VERSION ""

NS_ :

BS_:

BU_: GFM2_BCCMB ACCMB GFM3_DCACB FHCM SOBDMB_AWDC DCACA_GAS DCACA_HEV DCDC_LISB BCMC_CPDB DCMR_EAWD DCMR_ELSD BECMB_EPM PACM GFM_CPLR OBCC AFCM SOBDM_BCCM GWM _delete BCM ACCM GFM2_UIM ICM DCDC_HEV BECM SOBDMD_AHCM_PTC GENERIC TSTR

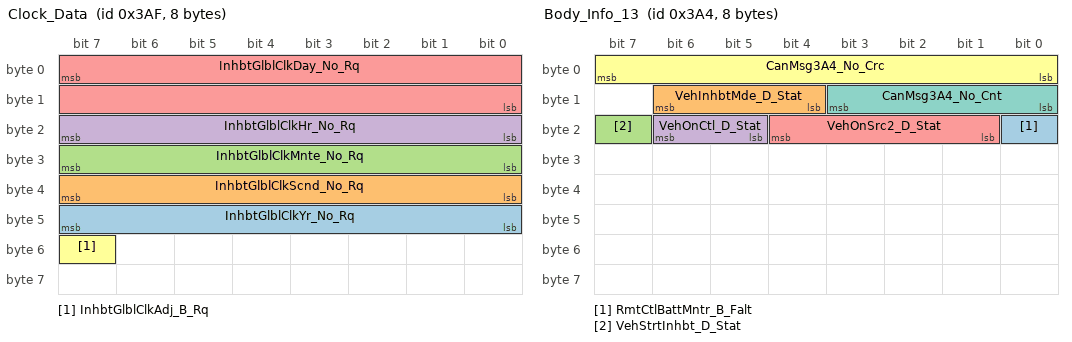
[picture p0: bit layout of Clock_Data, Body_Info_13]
BO_ 943 Clock_Data: 8 GWM
 SG_ InhbtGlblClkYr_No_Rq : 47|8@0+ (1,2000) [2000|2255] "year"  BCM
 SG_ InhbtGlblClkScnd_No_Rq : 39|8@0+ (1,0) [0|255] "second"  BCM
 SG_ InhbtGlblClkMnte_No_Rq : 31|8@0+ (1,0) [0|255] "minute"  BCM
 SG_ InhbtGlblClkHr_No_Rq : 23|8@0+ (1,0) [0|255] "hour"  BCM
 SG_ InhbtGlblClkDay_No_Rq : 7|16@0+ (1,0) [0|65535] "julian day"  BCM
 SG_ InhbtGlblClkAdj_B_Rq : 55|1@0+ (1,0) [0|1] "SED"  BCM

BO_ 932 Body_Info_13: 8 BCM
 SG_ RmtCtlBattMntr_B_Falt : 16|1@0+ (1,0) [0|1] "SED"  GWM
 SG_ VehInhbtMde_D_Stat : 14|3@0+ (1,0) [0|7] "SED"  GWM
 SG_ VehStrtInhbt_D_Stat : 23|1@0+ (1,0) [0|1] "SED"  BCMC_CPDB,GWM,PACM
 SG_ VehOnCtl_D_Stat : 22|2@0+ (1,0) [0|3] "SED"  BCMC_CPDB,GWM,PACM
 SG_ VehOnSrc2_D_Stat : 20|4@0+ (1,0) [0|15] "SED"  BCMC_CPDB,GWM
 SG_ CanMsg3A4_No_Crc : 7|8@0+ (1,0) [0|255] "Unitless"  GWM
 SG_ CanMsg3A4_No_Cnt : 11|4@0+ (1,0) [0|15] "Unitless"  GWM

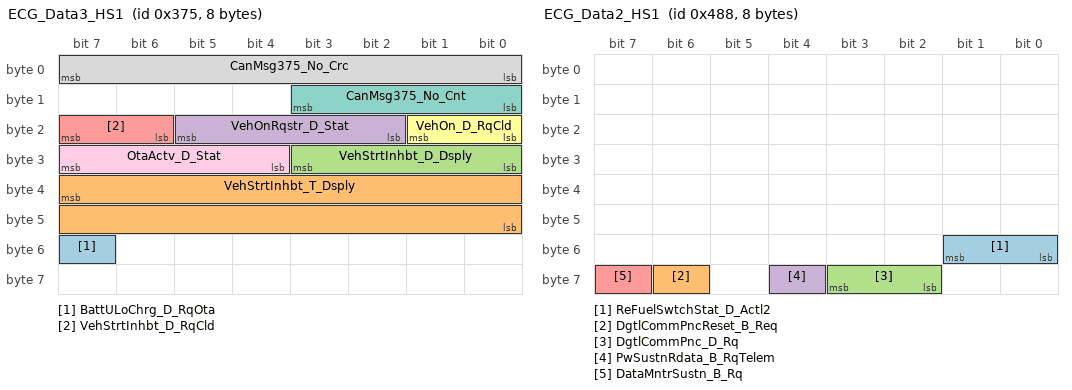
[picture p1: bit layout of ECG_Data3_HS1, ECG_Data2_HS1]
BO_ 885 ECG_Data3_HS1: 8 GWM
 SG_ BattULoChrg_D_RqOta : 55|1@0+ (1,0) [0|1] "SED"  BCM
 SG_ VehStrtInhbt_T_Dsply : 39|16@0+ (1,0) [0|65535] "second"  GENERIC
 SG_ VehStrtInhbt_D_Dsply : 27|4@0+ (1,0) [0|15] "SED"  GENERIC
 SG_ VehOnRqstr_D_Stat : 21|4@0+ (1,0) [0|15] "SED"  BCM
 SG_ VehStrtInhbt_D_RqCld : 23|2@0+ (1,0) [0|3] "SED"  BCM
 SG_ VehOn_D_RqCld : 17|2@0+ (1,0) [0|3] "SED"  BCM
 SG_ CanMsg375_No_Cnt : 11|4@0+ (1,0) [0|15] "unitless"  BCM
 SG_ CanMsg375_No_Crc : 7|8@0+ (1,0) [0|255] "unitless"  BCM
 SG_ OtaActv_D_Stat : 31|4@0+ (1,0) [0|15] "SED"  BCM

BO_ 159 OBCC_ECG_Word_Tx: 8 OBCC
 SG_ OBCC_ECG_Word_Tx : 7|64@0+ (1,0) [0|1.84467440737096E+019] "unitless"  GWM

BO_ 151 ECG_OBCC_Word_Tx: 8 GWM
 SG_ ECG_OBCC_Word_Tx : 7|64@0+ (1,0) [0|1.84467440737096E+019] "unitless"  OBCC

BO_ 1160 ECG_Data2_HS1: 8 GWM
 SG_ ReFuelSwtchStat_D_Actl2 : 49|2@0+ (1,0) [0|3] "SED"  GENERIC
 SG_ DgtlCommPncReset_B_Req : 62|1@0+ (1,0) [0|1] "SED"  OBCC
 SG_ DgtlCommPnc_D_Rq : 59|2@0+ (1,0) [0|3] "SED"  OBCC
 SG_ PwSustnRdata_B_RqTelem : 60|1@0+ (1,0) [0|1] "SED"  BECM,DCDC_HEV,SOBDM_BCCM
 SG_ DataMntrSustn_B_Rq : 63|1@0+ (1,0) [0|1] "SED"  BECM,DCDC_HEV,SOBDM_BCCM

BO_ 2612087000 PARSEDPushFcGWMtoBCM: 8 GWM
 SG_ PARSEDPushFcGWM_ECGtoBCM : 7|29@0+ (1,0) [0|536870911] "unitless"  BCM

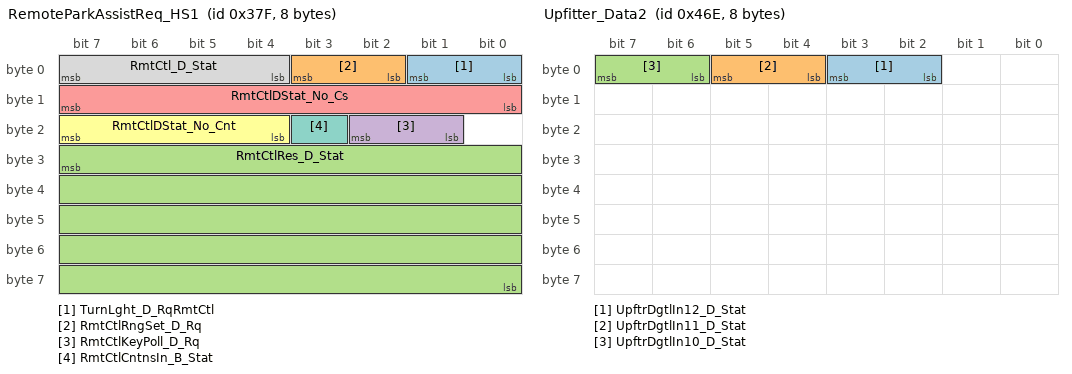
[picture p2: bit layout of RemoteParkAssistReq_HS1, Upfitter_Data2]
BO_ 895 RemoteParkAssistReq_HS1: 8 GWM
 SG_ TurnLght_D_RqRmtCtl : 1|2@0+ (1,0) [0|3] "SED"  BCM
 SG_ RmtCtlRngSet_D_Rq : 3|2@0+ (1,0) [0|3] "SED"  BCM
 SG_ RmtCtlRes_D_Stat : 31|40@0+ (1,0) [0|1099511627775] "unitless"  BCM
 SG_ RmtCtlKeyPoll_D_Rq : 18|2@0+ (1,0) [0|3] "SED"  BCM
 SG_ RmtCtlDStat_No_Cs : 15|8@0+ (1,0) [0|255] "Unitless"  BCM
 SG_ RmtCtlDStat_No_Cnt : 23|4@0+ (1,0) [0|15] "Unitless"  BCM
 SG_ RmtCtlCntnsIn_B_Stat : 19|1@0+ (1,0) [0|1] "SED"  BCM
 SG_ RmtCtl_D_Stat : 7|4@0+ (1,0) [0|15] "SED"  BCM

BO_ 542 LocationServices_3_HS1: 8 GWM
 SG_ LocationServices_3 : 7|64@0+ (1,0) [0|1.84467440737096E+019] "unitless" Vector__XXX

BO_ 1134 Upfitter_Data2: 8 GFM2_UIM
 SG_ UpftrDgtlIn12_D_Stat : 3|2@0+ (1,0) [0|3] "SED"  GWM
 SG_ UpftrDgtlIn11_D_Stat : 5|2@0+ (1,0) [0|3] "SED"  GWM
 SG_ UpftrDgtlIn10_D_Stat : 7|2@0+ (1,0) [0|3] "SED"  GWM

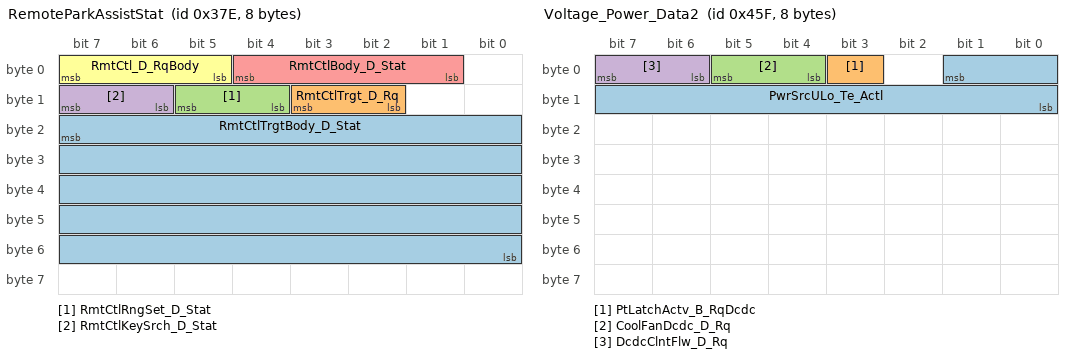
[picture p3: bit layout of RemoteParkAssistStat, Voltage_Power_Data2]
BO_ 894 RemoteParkAssistStat: 8 BCM
 SG_ RmtCtlTrgtBody_D_Stat : 23|40@0+ (1,0) [0|1099511627775] "unitless"  GWM
 SG_ RmtCtlTrgt_D_Rq : 11|2@0+ (1,0) [0|3] "SED"  GWM
 SG_ RmtCtlRngSet_D_Stat : 13|2@0+ (1,0) [0|3] "SED"  GWM
 SG_ RmtCtlKeySrch_D_Stat : 15|2@0+ (1,0) [0|3] "SED"  GWM
 SG_ RmtCtlBody_D_Stat : 4|4@0+ (1,0) [0|15] "SED"  GWM
 SG_ RmtCtl_D_RqBody : 7|3@0+ (1,0) [0|7] "SED"  GWM

BO_ 515 PowertrainData_12_HS1: 8 GWM
 SG_ PtIgnSwtch_D_Stat : 7|2@0+ (1,0) [0|3] "SED"  BCM

BO_ 1119 Voltage_Power_Data2: 8 DCDC_HEV
 SG_ PwrSrcULo_Te_Actl : 1|10@0+ (0.5,-50) [-50|460.5] "degC"  GWM
 SG_ PtLatchActv_B_RqDcdc : 3|1@0+ (1,0) [0|1] "SED"  GWM
 SG_ CoolFanDcdc_D_Rq : 5|2@0+ (1,0) [0|3] "SED"  GWM,BECM
 SG_ DcdcClntFlw_D_Rq : 7|2@0+ (1,0) [0|3] "SED"  SOBDMB_AWDC,GWM,BECM

BO_ 1827 TesterPhysicalReqBECMB_EPM: 8 TSTR
 SG_ TesterPhysicalReqBECMB_EPM : 7|64@0+ (1,0) [0|1.84467E+019] "unitless"  BECMB_EPM

BO_ 1835 TesterPhysicalResBECMB_EPM: 8 BECMB_EPM
 SG_ TesterPhysicalResBECMB_EPM : 7|64@0+ (1,0) [0|1.84467E+019] "unitless"  TSTR

BO_ 1110 Power_Stat: 8 BECMB_EPM
 SG_ RstrnMdulePw_D_Falt : 7|2@0+ (1,0) [0|3] "SED"  GWM

BO_ 1036 PedestrianAlert_Data: 8 PACM
 SG_ PdstrnAlrt_B_Falt : 7|1@0+ (1,0) [0|1] "SED"  GWM

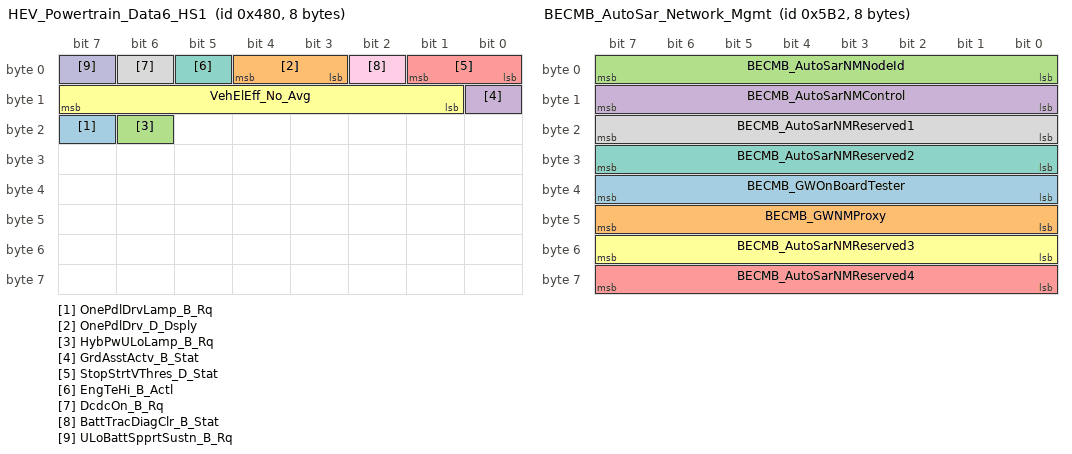
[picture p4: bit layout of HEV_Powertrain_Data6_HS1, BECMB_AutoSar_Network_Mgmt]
BO_ 1152 HEV_Powertrain_Data6_HS1: 8 GWM
 SG_ OnePdlDrvLamp_B_Rq : 23|1@0+ (1,0) [0|1] "SED"  GENERIC
 SG_ OnePdlDrv_D_Dsply : 4|2@0+ (1,0) [0|3] "SED"  GENERIC
 SG_ HybPwULoLamp_B_Rq : 22|1@0+ (1,0) [0|1] "SED"  DCDC_HEV
 SG_ GrdAsstActv_B_Stat : 8|1@0+ (1,0) [0|1] "SED" Vector__XXX
 SG_ StopStrtVThres_D_Stat : 1|2@0+ (1,0) [0|3] "SED"  GENERIC
 SG_ VehElEff_No_Avg : 15|7@0+ (10,-100) [-100|1150] "watt*hr/km" Vector__XXX
 SG_ EngTeHi_B_Actl : 5|1@0+ (1,0) [0|1] "SED" Vector__XXX
 SG_ DcdcOn_B_Rq : 6|1@0+ (1,0) [0|1] "SED"  DCDC_LISB,DCDC_HEV
 SG_ BattTracDiagClr_B_Stat : 2|1@0+ (1,0) [0|1] "SED"  BECM
 SG_ ULoBattSpprtSustn_B_Rq : 7|1@0+ (1,0) [0|1] "SED"  DCDC_LISB,BCMC_CPDB,BCM,BECM,DCDC_HEV,SOBDM_BCCM

BO_ 518 DifferentialCtrlData_1: 8 DCMR_ELSD
 SG_ LsdCluPlate_Te_Est : 23|9@0+ (1,-40) [-40|470] "degC"  GWM
 SG_ RearDiffLck_Tq_Actl2 : 7|14@0+ (1,0) [0|16381] "Nm"  GWM

BO_ 1458 BECMB_AutoSar_Network_Mgmt: 8 BECMB_EPM
 SG_ BECMB_GWOnBoardTester : 39|8@0+ (1,0) [0|255] "unitless"  BCM,GWM
 SG_ BECMB_GWNMProxy : 47|8@0+ (1,0) [0|255] "unitless"  BCM,GWM
 SG_ BECMB_AutoSarNMNodeId : 7|8@0+ (1,0) [0|255] "unitless"  GWM,BCM
 SG_ BECMB_AutoSarNMControl : 15|8@0+ (1,0) [0|255] "unitless"  BCM,GWM
 SG_ BECMB_AutoSarNMReserved4 : 63|8@0+ (1,0) [0|255] "unitless"  BCM,GWM
 SG_ BECMB_AutoSarNMReserved3 : 55|8@0+ (1,0) [0|255] "unitless"  BCM,GWM
 SG_ BECMB_AutoSarNMReserved2 : 31|8@0+ (1,0) [0|255] "unitless"  GWM,BCM
 SG_ BECMB_AutoSarNMReserved1 : 23|8@0+ (1,0) [0|255] "unitless"  GWM,BCM

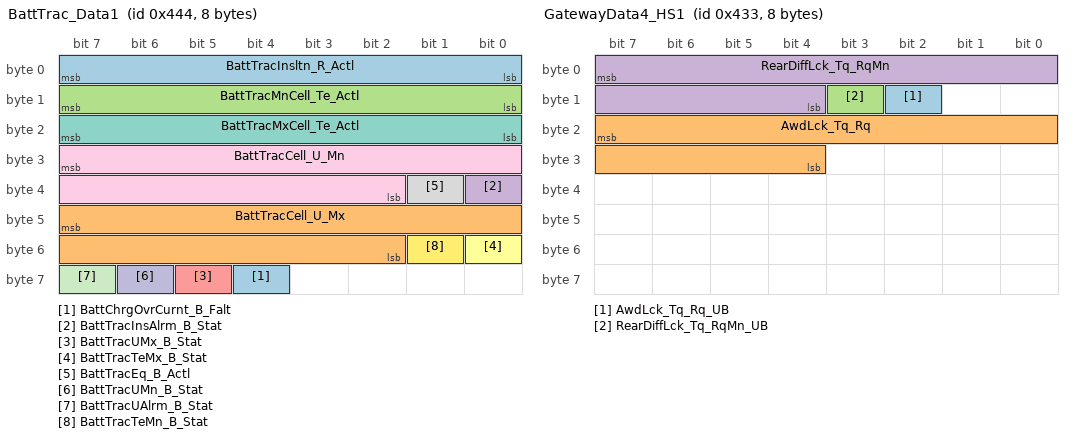
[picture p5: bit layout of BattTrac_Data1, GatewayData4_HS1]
BO_ 1092 BattTrac_Data1: 8 BECM
 SG_ BattChrgOvrCurnt_B_Falt : 60|1@0+ (1,0) [0|1] "SED"  OBCC
 SG_ BattTracCell_U_Mx : 47|14@0+ (0.001,0) [0|16.382] "volt"  GWM,OBCC
 SG_ BattTracMnCell_Te_Actl : 15|8@0+ (1,-40) [-40|213] "degC"  GWM,OBCC
 SG_ BattTracInsAlrm_B_Stat : 32|1@0+ (1,0) [0|1] "SED"  GWM
 SG_ BattTracUMx_B_Stat : 61|1@0+ (1,0) [0|1] "SED"  GWM,OBCC
 SG_ BattTracTeMx_B_Stat : 48|1@0+ (1,0) [0|1] "SED"  GWM
 SG_ BattTracMxCell_Te_Actl : 23|8@0+ (1,-40) [-40|213] "degC"  GWM,OBCC
 SG_ BattTracEq_B_Actl : 33|1@0+ (1,0) [0|1] "SED"  GWM
 SG_ BattTracCell_U_Mn : 31|14@0+ (0.001,0) [0|16.382] "volt"  GWM,OBCC
 SG_ BattTracUMn_B_Stat : 62|1@0+ (1,0) [0|1] "SED"  GWM,OBCC
 SG_ BattTracUAlrm_B_Stat : 63|1@0+ (1,0) [0|1] "SED"  GWM
 SG_ BattTracTeMn_B_Stat : 49|1@0+ (1,0) [0|1] "SED"  GWM
 SG_ BattTracInsltn_R_Actl : 7|8@0+ (6000,0) [0|1524000] "ohm"  GWM

BO_ 1075 GatewayData4_HS1: 8 GWM
 SG_ AwdLck_Tq_Rq_UB : 10|1@0+ (1,0) [0|1] "SED"  DCMR_ELSD
 SG_ AwdLck_Tq_Rq : 23|12@0+ (1,0) [0|4093] "Nm"  DCMR_ELSD
 SG_ RearDiffLck_Tq_RqMn_UB : 11|1@0+ (1,0) [0|1] "SED"  DCMR_ELSD
 SG_ RearDiffLck_Tq_RqMn : 7|12@0+ (4,0) [0|16376] "Nm"  DCMR_ELSD

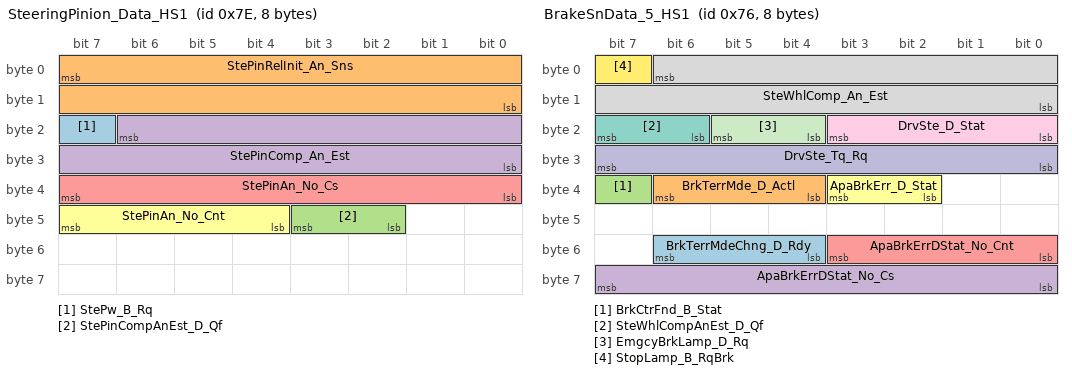
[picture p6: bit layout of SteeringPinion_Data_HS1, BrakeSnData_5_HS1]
BO_ 126 SteeringPinion_Data_HS1: 8 GWM
 SG_ StePw_B_Rq : 23|1@0+ (1,0) [0|1] "SED"  GENERIC
 SG_ StePinRelInit_An_Sns : 7|16@0+ (0.1,-3200) [-3200|3353.3] "degrees"  GENERIC
 SG_ StePinCompAnEst_D_Qf : 43|2@0+ (1,0) [0|3] "SED"  BCM,DCMR_ELSD
 SG_ StePinComp_An_Est : 22|15@0+ (0.1,-1600) [-1600|1676.7] "degrees"  BCM,DCMR_ELSD
 SG_ StePinAn_No_Cs : 39|8@0+ (1,0) [0|255] "Unitless"  GENERIC
 SG_ StePinAn_No_Cnt : 47|4@0+ (1,0) [0|15] "unitless"  GENERIC

BO_ 1872 TesterPhysicalReqPACM: 8 TSTR
 SG_ TesterPhysicalReqPACM : 7|64@0+ (1,0) [0|1.84467E+019] "unitless"  PACM

BO_ 1880 TesterPhysicalResPACM: 8 PACM
 SG_ TesterPhysicalResPACM : 7|64@0+ (1,0) [0|1.84467E+019] "unitless"  TSTR

BO_ 118 BrakeSnData_5_HS1: 8 GWM
 SG_ BrkTerrMdeChng_D_Rdy : 54|3@0+ (1,0) [0|7] "SED"  GENERIC
 SG_ BrkTerrMde_D_Actl : 38|3@0+ (1,0) [0|7] "SED"  GENERIC
 SG_ BrkCtrFnd_B_Stat : 39|1@0+ (1,0) [0|1] "SED"  GENERIC
 SG_ ApaBrkErrDStat_No_Cs : 63|8@0+ (1,0) [0|255] "Unitless"  GENERIC
 SG_ ApaBrkErrDStat_No_Cnt : 51|4@0+ (1,0) [0|15] "Unitless"  GENERIC
 SG_ ApaBrkErr_D_Stat : 35|2@0+ (1,0) [0|3] "SED"  GENERIC
 SG_ SteWhlCompAnEst_D_Qf : 23|2@0+ (1,0) [0|3] "SED"  BCM
 SG_ SteWhlComp_An_Est : 6|15@0+ (0.1,-1600) [-1600|1676.7] "deg"  BCM
 SG_ DrvSte_D_Stat : 19|4@0+ (1,0) [0|15] "SED"  GENERIC
 SG_ DrvSte_Tq_Rq : 31|8@0+ (0.0625,-8) [-8|7.8125] "Nm"  GENERIC
 SG_ EmgcyBrkLamp_D_Rq : 21|2@0+ (1,0) [0|3] "SED"  BCM
 SG_ StopLamp_B_RqBrk : 7|1@0+ (1,0) [0|1] "SED"  BCMC_CPDB,GFM2_UIM,BCM

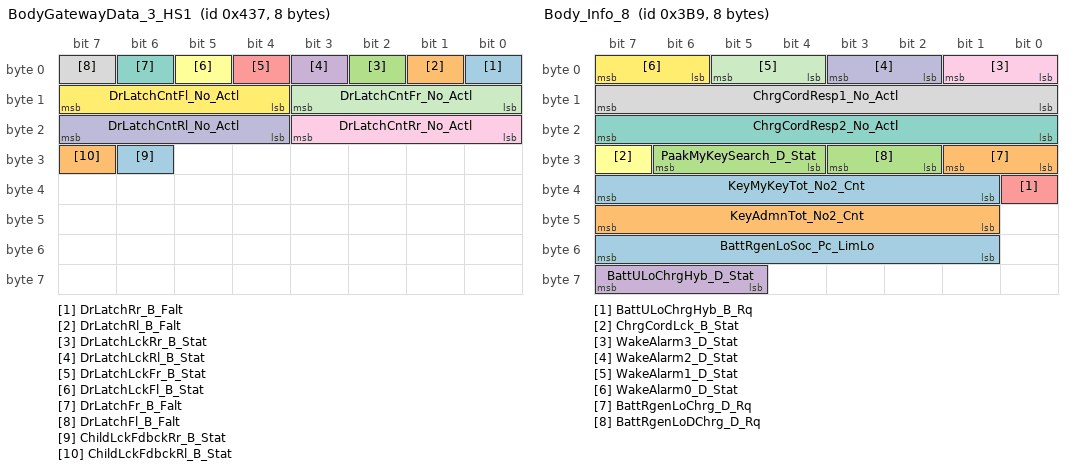
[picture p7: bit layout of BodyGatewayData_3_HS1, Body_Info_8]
BO_ 1079 BodyGatewayData_3_HS1: 8 GWM
 SG_ DrLatchRr_B_Falt : 0|1@0+ (1,0) [0|1] "SED"  BCM
 SG_ DrLatchRl_B_Falt : 1|1@0+ (1,0) [0|1] "SED"  BCM
 SG_ DrLatchLckRr_B_Stat : 2|1@0+ (1,0) [0|1] "SED"  BCM
 SG_ DrLatchLckRl_B_Stat : 3|1@0+ (1,0) [0|1] "SED"  BCM
 SG_ DrLatchLckFr_B_Stat : 4|1@0+ (1,0) [0|1] "SED"  BCM
 SG_ DrLatchLckFl_B_Stat : 5|1@0+ (1,0) [0|1] "SED"  BCM
 SG_ DrLatchFr_B_Falt : 6|1@0+ (1,0) [0|1] "SED"  BCM
 SG_ DrLatchFl_B_Falt : 7|1@0+ (1,0) [0|1] "SED"  BCM
 SG_ DrLatchCntRr_No_Actl : 19|4@0+ (1,0) [0|15] "unitless"  BCM
 SG_ DrLatchCntRl_No_Actl : 23|4@0+ (1,0) [0|15] "unitless"  BCM
 SG_ DrLatchCntFr_No_Actl : 11|4@0+ (1,0) [0|15] "unitless"  BCM
 SG_ DrLatchCntFl_No_Actl : 15|4@0+ (1,0) [0|15] "unitless"  BCM
 SG_ ChildLckFdbckRr_B_Stat : 30|1@0+ (1,0) [0|1] "SED"  BCM
 SG_ ChildLckFdbckRl_B_Stat : 31|1@0+ (1,0) [0|1] "SED"  BCM

BO_ 954 Body_Info_10: 8 BCM
 SG_ ExtLghtFront_D_RqBody : 61|2@0+ (1,0) [0|3] "SED"  GWM
 SG_ VehWlcmFrwlMde_D_Stat : 29|3@0+ (1,0) [0|7] "SED"  GWM
 SG_ CrtsyLghtRear_D_Stat : 63|2@0+ (1,0) [0|3] "SED"  GWM
 SG_ PosLghtFl_D_Stat : 51|2@0+ (1,0) [0|3] "SED"  GWM
 SG_ PosLghtFr_D_Stat : 49|2@0+ (1,0) [0|3] "SED"  GWM
 SG_ CargoLght_D_Stat : 55|2@0+ (1,0) [0|3] "SED"  GWM
 SG_ TlghtTestLght_D_Stat : 44|3@0+ (1,0) [0|7] "SED"  GWM
 SG_ LghtAmbDrvMde_B_Stat : 34|1@0+ (1,0) [0|1] "SED"  GWM
 SG_ KeylessIdl_B_Stat : 41|1@0+ (1,0) [0|1] "SED"  GWM
 SG_ PwRnngBoardPoll_D_Stat : 36|2@0+ (1,0) [0|3] "SED"  GWM
 SG_ GenericSwtch3_No_Actl : 15|3@0+ (1,0) [0|7] "unitless"  GWM
 SG_ GenericSwtch2_No_Actl : 4|3@0+ (1,0) [0|7] "unitless"  GWM
 SG_ GenericSwtch1_No_Actl : 7|3@0+ (1,0) [0|7] "unitless"  GWM
 SG_ PudSptLghtRight_D_Rq : 17|2@0+ (1,0) [0|3] "SED"  GWM
 SG_ PudSptLghtLeft_D_Rq : 19|2@0+ (1,0) [0|3] "SED"  GWM
 SG_ ExtLghtRight_D_Stat : 21|2@0+ (1,0) [0|3] "SED"  GWM
 SG_ PoliceDmngLvl_D_Stat : 39|3@0+ (1,0) [0|7] "SED"  GWM
 SG_ TrlrHitchLamp_D_Stat : 25|1@0+ (1,0) [0|1] "SED"  GWM
 SG_ LicPlateLght_B_Stat : 26|1@0+ (1,0) [0|1] "SED"  GWM
 SG_ TrukBedLght_B_Stat : 24|1@0+ (1,0) [0|1] "SED"  GWM
 SG_ VehWlcmFrwl_D_Stat : 31|2@0+ (1,0) [0|3] "SED"  GWM
 SG_ TlghtTestPrecnd_D_Stat : 47|3@0+ (1,0) [0|7] "SED"  GWM
 SG_ TlghtTest_D_Stat : 33|2@0+ (1,0) [0|3] "SED"  GWM
 SG_ ExtLghtRear_D_Stat : 23|2@0+ (1,0) [0|3] "SED"  GWM
 SG_ ExtLghtLeft_D_Stat : 9|2@0+ (1,0) [0|3] "SED"  GWM
 SG_ ExtLghtAlrt_B_Rq : 12|1@0+ (1,0) [0|1] "SED"  GWM
 SG_ ExtLght_D_Falt : 1|2@0+ (1,0) [0|3] "SED"  GWM
 SG_ ExtLghtFront_D_Stat : 11|2@0+ (1,0) [0|3] "SED"  GWM

BO_ 1118 BatteryCharge_Data2: 8 SOBDM_BCCM
 SG_ AcChrgRdy_B_Stat : 51|1@0+ (1,0) [0|1] "SED"  GWM,BECM
 SG_ DgtlCommGtwyMde_D_Rq : 48|4@0+ (1,0) [0|15] "SED"  GWM,OBCC
 SG_ ExtChrgNowButtn_B_Rq : 49|1@0+ (1,0) [0|1] "SED"  GWM
 SG_ CoolFanChrgr_D_Rq : 45|2@0+ (1,0) [0|3] "SED"  GWM,BECM
 SG_ ChrgrDcOvrVolt_B_Falt : 50|1@0+ (1,0) [0|1] "SED"  OBCC,GWM
 SG_ ChrgrDcOvrCurnt_B_Falt : 56|1@0+ (1,0) [0|1] "SED"  OBCC
 SG_ ChrgrPncEnbl_D_Stat : 58|2@0+ (1,0) [0|3] "SED"  GWM
 SG_ ChrgrClntFlw_D_Rq : 31|2@0+ (1,0) [0|3] "SED"  SOBDMB_AWDC,GWM,BECM
 SG_ PlgStatEvnt_B_Stat : 46|1@0+ (1,0) [0|1] "SED"  GWM,DCDC_LISB,DCDC_HEV,BECM
 SG_ ChrgrCnnctPwr_B_Stat : 47|1@0+ (1,0) [0|1] "SED"  GWM,BECM
 SG_ ChrgrAvailEvnt_B_Stat : 32|1@0+ (1,0) [0|1] "SED"  GWM,DCDC_LISB,DCDC_HEV,BECM
 SG_ ChrgrSrvcRqd_B_Rq : 0|1@0+ (1,0) [0|1] "SED"  GWM
 SG_ ChrgrS2Swtch_B_Stat : 42|1@0+ (1,0) [0|1] "SED"  GWM,OBCC
 SG_ ChrgChngEvnt_B_Stat : 33|1@0+ (1,0) [0|1] "SED"  GWM,DCDC_LISB,DCDC_HEV,BECM
 SG_ ChrgrCc2Cnnct_B_Falt : 59|1@0+ (1,0) [0|1] "SED"  GWM,OBCC
 SG_ ChrgPortDcTeMx_B_Falt : 60|1@0+ (1,0) [0|1] "SED"  GWM,OBCC
 SG_ ChrgCordLck_D_Stat : 7|3@0+ (1,0) [0|7] "SED"  GWM
 SG_ ChrgrInPwMde_D_Actl : 4|4@0+ (1,0) [0|15] "SED"  GWM,BECM,OBCC
 SG_ ChrgPortDrOpen_B_Stat : 43|1@0+ (1,0) [0|1] "SED"  GWM
 SG_ ChrgCordChlng2_No_Actl : 23|8@0+ (1,0) [0|255] "unitless"  GWM,BCM
 SG_ ChrgCordChlng1_No_Actl : 15|8@0+ (1,0) [0|255] "unitless"  GWM,BCM
 SG_ ChrgCrdLck_D_Falt : 41|2@0+ (1,0) [0|3] "SED"  GWM

BO_ 953 Body_Info_8: 8 BCM
 SG_ KeyMyKeyTot_No2_Cnt : 39|7@0+ (1,0) [0|127] "unitless"  GWM
 SG_ KeyAdmnTot_No2_Cnt : 47|7@0+ (1,0) [0|127] "unitless"  GWM
 SG_ PaakMyKeySearch_D_Stat : 30|3@0+ (1,0) [0|7] "SED"  GWM
 SG_ BattULoChrgHyb_D_Stat : 63|3@0+ (1,0) [0|7] "SED"  GWM
 SG_ BattULoChrgHyb_B_Rq : 32|1@0+ (1,0) [0|1] "SED"  GWM
 SG_ ChrgCordLck_B_Stat : 31|1@0+ (1,0) [0|1] "SED"  SOBDM_BCCM,GWM
 SG_ ChrgCordResp2_No_Actl : 23|8@0+ (1,0) [0|255] "unitless"  GWM,SOBDM_BCCM
 SG_ ChrgCordResp1_No_Actl : 15|8@0+ (1,0) [0|255] "unitless"  GWM,SOBDM_BCCM
 SG_ WakeAlarm3_D_Stat : 1|2@0+ (1,0) [0|3] "SED"  GWM,GENERIC
 SG_ WakeAlarm2_D_Stat : 3|2@0+ (1,0) [0|3] "SED"  GWM,GENERIC
 SG_ WakeAlarm1_D_Stat : 5|2@0+ (1,0) [0|3] "SED"  GWM,GENERIC
 SG_ WakeAlarm0_D_Stat : 7|2@0+ (1,0) [0|3] "SED"  GWM
 SG_ BattRgenLoSoc_Pc_LimLo : 55|7@0+ (1,0) [0|100] "percent"  DCDC_LISB
 SG_ BattRgenLoChrg_D_Rq : 25|2@0+ (1,0) [0|3] "SED"  DCDC_LISB,GWM
 SG_ BattRgenLoDChrg_D_Rq : 27|2@0+ (1,0) [0|3] "SED"  DCDC_LISB,GWM

BO_ 1112 Battery_Traction_6: 8 BECM
 SG_ BattTracIsoDis_B_Stat : 0|1@0+ (1,0) [0|1] "SED"  SOBDM_BCCM,GWM,OBCC
 SG_ BattTrac2_E_Max : 47|12@0+ (50,0) [0|204650] "watt*hour"  GWM
 SG_ BattTracHeat_D_Rq : 35|2@0+ (1,0) [0|3] "SED"  GWM
 SG_ BattTracDcFstSustn_B_Rq : 51|1@0+ (1,0) [0|1] "SED"  GWM
 SG_ BattDcCnnct_D_Cmd : 14|3@0+ (1,0) [0|7] "SED"  SOBDM_BCCM,GWM,OBCC
 SG_ BattTrac2_E_Avail : 31|12@0+ (50,0) [0|204650] "watt*hour"  GWM
 SG_ BattTracCnnct_D_Cmd : 18|3@0+ (1,0) [0|7] "SED"  SOBDMB_AWDC,SOBDM_BCCM,DCMR_EAWD,GWM
 SG_ BattTracHvilOpen_B_Stat : 8|1@0+ (1,0) [0|1] "SED"  GWM
 SG_ BattTracCoolLvl_D_Rq : 11|3@0+ (1,0) [0|7] "SED"  GWM
 SG_ CoolFanBatt_D_Rq : 23|5@0+ (1,0) [0|31] "unitless"  GWM
 SG_ BattTracTeSustn_B_Rq : 1|1@0+ (1,0) [0|1] "SED"  DCDC_LISB,GWM,BCMC_CPDB,BCM,DCDC_HEV,SOBDM_BCCM
 SG_ BattTracTeEvnt_B_Stat : 2|1@0+ (1,0) [0|1] "SED"  DCDC_LISB,GWM,DCDC_HEV,SOBDM_BCCM
 SG_ BattTracDcdcDis_B_Rq : 7|1@0+ (1,0) [0|1] "SED"  GWM
 SG_ BattChrgTrgtEvnt_B_Stat : 3|1@0+ (1,0) [0|1] "SED"  DCDC_LISB,GWM,DCDC_HEV,SOBDM_BCCM
 SG_ BattTracDiagClr_B_Rq : 15|1@0+ (1,0) [0|1] "SED"  GWM
 SG_ BattTracHazrd_D_Stat : 50|3@0+ (1,0) [0|7] "SED"  GWM
 SG_ BattTracChrgSustn_B_Rq : 4|1@0+ (1,0) [0|1] "SED"  DCDC_LISB,GWM,BCMC_CPDB,BCM,DCDC_HEV,SOBDM_BCCM
 SG_ HtrnClntPump_D_Stat : 6|2@0+ (1,0) [0|3] "SED"  DCDC_LISB,GWM,DCDC_HEV,SOBDM_BCCM
 SG_ BattTracDelta_Te_Actl : 63|8@0+ (0.5,-60) [-60|66.5] "degC" Vector__XXX
 SG_ BattTracClntPmp_D_Stat : 33|2@0+ (1,0) [0|3] "SED" Vector__XXX

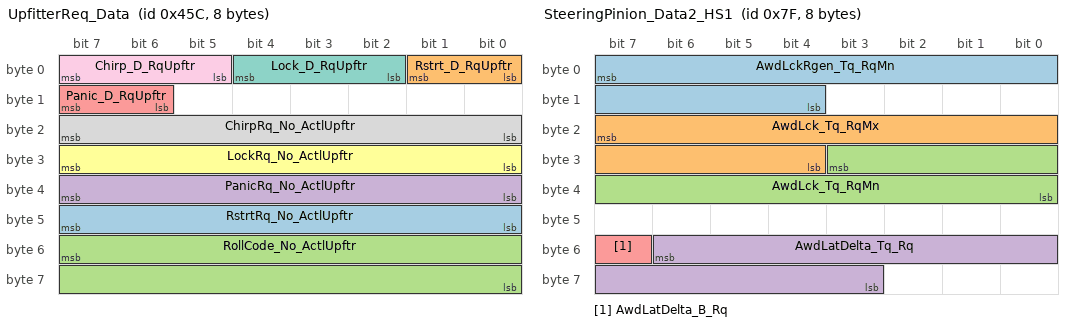
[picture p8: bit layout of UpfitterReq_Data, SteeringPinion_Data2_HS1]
BO_ 1116 UpfitterReq_Data: 8 GFM2_UIM
 SG_ RstrtRq_No_ActlUpftr : 47|8@0+ (1,0) [0|255] "unitless"  BCM
 SG_ Rstrt_D_RqUpftr : 1|2@0+ (1,0) [0|3] "SED"  BCM
 SG_ RollCode_No_ActlUpftr : 55|16@0+ (1,0) [0|65535] "unitless"  BCM
 SG_ PanicRq_No_ActlUpftr : 39|8@0+ (1,0) [0|255] "unitless"  BCM
 SG_ Panic_D_RqUpftr : 15|2@0+ (1,0) [0|3] "SED"  BCM
 SG_ LockRq_No_ActlUpftr : 31|8@0+ (1,0) [0|255] "unitless"  BCM
 SG_ Lock_D_RqUpftr : 4|3@0+ (1,0) [0|7] "SED"  BCM
 SG_ ChirpRq_No_ActlUpftr : 23|8@0+ (1,0) [0|255] "unitless"  BCM
 SG_ Chirp_D_RqUpftr : 7|3@0+ (1,0) [0|7] "SED"  BCM

BO_ 1144 MHT_EV_Wakeup: 8 GWM
 SG_ BattChrgTrgtSoC_D_Rq : 35|3@0+ (1,0) [0|7] "Percent"  GWM,BECM
 SG_ PreCondBatt_B_Actl : 32|1@0+ (1,0) [0|1] "SED"  GWM
 SG_ CabnEvapSovFront_B_Rq : 38|1@0+ (1,0) [0|1] "SED"  GWM,BCMC_CPDB
 SG_ HeatCoreSovRear_B_Rq : 36|1@0+ (1,0) [0|1] "SED"  GWM,BCMC_CPDB
 SG_ BattChlrSov_B_Rq : 39|1@0+ (1,0) [0|1] "SED"  GWM,BCMC_CPDB
 SG_ CabnEvapSovRear_B_Rq : 37|1@0+ (1,0) [0|1] "SED"  GWM,BCMC_CPDB
 SG_ BrkAppl_D_RqPt : 25|2@0+ (1,0) [0|3] "SED"  GWM
 SG_ BattClntVlvOvrrd_D_Rq : 31|2@0+ (1,0) [0|3] "SED"  GWM,BECM
 SG_ BattTracChillerOn_B_Rq : 27|1@0+ (1,0) [0|1] "SED"  GWM,BECM
 SG_ BattTracChiller_D_Stat : 29|2@0+ (1,0) [0|3] "SED"  GWM,BECM
 SG_ FstChrgCmplt_T_Est : 41|10@0+ (1,0) [0|1023] "minute"  OBCC
 SG_ ULoBattTrnsfrSustn_B_Rq : 43|1@0+ (1,0) [0|1] "SED"  SOBDM_BCCM,BCM,BECM,DCDC_HEV,GWM
 SG_ ULoBattTransfer_D_Stat : 46|3@0+ (1,0) [0|7] "SED"  BCM,GWM
 SG_ HtrnDcdcDis_B_Rq : 26|1@0+ (1,0) [0|1] "SED"  GWM
 SG_ HtrnCnnctPwr_B_Stat : 16|1@0+ (1,0) [0|1] "SED"  GWM,BECM,SOBDM_BCCM
 SG_ PtcHtr_D_Stat : 18|2@0+ (1,0) [0|3] "SED"  GWM
 SG_ BattChrgInhbt_D2_Rq : 63|3@0+ (1,0) [0|7] "SED"  BECM,SOBDM_BCCM
 SG_ WakeAlarm0_B_Typ : 21|1@0+ (1,0) [0|1] "SED"  GWM,BCM
 SG_ WakeAlarm0_T_Rq : 7|15@0+ (1,0) [0|32767] "minute"  GWM,BCM
 SG_ BattTracClimtDis_B_Stat : 42|1@0+ (1,0) [0|1] "SED"  GENERIC,GWM
 SG_ HtrnClntFlw_D_Rq : 20|2@0+ (1,0) [0|3] "SED"  SOBDMB_AWDC,GWM,DCMR_EAWD,BECM
 SG_ BattTracDrvSustn_B_Rq : 8|1@0+ (1,0) [0|1] "SED"  DCDC_LISB,GWM,BCMC_CPDB,BCM,BECM,DCDC_HEV,SOBDM_BCCM
 SG_ CabinDrvSustn_B_Rq : 23|1@0+ (1,0) [0|1] "SED"  DCDC_LISB,GWM,BCMC_CPDB,BCM,BECM,DCDC_HEV,SOBDM_BCCM
 SG_ BattTracClntVlv_B_Rq : 47|1@0+ (1,0) [0|1] "SED"  GWM,BCMC_CPDB
 SG_ ChrgNowEvnt_B_Stat : 22|1@0+ (1,0) [0|1] "SED"  DCDC_LISB,GWM,BECM,DCDC_HEV,SOBDM_BCCM

BO_ 127 SteeringPinion_Data2_HS1: 8 GWM
 SG_ AwdLckRgen_Tq_RqMn : 7|12@0+ (1,-4095) [-4095|0] "Nm"  GENERIC,SOBDMB_AWDC
 SG_ AwdLck_Tq_RqMx : 23|12@0+ (1,0) [0|4095] "Nm"  SOBDMB_AWDC,DCMR_EAWD
 SG_ AwdLck_Tq_RqMn : 27|12@0+ (1,0) [0|4095] "Nm"  SOBDMB_AWDC,DCMR_EAWD
 SG_ AwdLatDelta_Tq_Rq : 54|12@0+ (2,-4095) [-4095|4095] "Nm"  GENERIC
 SG_ AwdLatDelta_B_Rq : 55|1@0+ (1,0) [0|1] "SED"  GENERIC

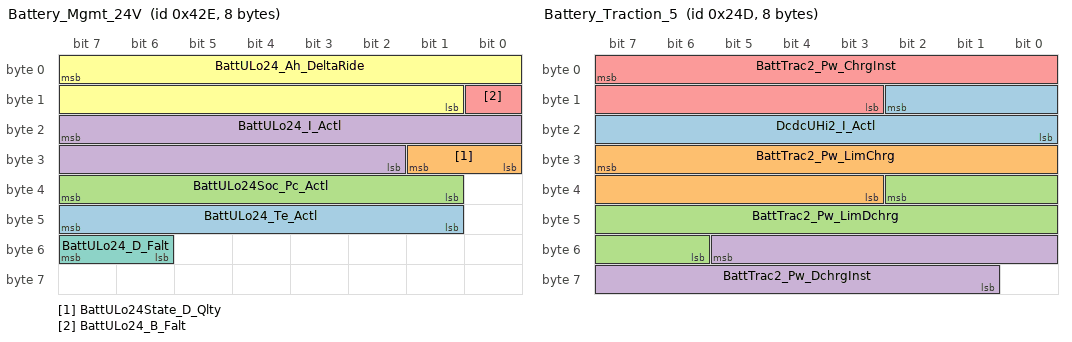
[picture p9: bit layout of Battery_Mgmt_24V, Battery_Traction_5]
BO_ 1070 Battery_Mgmt_24V: 8 BCM
 SG_ BattULo24_Te_Actl : 47|7@0+ (1,-40) [-40|86] "degC"  GWM
 SG_ BattULo24State_D_Qlty : 25|2@0+ (1,0) [0|3] "SED"  GWM
 SG_ BattULo24Soc_Pc_Actl : 39|7@0+ (1,0) [0|127] "percent"  GWM
 SG_ BattULo24_I_Actl : 23|14@0+ (0.0625,-512) [-512|511.875] "ampere"  GWM
 SG_ BattULo24_B_Falt : 8|1@0+ (1,0) [0|1] "SED"  GWM
 SG_ BattULo24_Ah_DeltaRide : 7|15@0+ (0.0078125,-100) [-100|155.9921875] "amperehour"  GWM
 SG_ BattULo24_D_Falt : 55|2@0+ (1,0) [0|3] "SED"  GWM

BO_ 589 Battery_Traction_5: 8 BECM
 SG_ DcdcUHi2_I_Actl : 10|11@0+ (0.1,0) [0|204.6] "ampere"  GWM
 SG_ BattTrac2_Pw_LimChrg : 31|13@0+ (50,0) [0|409550] "watts"  GWM
 SG_ BattTrac2_Pw_LimDchrg : 34|13@0+ (50,0) [0|409550] "watts"  GWM
 SG_ BattTrac2_Pw_DchrgInst : 53|13@0+ (50,0) [0|409550] "watts"  GWM
 SG_ BattTrac2_Pw_ChrgInst : 7|13@0+ (50,0) [0|409550] "watts"  GWM

BO_ 968 Cluster_Lighting_Rq_HS1: 8 GWM
 SG_ LnchCtl_N_Rq : 55|8@0+ (50,0) [0|12750] "rpm" Vector__XXX
 SG_ LnchCtl_D_Rq : 63|2@0+ (1,0) [0|3] "SED" Vector__XXX
 SG_ CurrentColor_CmdGage : 43|4@0+ (1,0) [0|15] "SED"  ICM
 SG_ BlendedColor_CmdGage : 25|2@0+ (1,0) [0|3] "SED"  ICM
 SG_ BlendColorRed_CmdGage : 47|4@0+ (1,0) [0|15] "SED"  ICM
 SG_ BlendColorGrn_CmdGage : 35|4@0+ (1,0) [0|15] "SED"  ICM
 SG_ BlendColorBlue_CmdGage : 39|4@0+ (1,0) [0|15] "SED"  ICM
 SG_ BrkDrvMde_D_Rq : 18|3@0+ (1,0) [0|7] "SED"  GENERIC
 SG_ Dimming_Level_Cmd : 1|2@0+ (1,0) [0|3] "SED"  GENERIC
 SG_ Current_Color_Cmd : 23|4@0+ (1,0) [0|15] "SED"  GENERIC
 SG_ BlendedColorRed_Cmd : 11|4@0+ (1,0) [0|15] "SED"  GENERIC
 SG_ BlendedColorGreen_Cmd : 15|4@0+ (1,0) [0|15] "SED"  GENERIC
 SG_ BlendedColorBlue_Cmd : 5|4@0+ (1,0) [0|15] "SED"  GENERIC
 SG_ BlendedColor_Cmd : 7|2@0+ (1,0) [0|3] "SED"  GENERIC
 SG_ SlMde_D_Rq : 27|2@0+ (1,0) [0|3] "SED" Vector__XXX
 SG_ IsaOffst_D_Rq : 31|4@0+ (1,0) [0|15] "SED" Vector__XXX
 SG_ SuspDrvMde_D_Rq : 61|3@0+ (1,0) [0|7] "SED"  GENERIC

BO_ 1081 GatewayData7_HS1: 8 GWM
 SG_ ChirpRq_No_ActlTrlr_UB : 35|1@0+ (1,0) [0|1] "SED"  BCM
 SG_ ChirpRq_No_ActlTrlr : 39|4@0+ (1,0) [0|15] "unitless"  BCM
 SG_ Chirp_D_RqTrlr_UB : 24|1@0+ (1,0) [0|1] "SED"  BCM
 SG_ Chirp_D_RqTrlr : 26|2@0+ (1,0) [0|3] "SED"  BCM
 SG_ RearPassWindowPos_UB : 8|1@0+ (1,0) [0|1] "SED"  BCM
 SG_ RearPassWindowPos : 11|3@0+ (1,0) [0|7] "SED"  BCM
 SG_ RearDriverWindowPos_UB : 12|1@0+ (1,0) [0|1] "SED"  BCM
 SG_ RearDriverWindowPos : 15|3@0+ (1,0) [0|7] "SED"  BCM
 SG_ PassWindowPosition_UB : 0|1@0+ (1,0) [0|1] "SED"  BCM
 SG_ PassWindowPosition : 3|3@0+ (1,0) [0|7] "SED"  BCM
 SG_ DriverWindowPosition_UB : 4|1@0+ (1,0) [0|1] "SED"  BCM
 SG_ DriverWindowPosition : 7|3@0+ (1,0) [0|7] "SED"  BCM
 SG_ ChrgCrdLckEnbl_B_Stat : 21|1@0+ (1,0) [0|1] "SED"  SOBDM_BCCM
 SG_ ChrgCrdLckEnbl_B_Stat_UB : 23|1@0+ (1,0) [0|1] "SED"  SOBDM_BCCM
 SG_ EcoInhbt_B_RqHvac_UB : 30|1@0+ (1,0) [0|1] "SED"  BCM
 SG_ EmgcyAsstActv_D_Stat_UB : 61|1@0+ (1,0) [0|1] "SED"  BCM
 SG_ EmgcyAsstActv_D_Stat : 63|2@0+ (1,0) [0|3] "SED"  BCM
 SG_ TrlrHitchLamp_D_Rq2_UB : 46|1@0+ (1,0) [0|1] "SED"  BCM
 SG_ TrlrHitchLamp_D_Rq2 : 47|1@0+ (1,0) [0|1] "SED"  BCM
 SG_ EcoInhbt_B_RqHvac : 31|1@0+ (1,0) [0|1] "SED"  BCM

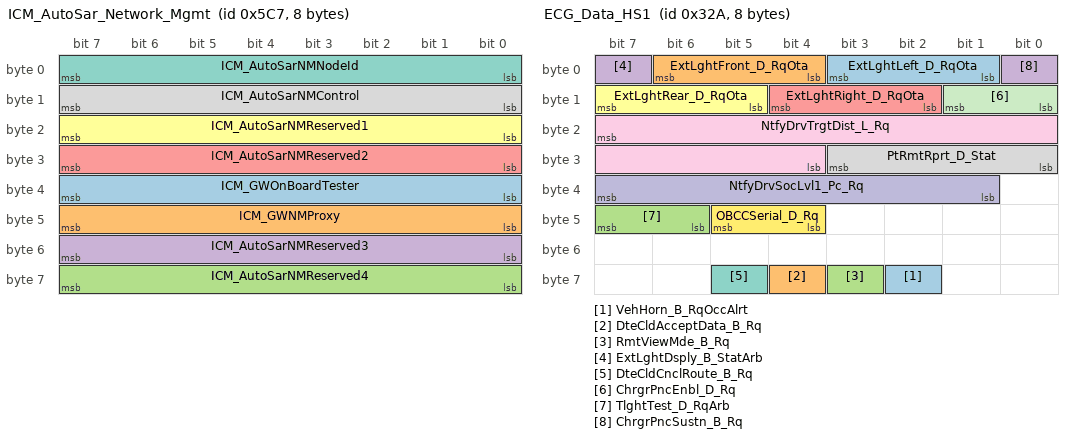
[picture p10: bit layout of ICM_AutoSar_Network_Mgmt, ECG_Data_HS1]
BO_ 1479 ICM_AutoSar_Network_Mgmt: 8 ICM
 SG_ ICM_GWOnBoardTester : 39|8@0+ (1,0) [0|255] "unitless"  GWM
 SG_ ICM_GWNMProxy : 47|8@0+ (1,0) [0|255] "unitless"  GWM
 SG_ ICM_AutoSarNMReserved4 : 63|8@0+ (1,0) [0|255] "unitless"  GWM
 SG_ ICM_AutoSarNMReserved3 : 55|8@0+ (1,0) [0|255] "unitless"  GWM
 SG_ ICM_AutoSarNMReserved2 : 31|8@0+ (1,0) [0|255] "unitless"  GWM
 SG_ ICM_AutoSarNMReserved1 : 23|8@0+ (1,0) [0|255] "unitless"  GWM
 SG_ ICM_AutoSarNMNodeId : 7|8@0+ (1,0) [0|255] "unitless"  GWM
 SG_ ICM_AutoSarNMControl : 15|8@0+ (1,0) [0|255] "unitless"  GWM

BO_ 1932 TesterPhysicalResICM: 8 ICM
 SG_ TesterPhysicalResICM : 7|64@0+ (1,0) [0|1.84467E+019] "unitless"  TSTR

BO_ 1924 TesterPhysicalReqICM: 8 TSTR
 SG_ TesterPhysicalReqICM : 7|64@0+ (1,0) [0|1.84467E+019] "unitless"  ICM

BO_ 829 Low_Voltage_Power_Dat2: 8 DCDC_HEV
 SG_ PwSrcULoMde2_D_Actl : 12|2@0+ (1,0) [0|3] "SED"  GWM,BECM
 SG_ DcdcUHi3_I_Actl : 7|11@0+ (0.1,0) [0|204.5] "ampere"  BECM,GWM

BO_ 910 CloudVehCtlData_Tp_Rq: 8 GWM
 SG_ CloudVehCtlData_Tp_Rq : 7|64@0+ (1,0) [0|1.84467440737096E+019] "unitless"  BCM

BO_ 911 CloudVehCtlData_Tp_Res: 8 BCM
 SG_ CloudVehCtlData_Tp_Res : 7|64@0+ (1,0) [0|1.84467440737096E+019] "unitless"  GWM

BO_ 2609984728 OTAPhysGWM_ECGtoOBCC: 8 GWM
 SG_ OTAPhysGWM_ECGtoOBCC : 7|29@0+ (1,0) [0|536870911] "unitless"  OBCC

BO_ 2610126925 OTAPhysOBCCtoGWM_ECG: 8 OBCC
 SG_ OTAPhysOBCCtoGWM_ECG : 7|29@0+ (1,0) [0|536870911] "unitless"  GWM

BO_ 1789 TesterPhysicalResOBCC: 8 OBCC
 SG_ TesterPhysicalResOBCC : 7|64@0+ (1,0) [0|1.84467E+019] "unitless"  TSTR

BO_ 1781 TesterPhysicalReqOBCC: 8 TSTR
 SG_ TesterPhysicalReqOBCC : 7|64@0+ (1,0) [0|1.84467E+019] "unitless"  OBCC

BO_ 2612224082 PARSEDPushBCMtoGWM_ECG: 8 BCM
 SG_ PARSEDPushBCMtoGWM_ECG : 7|29@0+ (1,0) [0|536870911] "unitless"  GWM

BO_ 2611175506 PARSEDPhysBCMtoGWM_ECG: 8 BCM
 SG_ PARSEDPhysBCMtoGWM_ECG : 7|29@0+ (1,0) [0|536870911] "unitless"  GWM

BO_ 2611038424 PARSEDPhysGWM_ECGtoBCM: 8 GWM
 SG_ PARSEDPhysGWM_ECGtoBCM : 7|29@0+ (1,0) [0|536870911] "unitless"  BCM

BO_ 2609989848 OTAPhysGWM_ECGtoBCM: 8 GWM
 SG_ OTAPhysGWM_ECGtoBCM : 7|29@0+ (1,0) [0|536870911] "unitless"  BCM

BO_ 2610126930 OTAPhysBCMtoGWM_ECG: 8 BCM
 SG_ OTAPhysBCMtoGWM_ECG : 7|29@0+ (1,0) [0|536870911] "unitless"  GWM

BO_ 1150 LocationServices_Data1_HS1: 8 GWM
 SG_ LocationServices_1 : 7|64@0+ (1,0) [0|1.84467440737096E+019] "unitless" Vector__XXX

BO_ 2610126914 OTAPhysBCMCtoGWM_ECG: 8 BCMC_CPDB
 SG_ OTAPhysBCMCtoGWM_ECG : 7|29@0+ (1,0) [0|536870911] "unitless"  GWM

BO_ 2609973464 OTAPhysGWM_ECGtoBCMC: 8 GWM
 SG_ OTAPhysGWM_ECGtoBCMC : 7|29@0+ (1,0) [0|536870911] "unitless"  BCMC_CPDB

BO_ 2612224062 PARSEDPushPACMtoGWM_ECG: 8 PACM
 SG_ PARSEDPushPACMtoGWM_ECG : 7|29@0+ (1,0) [0|536870911] "unitless"  GWM

BO_ 2611175486 PARSEDPhysPACMtoGWM_ECG: 8 PACM
 SG_ PARSEDPhysPACMtoGWM_ECG : 7|29@0+ (1,0) [0|536870911] "unitless"  GWM

BO_ 2611017944 PARSEDPhysGWM_ECGtoPACM: 8 GWM
 SG_ PARSEDPhysGWM_ECGtoPACM : 7|29@0+ (1,0) [0|536870911] "unitless"  PACM

BO_ 2612002008 PARSEDFuncGWM_ECG_HS1: 8 GWM
 SG_ PARSEDFuncGWM_ECG : 7|29@0+ (1,0) [0|536870911] "unitless"  SOBDMB_AWDC,ACCM,DCDC_LISB,BCM,BCMC_CPDB,PACM,OBCC,DCACA_GAS,DCACA_HEV

BO_ 2610953432 OTAFuncGWM_ECG_HS1: 8 GWM
 SG_ OTAFuncGWM_ECG : 7|29@0+ (1,0) [0|536870911] "unitless"  SOBDMB_AWDC,DCDC_LISB,BCM,BCMC_CPDB,PACM,OBCC,ACCM,DCACA_GAS,DCACA_HEV

BO_ 2611022040 PARSEDPhysGWM_ECGtoBCMC: 8 GWM
 SG_ PARSEDPhysGWM_ECGtoBCMC : 7|29@0+ (1,0) [0|536870911] "unitless"  BCMC_CPDB

BO_ 2612224066 PARSEDPushBCMCtoGWM_ECG: 8 BCMC_CPDB
 SG_ PARSEDPushBCMCtoGWM_ECG : 7|29@0+ (1,0) [0|536870911] "unitless"  GWM

BO_ 2609969368 OTAPhysGWM_ECGtoPACM: 8 GWM
 SG_ OTAPhysGWM_ECGtoPACM : 7|29@0+ (1,0) [0|536870911] "unitless"  PACM

BO_ 2610126910 OTAPhysPACMtoGWM_ECG: 8 PACM
 SG_ OTAPhysPACMtoGWM_ECG : 7|29@0+ (1,0) [0|536870911] "unitless"  GWM

BO_ 2611175490 PARSEDPhysBCMCtoGWM_ECG: 8 BCMC_CPDB
 SG_ PARSEDPhysBCMCtoGWM_ECG : 7|29@0+ (1,0) [0|536870911] "Unitless"  GWM

BO_ 811 APIM_Data_HS1: 8 GWM
 SG_ ExtLghtRight_D_RqMnu : 11|3@0+ (1,0) [0|7] "SED"  BCM
 SG_ ExtLghtRear_D_RqMnu : 14|3@0+ (1,0) [0|7] "SED"  BCM
 SG_ ExtLghtLeft_D_RqMnu : 1|3@0+ (1,0) [0|7] "SED"  BCM
 SG_ ExtLghtFront_D_RqMnu : 4|3@0+ (1,0) [0|7] "SED"  BCM
 SG_ SpeedoMajorUnit_D_Confg : 59|2@0+ (1,0) [0|3] "SED"  GENERIC
 SG_ ScMnSoc_Pc_RqMnu : 55|7@0+ (1,0) [0|125] "percent"  GENERIC
 SG_ ScEnbl_D_RqMnu : 57|2@0+ (1,0) [0|3] "SED"  GENERIC
 SG_ OnePdlDrvButtn_B_Falt : 16|1@0+ (1,0) [0|1] "SED"  GENERIC
 SG_ ExtLghtDsply_D_Stat : 7|3@0+ (1,0) [0|7] "SED"  GENERIC
 SG_ OnePdlDrvButtn_B_Stat : 48|1@0+ (1,0) [0|1] "SED"  GENERIC
 SG_ LongTermReset_B_RqMnu : 17|1@0+ (1,0) [0|1] "SED"  GENERIC
 SG_ GoTEditMnte_T_RqMnu : 63|4@0+ (1,0) [0|15] "SED"  GENERIC
 SG_ GoTEditHr_T_RqMnu : 44|5@0+ (1,0) [0|29] "SED"  GENERIC
 SG_ DistToStopover_L_Actl : 31|16@0+ (0.1,0) [0|6553.4] "kilometer"  GENERIC
 SG_ StopoverType_D_Stat : 47|3@0+ (1,0) [0|0] "SED"  GENERIC
 SG_ AutoLghtOvrrd_B_RqDrv : 8|1@0+ (1,0) [0|1] "SED"  BCM
 SG_ BecRleas_No_RqMnu : 23|3@0+ (1,0) [0|7] "unitless"  BCM
 SG_ TrnkFrontRleas_No_RqMnu : 20|3@0+ (1,0) [0|7] "unitless"  BCM

BO_ 810 ECG_Data_HS1: 8 GWM
 SG_ VehHorn_B_RqOccAlrt : 58|1@0+ (1,0) [0|1] "SED"  BCM
 SG_ DteCldAcceptData_B_Rq : 60|1@0+ (1,0) [0|1] "SED"  GENERIC
 SG_ RmtViewMde_B_Rq : 59|1@0+ (1,0) [0|1] "SED"  BCMC_CPDB
 SG_ ExtLghtDsply_B_StatArb : 7|1@0+ (1,0) [0|1] "SED"  BCM
 SG_ ExtLghtRight_D_RqOta : 12|3@0+ (1,0) [0|7] "SED"  BCM
 SG_ ExtLghtRear_D_RqOta : 15|3@0+ (1,0) [0|7] "SED"  BCM
 SG_ DteCldCnclRoute_B_Rq : 61|1@0+ (1,0) [0|1] "SED"  GENERIC
 SG_ PtRmtRprt_D_Stat : 27|4@0+ (1,0) [0|15] "SED"  GENERIC
 SG_ NtfyDrvTrgtDist_L_Rq : 23|12@0+ (0.1,0) [0|409.5] "Km"  GENERIC
 SG_ NtfyDrvSocLvl1_Pc_Rq : 39|7@0+ (1,0) [0|127] "%"  GENERIC
 SG_ ChrgrPncEnbl_D_Rq : 9|2@0+ (1,0) [0|3] "SED"  SOBDM_BCCM
 SG_ OBCCSerial_D_Rq : 45|2@0+ (1,0) [0|3] "SED"  OBCC
 SG_ ExtLghtLeft_D_RqOta : 3|3@0+ (1,0) [0|7] "SED"  BCM
 SG_ ExtLghtFront_D_RqOta : 6|3@0+ (1,0) [0|7] "SED"  BCM
 SG_ TlghtTest_D_RqArb : 47|2@0+ (1,0) [0|3] "SED"  BCM
 SG_ ChrgrPncSustn_B_Rq : 0|1@0+ (1,0) [0|1] "SED"  SOBDM_BCCM

BO_ 519 PowertrainData_8_HS1: 8 GWM
 SG_ RearDiffLck_Tq_Rq : 7|14@0+ (1,0) [0|16381] "Nm"  DCMR_ELSD

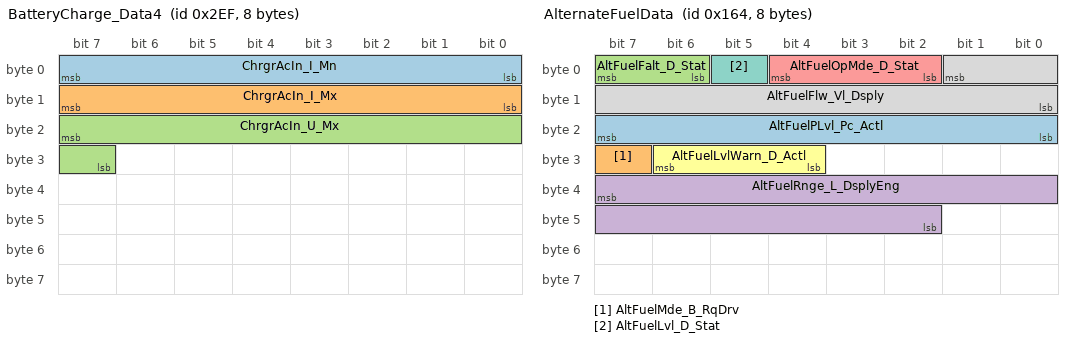
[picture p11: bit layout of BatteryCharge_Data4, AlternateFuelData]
BO_ 751 BatteryCharge_Data4: 8 SOBDM_BCCM
 SG_ ChrgrAcIn_I_Mn : 7|8@0+ (1,0) [0|255] "ampere"  OBCC
 SG_ ChrgrAcIn_I_Mx : 15|8@0+ (1,0) [0|255] "ampere"  OBCC
 SG_ ChrgrAcIn_U_Mx : 23|9@0+ (1,0) [0|511] "volt"  OBCC

BO_ 356 AlternateFuelData: 8 AFCM
 SG_ AltFuelPLvl_Pc_Actl : 23|8@0+ (0.471,0) [0|120.105] "percent"  GWM
 SG_ AltFuelMde_B_RqDrv : 31|1@0+ (1,0) [0|1] "SED"  GWM
 SG_ AltFuelFalt_D_Stat : 7|2@0+ (1,0) [0|3] "SED"  GWM
 SG_ AltFuelRnge_L_DsplyEng : 39|14@0+ (0.1,0) [0|1638.3] "kilometer"  GWM
 SG_ AltFuelOpMde_D_Stat : 4|3@0+ (1,0) [0|7] "SED"  GWM
 SG_ AltFuelLvlWarn_D_Actl : 30|3@0+ (1,0) [0|7] "SED"  GWM
 SG_ AltFuelLvl_D_Stat : 5|1@0+ (1,0) [0|1] "SED"  GWM
 SG_ AltFuelFlw_Vl_Dsply : 1|10@0+ (25,0) [0|25575] "micro_litre"  GWM

BO_ 2029 TesterPhysicalResAFCM: 8 AFCM
 SG_ TesterPhysicalResAFCM : 7|64@0+ (1,0) [0|1.84467E+019] "unitless"  TSTR

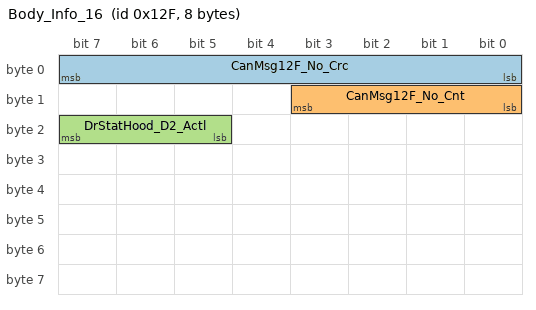
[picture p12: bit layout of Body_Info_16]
BO_ 303 Body_Info_16: 8 BCM
 SG_ CanMsg12F_No_Crc : 7|8@0+ (1,0) [0|255] "Unitless"  GWM,FHCM
 SG_ CanMsg12F_No_Cnt : 11|4@0+ (1,0) [0|15] "Unitless"  GWM,FHCM
 SG_ DrStatHood_D2_Actl : 23|3@0+ (1,0) [0|7] "SED"  GWM

BO_ 2612224034 PARSEDPushSOBDMBtoGWM_ECG: 8 SOBDMB_AWDC
 SG_ PARSEDPushSOBDMBtoGWM_ECG : 7|29@0+ (1,0) [0|536870911] "unitless"  GWM

BO_ 2612037848 PARSEDPushFcGWMECGtoSOBDMB: 8 GWM
 SG_ PARSEDPushFcGWMECGtoSOBDMB : 7|29@0+ (1,0) [0|536870911] "unitless"  SOBDMB_AWDC

BO_ 2611175458 PARSEDPhysSOBDMBtoGWM_ECG: 8 SOBDMB_AWDC
 SG_ PARSEDPhysSOBDMBtoGWM_ECG : 7|29@0+ (1,0) [0|536870911] "unitless"  GWM

BO_ 2610989272 PARSEDPhysGWM_ECGtoSOBDMB: 8 GWM
 SG_ PARSEDPhysGWM_ECGtoSOBDMB : 7|29@0+ (1,0) [0|536870911] "Unitless"  SOBDMB_AWDC

BO_ 2610126882 OTAPhysSOBDMBtoGWM_ECG: 8 SOBDMB_AWDC
 SG_ OTAPhysSOBDMBtoGWM_ECG : 7|29@0+ (1,0) [0|536870911] "unitless"  GWM

BO_ 2609940696 OTAPhysGWM_ECGtoSOBDMB: 8 GWM
 SG_ OTAPhysGWM_ECGtoSOBDMB : 7|29@0+ (1,0) [0|536870911] "unitless"  SOBDMB_AWDC

BO_TX_BU_ 1119 : DCDC_LISB,DCDC_HEV;
BO_TX_BU_ 1110 : BCM,BECMB_EPM;
CM_ BO_ 932 "NOTE: START BITS 8-11 MUST BE OPEN SPEC REQUIREMENT";
CM_ SG_ 932 CanMsg3A4_No_Crc "Signal not transmitted on gas and HEV variants.";
CM_ SG_ 932 CanMsg3A4_No_Cnt "Signal not transmitted on gas and HEV variants.";
CM_ BO_ 885 "NOTE: START BITS 8-11 MUST BE OPEN SPEC REQUIREMENT";
CM_ SG_ 159 OBCC_ECG_Word_Tx "MM ISO 15765-2 Message Catalogue RSE - AUDIO";
CM_ SG_ 151 ECG_OBCC_Word_Tx "MM ISO 15765-2 Message Catalogue AUDIO - RSE";
CM_ BO_ 1160 "some signals from HS4 0x22A TCU_EM in CGEA1.3";
CM_ SG_ 542 LocationServices_3 "Tx by HS3 APIM";
CM_ SG_ 1075 AwdLck_Tq_Rq "Signal not transmitted on programs that do not have AWD.";
CM_ SG_ 126 StePinRelInit_An_Sns "SASM will transmit these signals on vehicles with SASM and without PSCM.  SCCM will not Tx this signal when SASM is present.";
CM_ SG_ 126 StePinAn_No_Cs "Signal not transmitted on gas variants.";
CM_ SG_ 118 SteWhlCompAnEst_D_Qf "Legacy signal not supported, reserving bit locations for commodity BCM, PAM, RCM, APIM dbc files.  GWM to Tx Init value, no valid data. ";
CM_ SG_ 118 SteWhlComp_An_Est "Legacy signal not supported, reserving bit locations for commodity BCM, PAM, RCM, APIM dbc files.  GWM to Tx Init value, no valid data. ";
CM_ BO_ 1079 "Rolling counts indicate fresh data (DrLatchCntFl, Fr, Rl, Rr_No_Actl) and are updated each time new data is sent from a latch to BCM thru the GW. UBs not required.";
CM_ SG_ 1079 DrLatchCntRr_No_Actl "Rolling counts indicate fresh data (DrLatchCntxx) are updated each time new data is sent from a latch to BCM thru the GW. UBs not required.";
CM_ SG_ 1079 DrLatchCntRl_No_Actl "Rolling counts indicate fresh data (DrLatchCntxx) are updated each time new data is sent from a latch to BCM thru the GW. UBs not required.";
CM_ SG_ 1079 DrLatchCntFr_No_Actl "Rolling counts indicate fresh data (DrLatchCntxx) are updated each time new data is sent from a latch to BCM thru the GW. UBs not required.";
CM_ SG_ 1079 DrLatchCntFl_No_Actl "Rolling counts indicate fresh data (DrLatchCntxx) are updated each time new data is sent from a latch to BCM thru the GW. UBs not required.";
CM_ SG_ 954 GenericSwtch2_No_Actl "U625 Police Wig Wag feature";
CM_ SG_ 1112 BattTracClntPmp_D_Stat "48V mHEV: ECM_HEVDSL is Tx,  MHT HEV: PCM_HEV is Tx,  Powersplit HEV: SOBDMC_HPCM is Tx";
CM_ SG_ 910 CloudVehCtlData_Tp_Rq "MM ISO 15765-2 Message Catalogue RDISP2 - AUDIO";
CM_ SG_ 1150 LocationServices_1 "Tx by HS3 APIM";
CM_ SG_ 810 PtRmtRprt_D_Stat "Object.RemoteDataReport_St
";
CM_ SG_ 810 NtfyDrvTrgtDist_L_Rq "Object.SetTripRangeAlert_Rq
This signal is meant to provide the customer settings for the target distance remote notification";
CM_ SG_ 810 NtfyDrvSocLvl1_Pc_Rq "Object.SetCustomerLevelAlert_Rq
This signal is meant to provide the customer settings for the SOC remote notification.";
BA_DEF_ BO_  "FrameRouting" STRING ;
BA_DEF_ BO_  "FrameGatewayNetwork" STRING ;
BA_DEF_ BO_  "NetworkInitialization" ENUM  "No","Yes";
BA_DEF_ BO_  "FrameGatewayId" HEX 0 1407;
BA_DEF_ BO_  "EventRateOfChange" INT 10 10000;
BA_DEF_ BO_  "GenMsgStartDelayTime" INT 0 10000;
BA_DEF_ BO_  "GenMsgNrOfRepetition" INT 0 100;
BA_DEF_ BO_  "GenMsgDelayTime" INT 0 1000;
BA_DEF_ BO_  "GenMsgCycleTime" INT 0 100000;
BA_DEF_ BO_  "GenMsgSendType" ENUM  "FixedPeriodic","Event","EnabledPeriodic","NotUsed","NotUsed","EventPeriodic","NotUsed","NotUsed","NoMsgSendType";
BA_DEF_ SG_  "U_CD764_MY2022_Tx" ENUM  "No","Yes";
BA_DEF_ SG_  "U_U55X_MY2022_Tx" ENUM  "No","Yes";
BA_DEF_ SG_  "U_CD542_MY2021_Tx" ENUM  "No","Yes";
BA_DEF_ SG_  "ECGUsedTxSignal" ENUM  "No","Yes";
BA_DEF_ SG_  "U_T6_MCA_MY2020_Tx" ENUM  "No","Yes";
BA_DEF_ SG_  "U_P702_MY2021_Tx" ENUM  "No","Yes";
BA_DEF_ SG_  "U_CX727_MY2021_Tx" ENUM  "No","Yes";
BA_DEF_ SG_  "U_CD764_MY2022_Rx" ENUM  "No","Yes";
BA_DEF_ SG_  "U_U55X_MY2022_Rx" ENUM  "No","Yes";
BA_DEF_ SG_  "U_CD542_MY2021_Rx" ENUM  "No","Yes";
BA_DEF_ SG_  "ECGUsedRxSignal" ENUM  "No","Yes";
BA_DEF_ SG_  "U_T6_MCA_MY2020_Rx" ENUM  "No","Yes";
BA_DEF_ SG_  "U_P702_MY2021_Rx" ENUM  "No","Yes";
BA_DEF_ SG_  "U_CX727_MY2021_Rx" ENUM  "No","Yes";
BA_DEF_ SG_  "GenSigStartValue" HEX 0 268435455;
BA_DEF_ SG_  "MetaData" ENUM  "No","Yes";
BA_DEF_ SG_  "ContentDependant" ENUM  "No","Yes";
BA_DEF_ SG_  "GenSigStartValueInteger" INT 0 1000000000;
BA_DEF_ SG_  "UsedOnPgmDBC" ENUM  "No","Yes";
BA_DEF_ SG_  "WakeupSignal" ENUM  "No","Yes";
BA_DEF_ SG_  "GenSigInactiveValue" INT 0 100000;
BA_DEF_ SG_  "GenSigSendType" ENUM  "Cyclic","OnWrite","vector_leerstring","OnChange","vector_leerstring","IfActive","vector_leerstring","NoSigSendType";
BA_DEF_ BO_  "OvtpPushApplication" ENUM  "FALSE","TRUE";
BA_DEF_ BO_  "SCP_FreshnessValueLength" INT 0 512;
BA_DEF_ BO_  "SCP_FreshnessValueTxLength" INT 0 512;
BA_DEF_ BO_  "SCP_AuthInfoTxLength" INT 0 512;
BA_DEF_ BO_  "GenMsgRoutingTimeoutTime" INT 0 5000;
BA_DEF_ BO_  "MessageGateway" ENUM  "No","Yes";
BA_DEF_ BO_  "NmAsrMessage" ENUM  "No","Yes";
BA_DEF_ BO_  "TpApplType" STRING ;
BA_DEF_ BO_  "DiagState" ENUM  "No","Yes";
BA_DEF_ BO_  "TpTxIndex" INT 0 536870911;
BA_DEF_ BO_  "DiagRequest" ENUM  "No","Yes";
BA_DEF_ BO_  "DiagResponse" ENUM  "No","Yes";
BA_DEF_ BO_  "GenMsgILSupport" ENUM  "No","Yes";
BA_DEF_DEF_  "FrameRouting" "";
BA_DEF_DEF_  "FrameGatewayNetwork" "NONE";
BA_DEF_DEF_  "NetworkInitialization" "Yes";
BA_DEF_DEF_  "FrameGatewayId" 0;
BA_DEF_DEF_  "EventRateOfChange" 10000;
BA_DEF_DEF_  "GenMsgStartDelayTime" 0;
BA_DEF_DEF_  "GenMsgNrOfRepetition" 1;
BA_DEF_DEF_  "GenMsgDelayTime" 20;
BA_DEF_DEF_  "GenMsgCycleTime" 0;
BA_DEF_DEF_  "GenMsgSendType" "NoMsgSendType";
BA_DEF_DEF_  "U_CD764_MY2022_Tx" "No";
BA_DEF_DEF_  "U_U55X_MY2022_Tx" "No";
BA_DEF_DEF_  "U_CD542_MY2021_Tx" "No";
BA_DEF_DEF_  "ECGUsedTxSignal" "No";
BA_DEF_DEF_  "U_T6_MCA_MY2020_Tx" "No";
BA_DEF_DEF_  "U_P702_MY2021_Tx" "No";
BA_DEF_DEF_  "U_CX727_MY2021_Tx" "No";
BA_DEF_DEF_  "U_CD764_MY2022_Rx" "No";
BA_DEF_DEF_  "U_U55X_MY2022_Rx" "No";
BA_DEF_DEF_  "U_CD542_MY2021_Rx" "No";
BA_DEF_DEF_  "ECGUsedRxSignal" "No";
BA_DEF_DEF_  "U_T6_MCA_MY2020_Rx" "No";
BA_DEF_DEF_  "U_P702_MY2021_Rx" "No";
BA_DEF_DEF_  "U_CX727_MY2021_Rx" "No";
BA_DEF_DEF_  "GenSigStartValue" 0;
BA_DEF_DEF_  "MetaData" "No";
BA_DEF_DEF_  "ContentDependant" "No";
BA_DEF_DEF_  "GenSigStartValueInteger" 0;
BA_DEF_DEF_  "UsedOnPgmDBC" "Yes";
BA_DEF_DEF_  "WakeupSignal" "No";
BA_DEF_DEF_  "GenSigInactiveValue" 0;
BA_DEF_DEF_  "GenSigSendType" "NoSigSendType";
BA_DEF_DEF_  "OvtpPushApplication" "FALSE";
BA_DEF_DEF_  "SCP_FreshnessValueLength" 64;
BA_DEF_DEF_  "SCP_FreshnessValueTxLength" 11;
BA_DEF_DEF_  "SCP_AuthInfoTxLength" 53;
BA_DEF_DEF_  "GenMsgRoutingTimeoutTime" 0;
BA_DEF_DEF_  "MessageGateway" "No";
BA_DEF_DEF_  "NmAsrMessage" "No";
BA_DEF_DEF_  "TpApplType" "";
BA_DEF_DEF_  "DiagState" "No";
BA_DEF_DEF_  "TpTxIndex" 0;
BA_DEF_DEF_  "DiagRequest" "No";
BA_DEF_DEF_  "DiagResponse" "No";
BA_DEF_DEF_  "GenMsgILSupport" "Yes";
BA_ "GenMsgSendType" BO_ 943 1;
BA_ "GenMsgCycleTime" BO_ 932 200;
BA_ "GenMsgSendType" BO_ 932 0;
BA_ "GenMsgCycleTime" BO_ 885 200;
BA_ "GenMsgSendType" BO_ 885 0;
BA_ "TpTxIndex" BO_ 159 160;
BA_ "TpTxIndex" BO_ 151 160;
BA_ "GenMsgCycleTime" BO_ 1160 1000;
BA_ "GenMsgSendType" BO_ 1160 5;
BA_ "NetworkInitialization" BO_ 2612087000 0;
BA_ "GenMsgDelayTime" BO_ 2612087000 0;
BA_ "GenMsgSendType" BO_ 2612087000 1;
BA_ "OvtpPushApplication" BO_ 2612087000 1;
BA_ "TpTxIndex" BO_ 2612087000 463569112;
BA_ "FrameRouting" BO_ 895 "HS4_CAN,0x37F;";
BA_ "FrameGatewayNetwork" BO_ 895 "HS4_CAN";
BA_ "FrameGatewayId" BO_ 895 895;
BA_ "FrameRouting" BO_ 542 "HS4_CAN,0x21E;";
BA_ "FrameGatewayNetwork" BO_ 542 "HS4_CAN";
BA_ "FrameGatewayId" BO_ 542 542;
BA_ "GenMsgCycleTime" BO_ 1134 1000;
BA_ "GenMsgSendType" BO_ 1134 5;
BA_ "GenMsgCycleTime" BO_ 894 200;
BA_ "GenMsgSendType" BO_ 894 5;
BA_ "FrameRouting" BO_ 515 "FD1_CAN,0x203;";
BA_ "FrameGatewayNetwork" BO_ 515 "FD1_CAN";
BA_ "FrameGatewayId" BO_ 515 515;
BA_ "GenMsgCycleTime" BO_ 1119 1000;
BA_ "GenMsgSendType" BO_ 1119 5;
BA_ "NetworkInitialization" BO_ 1827 0;
BA_ "GenMsgDelayTime" BO_ 1827 0;
BA_ "GenMsgSendType" BO_ 1827 1;
BA_ "DiagRequest" BO_ 1827 1;
BA_ "GenMsgILSupport" BO_ 1827 0;
BA_ "NetworkInitialization" BO_ 1835 0;
BA_ "GenMsgDelayTime" BO_ 1835 0;
BA_ "GenMsgSendType" BO_ 1835 1;
BA_ "DiagResponse" BO_ 1835 1;
BA_ "GenMsgILSupport" BO_ 1835 0;
BA_ "GenMsgCycleTime" BO_ 1110 1000;
BA_ "GenMsgSendType" BO_ 1110 0;
BA_ "GenMsgCycleTime" BO_ 1036 1000;
BA_ "GenMsgSendType" BO_ 1036 5;
BA_ "FrameRouting" BO_ 1152 "FD1_CAN,0x480;";
BA_ "FrameGatewayNetwork" BO_ 1152 "FD1_CAN";
BA_ "FrameGatewayId" BO_ 1152 1152;
BA_ "GenMsgCycleTime" BO_ 518 50;
BA_ "GenMsgSendType" BO_ 518 0;
BA_ "NetworkInitialization" BO_ 1458 0;
BA_ "GenMsgCycleTime" BO_ 1458 1000;
BA_ "GenMsgSendType" BO_ 1458 0;
BA_ "NmAsrMessage" BO_ 1458 1;
BA_ "GenMsgILSupport" BO_ 1458 0;
BA_ "GenMsgCycleTime" BO_ 1092 1000;
BA_ "GenMsgSendType" BO_ 1092 0;
BA_ "GenMsgCycleTime" BO_ 1075 100;
BA_ "GenMsgSendType" BO_ 1075 0;
BA_ "GenMsgDelayTime" BO_ 126 10;
BA_ "GenMsgCycleTime" BO_ 126 20;
BA_ "GenMsgSendType" BO_ 126 0;
BA_ "GenMsgRoutingTimeoutTime" BO_ 126 30;
BA_ "MessageGateway" BO_ 126 1;
BA_ "NetworkInitialization" BO_ 1872 0;
BA_ "GenMsgDelayTime" BO_ 1872 0;
BA_ "GenMsgSendType" BO_ 1872 1;
BA_ "DiagRequest" BO_ 1872 1;
BA_ "GenMsgILSupport" BO_ 1872 0;
BA_ "NetworkInitialization" BO_ 1880 0;
BA_ "GenMsgDelayTime" BO_ 1880 0;
BA_ "GenMsgSendType" BO_ 1880 1;
BA_ "DiagResponse" BO_ 1880 1;
BA_ "GenMsgILSupport" BO_ 1880 0;
BA_ "FrameRouting" BO_ 118 "FD1_CAN,0x76;";
BA_ "FrameGatewayNetwork" BO_ 118 "FD1_CAN";
BA_ "FrameGatewayId" BO_ 118 118;
BA_ "GenMsgCycleTime" BO_ 1079 1000;
BA_ "GenMsgSendType" BO_ 1079 0;
BA_ "GenMsgCycleTime" BO_ 954 1000;
BA_ "GenMsgSendType" BO_ 954 5;
BA_ "GenMsgCycleTime" BO_ 1118 1000;
BA_ "GenMsgSendType" BO_ 1118 5;
BA_ "GenMsgCycleTime" BO_ 953 1000;
BA_ "GenMsgSendType" BO_ 953 5;
BA_ "GenMsgCycleTime" BO_ 1112 1000;
BA_ "GenMsgSendType" BO_ 1112 5;
BA_ "GenMsgCycleTime" BO_ 1116 1000;
BA_ "GenMsgSendType" BO_ 1116 5;
BA_ "FrameRouting" BO_ 1144 "FD1_CAN,0x478;";
BA_ "FrameGatewayNetwork" BO_ 1144 "FD1_CAN";
BA_ "FrameGatewayId" BO_ 1144 1144;
BA_ "FrameRouting" BO_ 127 "FD1_CAN,0x7F;";
BA_ "FrameGatewayNetwork" BO_ 127 "FD1_CAN";
BA_ "FrameGatewayId" BO_ 127 127;
BA_ "GenMsgDelayTime" BO_ 127 10;
BA_ "GenMsgCycleTime" BO_ 1070 40;
BA_ "GenMsgSendType" BO_ 1070 0;
BA_ "GenMsgCycleTime" BO_ 589 100;
BA_ "GenMsgSendType" BO_ 589 0;
BA_ "FrameRouting" BO_ 968 "HS3_CAN,0x3C8;";
BA_ "FrameGatewayNetwork" BO_ 968 "HS3_CAN";
BA_ "FrameGatewayId" BO_ 968 968;
BA_ "GenMsgCycleTime" BO_ 1081 1000;
BA_ "GenMsgSendType" BO_ 1081 5;
BA_ "NetworkInitialization" BO_ 1479 0;
BA_ "GenMsgCycleTime" BO_ 1479 1000;
BA_ "GenMsgSendType" BO_ 1479 0;
BA_ "NmAsrMessage" BO_ 1479 1;
BA_ "GenMsgILSupport" BO_ 1479 0;
BA_ "NetworkInitialization" BO_ 1932 0;
BA_ "GenMsgDelayTime" BO_ 1932 0;
BA_ "GenMsgSendType" BO_ 1932 1;
BA_ "DiagResponse" BO_ 1932 1;
BA_ "GenMsgILSupport" BO_ 1932 0;
BA_ "NetworkInitialization" BO_ 1924 0;
BA_ "GenMsgDelayTime" BO_ 1924 0;
BA_ "GenMsgSendType" BO_ 1924 1;
BA_ "DiagRequest" BO_ 1924 1;
BA_ "GenMsgILSupport" BO_ 1924 0;
BA_ "GenMsgCycleTime" BO_ 829 100;
BA_ "GenMsgSendType" BO_ 829 0;
BA_ "GenMsgSendType" BO_ 910 1;
BA_ "TpTxIndex" BO_ 910 161;
BA_ "GenMsgSendType" BO_ 911 1;
BA_ "TpTxIndex" BO_ 911 161;
BA_ "NetworkInitialization" BO_ 2609984728 0;
BA_ "GenMsgDelayTime" BO_ 2609984728 0;
BA_ "GenMsgSendType" BO_ 2609984728 1;
BA_ "TpTxIndex" BO_ 2609984728 462501080;
BA_ "NetworkInitialization" BO_ 2610126925 0;
BA_ "GenMsgDelayTime" BO_ 2610126925 0;
BA_ "GenMsgSendType" BO_ 2610126925 1;
BA_ "TpTxIndex" BO_ 2610126925 462501080;
BA_ "NetworkInitialization" BO_ 1789 0;
BA_ "GenMsgDelayTime" BO_ 1789 0;
BA_ "GenMsgSendType" BO_ 1789 1;
BA_ "DiagResponse" BO_ 1789 1;
BA_ "GenMsgILSupport" BO_ 1789 0;
BA_ "NetworkInitialization" BO_ 1781 0;
BA_ "GenMsgDelayTime" BO_ 1781 0;
BA_ "GenMsgSendType" BO_ 1781 1;
BA_ "DiagRequest" BO_ 1781 1;
BA_ "GenMsgILSupport" BO_ 1781 0;
BA_ "NetworkInitialization" BO_ 2612224082 0;
BA_ "GenMsgDelayTime" BO_ 2612224082 0;
BA_ "GenMsgSendType" BO_ 2612224082 1;
BA_ "OvtpPushApplication" BO_ 2612224082 1;
BA_ "TpTxIndex" BO_ 2612224082 463569112;
BA_ "NetworkInitialization" BO_ 2611175506 0;
BA_ "GenMsgDelayTime" BO_ 2611175506 0;
BA_ "GenMsgSendType" BO_ 2611175506 1;
BA_ "TpTxIndex" BO_ 2611175506 463554776;
BA_ "NetworkInitialization" BO_ 2611038424 0;
BA_ "GenMsgDelayTime" BO_ 2611038424 0;
BA_ "GenMsgSendType" BO_ 2611038424 1;
BA_ "TpTxIndex" BO_ 2611038424 463554776;
BA_ "NetworkInitialization" BO_ 2609989848 0;
BA_ "GenMsgDelayTime" BO_ 2609989848 0;
BA_ "GenMsgSendType" BO_ 2609989848 1;
BA_ "TpTxIndex" BO_ 2609989848 462506200;
BA_ "NetworkInitialization" BO_ 2610126930 0;
BA_ "GenMsgDelayTime" BO_ 2610126930 0;
BA_ "GenMsgSendType" BO_ 2610126930 1;
BA_ "TpTxIndex" BO_ 2610126930 462506200;
BA_ "FrameRouting" BO_ 1150 "HS3_CAN,0x45E;";
BA_ "FrameGatewayNetwork" BO_ 1150 "HS3_CAN";
BA_ "FrameGatewayId" BO_ 1150 1118;
BA_ "NetworkInitialization" BO_ 2610126914 0;
BA_ "GenMsgDelayTime" BO_ 2610126914 0;
BA_ "GenMsgSendType" BO_ 2610126914 1;
BA_ "TpTxIndex" BO_ 2610126914 462489816;
BA_ "NetworkInitialization" BO_ 2609973464 0;
BA_ "GenMsgDelayTime" BO_ 2609973464 0;
BA_ "GenMsgSendType" BO_ 2609973464 1;
BA_ "TpTxIndex" BO_ 2609973464 462489816;
BA_ "NetworkInitialization" BO_ 2612224062 0;
BA_ "GenMsgDelayTime" BO_ 2612224062 0;
BA_ "GenMsgSendType" BO_ 2612224062 1;
BA_ "OvtpPushApplication" BO_ 2612224062 1;
BA_ "TpTxIndex" BO_ 2612224062 463534296;
BA_ "NetworkInitialization" BO_ 2611175486 0;
BA_ "GenMsgDelayTime" BO_ 2611175486 0;
BA_ "GenMsgSendType" BO_ 2611175486 1;
BA_ "TpTxIndex" BO_ 2611175486 463534296;
BA_ "NetworkInitialization" BO_ 2611017944 0;
BA_ "GenMsgDelayTime" BO_ 2611017944 0;
BA_ "GenMsgSendType" BO_ 2611017944 1;
BA_ "TpTxIndex" BO_ 2611017944 463534296;
BA_ "NetworkInitialization" BO_ 2612002008 0;
BA_ "GenMsgDelayTime" BO_ 2612002008 0;
BA_ "GenMsgSendType" BO_ 2612002008 1;
BA_ "TpTxIndex" BO_ 2612002008 464518360;
BA_ "NetworkInitialization" BO_ 2610953432 0;
BA_ "GenMsgDelayTime" BO_ 2610953432 0;
BA_ "GenMsgSendType" BO_ 2610953432 1;
BA_ "TpTxIndex" BO_ 2610953432 463469784;
BA_ "NetworkInitialization" BO_ 2611022040 0;
BA_ "GenMsgDelayTime" BO_ 2611022040 0;
BA_ "GenMsgSendType" BO_ 2611022040 1;
BA_ "TpTxIndex" BO_ 2611022040 463538392;
BA_ "NetworkInitialization" BO_ 2612224066 0;
BA_ "GenMsgDelayTime" BO_ 2612224066 0;
BA_ "GenMsgSendType" BO_ 2612224066 1;
BA_ "OvtpPushApplication" BO_ 2612224066 1;
BA_ "TpTxIndex" BO_ 2612224066 464586968;
BA_ "NetworkInitialization" BO_ 2609969368 0;
BA_ "GenMsgDelayTime" BO_ 2609969368 0;
BA_ "GenMsgSendType" BO_ 2609969368 1;
BA_ "TpTxIndex" BO_ 2609969368 462485720;
BA_ "NetworkInitialization" BO_ 2610126910 0;
BA_ "GenMsgDelayTime" BO_ 2610126910 0;
BA_ "GenMsgSendType" BO_ 2610126910 1;
BA_ "TpTxIndex" BO_ 2610126910 462485720;
BA_ "NetworkInitialization" BO_ 2611175490 0;
BA_ "GenMsgDelayTime" BO_ 2611175490 0;
BA_ "GenMsgSendType" BO_ 2611175490 1;
BA_ "TpTxIndex" BO_ 2611175490 463538392;
BA_ "FrameRouting" BO_ 811 "HS3_CAN,0x32B;";
BA_ "FrameGatewayNetwork" BO_ 811 "HS3_CAN";
BA_ "FrameGatewayId" BO_ 811 811;
BA_ "GenMsgCycleTime" BO_ 810 1000;
BA_ "GenMsgSendType" BO_ 810 5;
BA_ "FrameRouting" BO_ 519 "FD1_CAN,0x207;";
BA_ "FrameGatewayNetwork" BO_ 519 "FD1_CAN";
BA_ "FrameGatewayId" BO_ 519 519;
BA_ "GenMsgCycleTime" BO_ 751 1000;
BA_ "GenMsgSendType" BO_ 751 0;
BA_ "GenMsgCycleTime" BO_ 356 100;
BA_ "GenMsgSendType" BO_ 356 0;
BA_ "NetworkInitialization" BO_ 2029 0;
BA_ "GenMsgDelayTime" BO_ 2029 0;
BA_ "GenMsgSendType" BO_ 2029 1;
BA_ "DiagResponse" BO_ 2029 1;
BA_ "GenMsgILSupport" BO_ 2029 0;
BA_ "GenMsgCycleTime" BO_ 303 100;
BA_ "GenMsgSendType" BO_ 303 0;
BA_ "GenMsgDelayTime" BO_ 2612224034 0;
BA_ "GenMsgSendType" BO_ 2612224034 1;
BA_ "OvtpPushApplication" BO_ 2612224034 1;
BA_ "TpTxIndex" BO_ 2612224034 464554200;
BA_ "GenMsgDelayTime" BO_ 2612037848 0;
BA_ "GenMsgSendType" BO_ 2612037848 1;
BA_ "OvtpPushApplication" BO_ 2612037848 1;
BA_ "TpTxIndex" BO_ 2612037848 464554200;
BA_ "GenMsgDelayTime" BO_ 2611175458 0;
BA_ "GenMsgSendType" BO_ 2611175458 1;
BA_ "TpTxIndex" BO_ 2611175458 463505624;
BA_ "GenMsgDelayTime" BO_ 2610989272 0;
BA_ "GenMsgSendType" BO_ 2610989272 1;
BA_ "TpTxIndex" BO_ 2610989272 463505624;
BA_ "GenMsgDelayTime" BO_ 2610126882 0;
BA_ "GenMsgSendType" BO_ 2610126882 1;
BA_ "TpTxIndex" BO_ 2610126882 462457048;
BA_ "GenMsgDelayTime" BO_ 2609940696 0;
BA_ "GenMsgSendType" BO_ 2609940696 1;
BA_ "TpTxIndex" BO_ 2609940696 462457048;
BA_ "U_CD764_MY2022_Tx" SG_ 943 InhbtGlblClkYr_No_Rq 1;
BA_ "U_U55X_MY2022_Tx" SG_ 943 InhbtGlblClkYr_No_Rq 1;
BA_ "U_CD542_MY2021_Tx" SG_ 943 InhbtGlblClkYr_No_Rq 1;
BA_ "ECGUsedTxSignal" SG_ 943 InhbtGlblClkYr_No_Rq 1;
BA_ "U_T6_MCA_MY2020_Tx" SG_ 943 InhbtGlblClkYr_No_Rq 1;
BA_ "U_CD764_MY2022_Rx" SG_ 943 InhbtGlblClkYr_No_Rq 1;
BA_ "U_U55X_MY2022_Rx" SG_ 943 InhbtGlblClkYr_No_Rq 1;
BA_ "U_CD542_MY2021_Rx" SG_ 943 InhbtGlblClkYr_No_Rq 1;
BA_ "U_T6_MCA_MY2020_Rx" SG_ 943 InhbtGlblClkYr_No_Rq 1;
BA_ "U_CD764_MY2022_Tx" SG_ 943 InhbtGlblClkScnd_No_Rq 1;
BA_ "U_U55X_MY2022_Tx" SG_ 943 InhbtGlblClkScnd_No_Rq 1;
BA_ "U_CD542_MY2021_Tx" SG_ 943 InhbtGlblClkScnd_No_Rq 1;
BA_ "ECGUsedTxSignal" SG_ 943 InhbtGlblClkScnd_No_Rq 1;
BA_ "U_T6_MCA_MY2020_Tx" SG_ 943 InhbtGlblClkScnd_No_Rq 1;
BA_ "U_CD764_MY2022_Rx" SG_ 943 InhbtGlblClkScnd_No_Rq 1;
BA_ "U_U55X_MY2022_Rx" SG_ 943 InhbtGlblClkScnd_No_Rq 1;
BA_ "U_CD542_MY2021_Rx" SG_ 943 InhbtGlblClkScnd_No_Rq 1;
BA_ "U_T6_MCA_MY2020_Rx" SG_ 943 InhbtGlblClkScnd_No_Rq 1;
BA_ "U_CD764_MY2022_Tx" SG_ 943 InhbtGlblClkMnte_No_Rq 1;
BA_ "U_U55X_MY2022_Tx" SG_ 943 InhbtGlblClkMnte_No_Rq 1;
BA_ "U_CD542_MY2021_Tx" SG_ 943 InhbtGlblClkMnte_No_Rq 1;
BA_ "ECGUsedTxSignal" SG_ 943 InhbtGlblClkMnte_No_Rq 1;
BA_ "U_T6_MCA_MY2020_Tx" SG_ 943 InhbtGlblClkMnte_No_Rq 1;
BA_ "U_CD764_MY2022_Rx" SG_ 943 InhbtGlblClkMnte_No_Rq 1;
BA_ "U_U55X_MY2022_Rx" SG_ 943 InhbtGlblClkMnte_No_Rq 1;
BA_ "U_CD542_MY2021_Rx" SG_ 943 InhbtGlblClkMnte_No_Rq 1;
BA_ "U_T6_MCA_MY2020_Rx" SG_ 943 InhbtGlblClkMnte_No_Rq 1;
BA_ "U_CD764_MY2022_Tx" SG_ 943 InhbtGlblClkHr_No_Rq 1;
BA_ "U_U55X_MY2022_Tx" SG_ 943 InhbtGlblClkHr_No_Rq 1;
BA_ "U_CD542_MY2021_Tx" SG_ 943 InhbtGlblClkHr_No_Rq 1;
BA_ "ECGUsedTxSignal" SG_ 943 InhbtGlblClkHr_No_Rq 1;
BA_ "U_T6_MCA_MY2020_Tx" SG_ 943 InhbtGlblClkHr_No_Rq 1;
BA_ "U_CD764_MY2022_Rx" SG_ 943 InhbtGlblClkHr_No_Rq 1;
BA_ "U_U55X_MY2022_Rx" SG_ 943 InhbtGlblClkHr_No_Rq 1;
BA_ "U_CD542_MY2021_Rx" SG_ 943 InhbtGlblClkHr_No_Rq 1;
BA_ "U_T6_MCA_MY2020_Rx" SG_ 943 InhbtGlblClkHr_No_Rq 1;
BA_ "U_CD764_MY2022_Tx" SG_ 943 InhbtGlblClkDay_No_Rq 1;
BA_ "U_U55X_MY2022_Tx" SG_ 943 InhbtGlblClkDay_No_Rq 1;
BA_ "U_CD542_MY2021_Tx" SG_ 943 InhbtGlblClkDay_No_Rq 1;
BA_ "ECGUsedTxSignal" SG_ 943 InhbtGlblClkDay_No_Rq 1;
BA_ "U_T6_MCA_MY2020_Tx" SG_ 943 InhbtGlblClkDay_No_Rq 1;
BA_ "U_CD764_MY2022_Rx" SG_ 943 InhbtGlblClkDay_No_Rq 1;
BA_ "U_U55X_MY2022_Rx" SG_ 943 InhbtGlblClkDay_No_Rq 1;
BA_ "U_CD542_MY2021_Rx" SG_ 943 InhbtGlblClkDay_No_Rq 1;
BA_ "U_T6_MCA_MY2020_Rx" SG_ 943 InhbtGlblClkDay_No_Rq 1;
BA_ "U_CD764_MY2022_Tx" SG_ 943 InhbtGlblClkAdj_B_Rq 1;
BA_ "U_U55X_MY2022_Tx" SG_ 943 InhbtGlblClkAdj_B_Rq 1;
BA_ "U_CD542_MY2021_Tx" SG_ 943 InhbtGlblClkAdj_B_Rq 1;
BA_ "ECGUsedTxSignal" SG_ 943 InhbtGlblClkAdj_B_Rq 1;
BA_ "U_T6_MCA_MY2020_Tx" SG_ 943 InhbtGlblClkAdj_B_Rq 1;
BA_ "U_CD764_MY2022_Rx" SG_ 943 InhbtGlblClkAdj_B_Rq 1;
BA_ "U_U55X_MY2022_Rx" SG_ 943 InhbtGlblClkAdj_B_Rq 1;
BA_ "U_CD542_MY2021_Rx" SG_ 943 InhbtGlblClkAdj_B_Rq 1;
BA_ "U_T6_MCA_MY2020_Rx" SG_ 943 InhbtGlblClkAdj_B_Rq 1;
BA_ "GenSigSendType" SG_ 943 InhbtGlblClkAdj_B_Rq 3;
BA_ "U_CD764_MY2022_Tx" SG_ 932 RmtCtlBattMntr_B_Falt 1;
BA_ "U_CD764_MY2022_Tx" SG_ 932 VehInhbtMde_D_Stat 1;
BA_ "U_U55X_MY2022_Tx" SG_ 932 VehInhbtMde_D_Stat 1;
BA_ "U_CD542_MY2021_Tx" SG_ 932 VehInhbtMde_D_Stat 1;
BA_ "U_T6_MCA_MY2020_Tx" SG_ 932 VehInhbtMde_D_Stat 1;
BA_ "U_CD764_MY2022_Rx" SG_ 932 VehInhbtMde_D_Stat 1;
BA_ "U_U55X_MY2022_Rx" SG_ 932 VehInhbtMde_D_Stat 1;
BA_ "U_CD542_MY2021_Rx" SG_ 932 VehInhbtMde_D_Stat 1;
BA_ "ECGUsedRxSignal" SG_ 932 VehInhbtMde_D_Stat 1;
BA_ "U_T6_MCA_MY2020_Rx" SG_ 932 VehInhbtMde_D_Stat 1;
BA_ "U_CD764_MY2022_Tx" SG_ 932 VehStrtInhbt_D_Stat 1;
BA_ "U_U55X_MY2022_Tx" SG_ 932 VehStrtInhbt_D_Stat 1;
BA_ "U_CD542_MY2021_Tx" SG_ 932 VehStrtInhbt_D_Stat 1;
BA_ "U_T6_MCA_MY2020_Tx" SG_ 932 VehStrtInhbt_D_Stat 1;
BA_ "U_CD542_MY2021_Rx" SG_ 932 VehStrtInhbt_D_Stat 1;
BA_ "ECGUsedRxSignal" SG_ 932 VehStrtInhbt_D_Stat 1;
BA_ "U_CD764_MY2022_Rx" SG_ 932 VehStrtInhbt_D_Stat 1;
BA_ "U_U55X_MY2022_Rx" SG_ 932 VehStrtInhbt_D_Stat 1;
BA_ "U_T6_MCA_MY2020_Rx" SG_ 932 VehStrtInhbt_D_Stat 1;
BA_ "U_CD764_MY2022_Tx" SG_ 932 VehOnCtl_D_Stat 1;
BA_ "U_U55X_MY2022_Tx" SG_ 932 VehOnCtl_D_Stat 1;
BA_ "U_CD542_MY2021_Tx" SG_ 932 VehOnCtl_D_Stat 1;
BA_ "U_T6_MCA_MY2020_Tx" SG_ 932 VehOnCtl_D_Stat 1;
BA_ "U_CD542_MY2021_Rx" SG_ 932 VehOnCtl_D_Stat 1;
BA_ "ECGUsedRxSignal" SG_ 932 VehOnCtl_D_Stat 1;
BA_ "U_CD764_MY2022_Rx" SG_ 932 VehOnCtl_D_Stat 1;
BA_ "U_U55X_MY2022_Rx" SG_ 932 VehOnCtl_D_Stat 1;
BA_ "U_T6_MCA_MY2020_Rx" SG_ 932 VehOnCtl_D_Stat 1;
BA_ "U_CD764_MY2022_Tx" SG_ 932 VehOnSrc2_D_Stat 1;
BA_ "U_U55X_MY2022_Tx" SG_ 932 VehOnSrc2_D_Stat 1;
BA_ "U_CD542_MY2021_Tx" SG_ 932 VehOnSrc2_D_Stat 1;
BA_ "U_T6_MCA_MY2020_Tx" SG_ 932 VehOnSrc2_D_Stat 1;
BA_ "U_CD542_MY2021_Rx" SG_ 932 VehOnSrc2_D_Stat 1;
BA_ "ECGUsedRxSignal" SG_ 932 VehOnSrc2_D_Stat 1;
BA_ "U_CD764_MY2022_Rx" SG_ 932 VehOnSrc2_D_Stat 1;
BA_ "U_U55X_MY2022_Rx" SG_ 932 VehOnSrc2_D_Stat 1;
BA_ "U_T6_MCA_MY2020_Rx" SG_ 932 VehOnSrc2_D_Stat 1;
BA_ "U_CD764_MY2022_Tx" SG_ 932 CanMsg3A4_No_Crc 1;
BA_ "U_U55X_MY2022_Tx" SG_ 932 CanMsg3A4_No_Crc 1;
BA_ "U_CD542_MY2021_Tx" SG_ 932 CanMsg3A4_No_Crc 1;
BA_ "U_T6_MCA_MY2020_Tx" SG_ 932 CanMsg3A4_No_Crc 1;
BA_ "U_CD764_MY2022_Rx" SG_ 932 CanMsg3A4_No_Crc 1;
BA_ "U_U55X_MY2022_Rx" SG_ 932 CanMsg3A4_No_Crc 1;
BA_ "U_CD542_MY2021_Rx" SG_ 932 CanMsg3A4_No_Crc 1;
BA_ "ECGUsedRxSignal" SG_ 932 CanMsg3A4_No_Crc 1;
BA_ "U_T6_MCA_MY2020_Rx" SG_ 932 CanMsg3A4_No_Crc 1;
BA_ "MetaData" SG_ 932 CanMsg3A4_No_Crc 1;
BA_ "ContentDependant" SG_ 932 CanMsg3A4_No_Crc 1;
BA_ "U_CD764_MY2022_Tx" SG_ 932 CanMsg3A4_No_Cnt 1;
BA_ "U_U55X_MY2022_Tx" SG_ 932 CanMsg3A4_No_Cnt 1;
BA_ "U_CD542_MY2021_Tx" SG_ 932 CanMsg3A4_No_Cnt 1;
BA_ "U_T6_MCA_MY2020_Tx" SG_ 932 CanMsg3A4_No_Cnt 1;
BA_ "U_CD764_MY2022_Rx" SG_ 932 CanMsg3A4_No_Cnt 1;
BA_ "U_U55X_MY2022_Rx" SG_ 932 CanMsg3A4_No_Cnt 1;
BA_ "U_CD542_MY2021_Rx" SG_ 932 CanMsg3A4_No_Cnt 1;
BA_ "ECGUsedRxSignal" SG_ 932 CanMsg3A4_No_Cnt 1;
BA_ "U_T6_MCA_MY2020_Rx" SG_ 932 CanMsg3A4_No_Cnt 1;
BA_ "MetaData" SG_ 932 CanMsg3A4_No_Cnt 1;
BA_ "ContentDependant" SG_ 932 CanMsg3A4_No_Cnt 1;
BA_ "U_CD764_MY2022_Tx" SG_ 885 BattULoChrg_D_RqOta 1;
BA_ "U_U55X_MY2022_Tx" SG_ 885 BattULoChrg_D_RqOta 1;
BA_ "U_CD542_MY2021_Tx" SG_ 885 BattULoChrg_D_RqOta 1;
BA_ "ECGUsedTxSignal" SG_ 885 BattULoChrg_D_RqOta 1;
BA_ "U_T6_MCA_MY2020_Tx" SG_ 885 BattULoChrg_D_RqOta 1;
BA_ "U_CD764_MY2022_Rx" SG_ 885 BattULoChrg_D_RqOta 1;
BA_ "U_CD542_MY2021_Rx" SG_ 885 BattULoChrg_D_RqOta 1;
BA_ "U_T6_MCA_MY2020_Rx" SG_ 885 BattULoChrg_D_RqOta 1;
BA_ "U_CD764_MY2022_Tx" SG_ 885 VehStrtInhbt_T_Dsply 1;
BA_ "U_U55X_MY2022_Tx" SG_ 885 VehStrtInhbt_T_Dsply 1;
BA_ "U_CD542_MY2021_Tx" SG_ 885 VehStrtInhbt_T_Dsply 1;
BA_ "ECGUsedTxSignal" SG_ 885 VehStrtInhbt_T_Dsply 1;
BA_ "U_T6_MCA_MY2020_Tx" SG_ 885 VehStrtInhbt_T_Dsply 1;
BA_ "U_CD764_MY2022_Tx" SG_ 885 VehStrtInhbt_D_Dsply 1;
BA_ "U_U55X_MY2022_Tx" SG_ 885 VehStrtInhbt_D_Dsply 1;
BA_ "U_CD542_MY2021_Tx" SG_ 885 VehStrtInhbt_D_Dsply 1;
BA_ "ECGUsedTxSignal" SG_ 885 VehStrtInhbt_D_Dsply 1;
BA_ "U_T6_MCA_MY2020_Tx" SG_ 885 VehStrtInhbt_D_Dsply 1;
BA_ "U_CD764_MY2022_Tx" SG_ 885 VehOnRqstr_D_Stat 1;
BA_ "U_U55X_MY2022_Tx" SG_ 885 VehOnRqstr_D_Stat 1;
BA_ "U_CD542_MY2021_Tx" SG_ 885 VehOnRqstr_D_Stat 1;
BA_ "ECGUsedTxSignal" SG_ 885 VehOnRqstr_D_Stat 1;
BA_ "U_T6_MCA_MY2020_Tx" SG_ 885 VehOnRqstr_D_Stat 1;
BA_ "U_CD764_MY2022_Rx" SG_ 885 VehOnRqstr_D_Stat 1;
BA_ "U_U55X_MY2022_Rx" SG_ 885 VehOnRqstr_D_Stat 1;
BA_ "U_CD542_MY2021_Rx" SG_ 885 VehOnRqstr_D_Stat 1;
BA_ "U_T6_MCA_MY2020_Rx" SG_ 885 VehOnRqstr_D_Stat 1;
BA_ "U_CD764_MY2022_Tx" SG_ 885 VehStrtInhbt_D_RqCld 1;
BA_ "U_U55X_MY2022_Tx" SG_ 885 VehStrtInhbt_D_RqCld 1;
BA_ "U_CD542_MY2021_Tx" SG_ 885 VehStrtInhbt_D_RqCld 1;
BA_ "ECGUsedTxSignal" SG_ 885 VehStrtInhbt_D_RqCld 1;
BA_ "U_T6_MCA_MY2020_Tx" SG_ 885 VehStrtInhbt_D_RqCld 1;
BA_ "U_CD764_MY2022_Rx" SG_ 885 VehStrtInhbt_D_RqCld 1;
BA_ "U_CD542_MY2021_Rx" SG_ 885 VehStrtInhbt_D_RqCld 1;
BA_ "U_T6_MCA_MY2020_Rx" SG_ 885 VehStrtInhbt_D_RqCld 1;
BA_ "U_CD764_MY2022_Tx" SG_ 885 VehOn_D_RqCld 1;
BA_ "U_U55X_MY2022_Tx" SG_ 885 VehOn_D_RqCld 1;
BA_ "U_CD542_MY2021_Tx" SG_ 885 VehOn_D_RqCld 1;
BA_ "ECGUsedTxSignal" SG_ 885 VehOn_D_RqCld 1;
BA_ "U_T6_MCA_MY2020_Tx" SG_ 885 VehOn_D_RqCld 1;
BA_ "U_CD764_MY2022_Rx" SG_ 885 VehOn_D_RqCld 1;
BA_ "U_U55X_MY2022_Rx" SG_ 885 VehOn_D_RqCld 1;
BA_ "U_CD542_MY2021_Rx" SG_ 885 VehOn_D_RqCld 1;
BA_ "U_T6_MCA_MY2020_Rx" SG_ 885 VehOn_D_RqCld 1;
BA_ "U_CD764_MY2022_Tx" SG_ 885 CanMsg375_No_Cnt 1;
BA_ "U_U55X_MY2022_Tx" SG_ 885 CanMsg375_No_Cnt 1;
BA_ "U_CD542_MY2021_Tx" SG_ 885 CanMsg375_No_Cnt 1;
BA_ "ECGUsedTxSignal" SG_ 885 CanMsg375_No_Cnt 1;
BA_ "U_T6_MCA_MY2020_Tx" SG_ 885 CanMsg375_No_Cnt 1;
BA_ "U_CD764_MY2022_Rx" SG_ 885 CanMsg375_No_Cnt 1;
BA_ "U_U55X_MY2022_Rx" SG_ 885 CanMsg375_No_Cnt 1;
BA_ "U_CD542_MY2021_Rx" SG_ 885 CanMsg375_No_Cnt 1;
BA_ "U_T6_MCA_MY2020_Rx" SG_ 885 CanMsg375_No_Cnt 1;
BA_ "MetaData" SG_ 885 CanMsg375_No_Cnt 1;
BA_ "U_CD764_MY2022_Tx" SG_ 885 CanMsg375_No_Crc 1;
BA_ "U_U55X_MY2022_Tx" SG_ 885 CanMsg375_No_Crc 1;
BA_ "U_CD542_MY2021_Tx" SG_ 885 CanMsg375_No_Crc 1;
BA_ "ECGUsedTxSignal" SG_ 885 CanMsg375_No_Crc 1;
BA_ "U_T6_MCA_MY2020_Tx" SG_ 885 CanMsg375_No_Crc 1;
BA_ "U_CD764_MY2022_Rx" SG_ 885 CanMsg375_No_Crc 1;
BA_ "U_U55X_MY2022_Rx" SG_ 885 CanMsg375_No_Crc 1;
BA_ "U_CD542_MY2021_Rx" SG_ 885 CanMsg375_No_Crc 1;
BA_ "U_T6_MCA_MY2020_Rx" SG_ 885 CanMsg375_No_Crc 1;
BA_ "MetaData" SG_ 885 CanMsg375_No_Crc 1;
BA_ "U_CD764_MY2022_Tx" SG_ 885 OtaActv_D_Stat 1;
BA_ "U_U55X_MY2022_Tx" SG_ 885 OtaActv_D_Stat 1;
BA_ "U_CD542_MY2021_Tx" SG_ 885 OtaActv_D_Stat 1;
BA_ "ECGUsedTxSignal" SG_ 885 OtaActv_D_Stat 1;
BA_ "U_T6_MCA_MY2020_Tx" SG_ 885 OtaActv_D_Stat 1;
BA_ "U_CD764_MY2022_Rx" SG_ 885 OtaActv_D_Stat 1;
BA_ "U_U55X_MY2022_Rx" SG_ 885 OtaActv_D_Stat 1;
BA_ "U_CD542_MY2021_Rx" SG_ 885 OtaActv_D_Stat 1;
BA_ "U_T6_MCA_MY2020_Rx" SG_ 885 OtaActv_D_Stat 1;
BA_ "ECGUsedRxSignal" SG_ 159 OBCC_ECG_Word_Tx 1;
BA_ "ECGUsedTxSignal" SG_ 151 ECG_OBCC_Word_Tx 1;
BA_ "U_CD764_MY2022_Tx" SG_ 1160 ReFuelSwtchStat_D_Actl2 1;
BA_ "ECGUsedTxSignal" SG_ 1160 ReFuelSwtchStat_D_Actl2 1;
BA_ "GenSigSendType" SG_ 1160 ReFuelSwtchStat_D_Actl2 3;
BA_ "WakeupSignal" SG_ 1160 ReFuelSwtchStat_D_Actl2 1;
BA_ "U_CD764_MY2022_Tx" SG_ 1160 DgtlCommPncReset_B_Req 1;
BA_ "U_U55X_MY2022_Tx" SG_ 1160 DgtlCommPncReset_B_Req 1;
BA_ "U_CD542_MY2021_Tx" SG_ 1160 DgtlCommPncReset_B_Req 1;
BA_ "ECGUsedTxSignal" SG_ 1160 DgtlCommPncReset_B_Req 1;
BA_ "GenSigSendType" SG_ 1160 DgtlCommPncReset_B_Req 3;
BA_ "U_CD764_MY2022_Tx" SG_ 1160 DgtlCommPnc_D_Rq 1;
BA_ "U_U55X_MY2022_Tx" SG_ 1160 DgtlCommPnc_D_Rq 1;
BA_ "U_CD542_MY2021_Tx" SG_ 1160 DgtlCommPnc_D_Rq 1;
BA_ "ECGUsedTxSignal" SG_ 1160 DgtlCommPnc_D_Rq 1;
BA_ "GenSigSendType" SG_ 1160 DgtlCommPnc_D_Rq 3;
BA_ "U_CD764_MY2022_Tx" SG_ 1160 PwSustnRdata_B_RqTelem 1;
BA_ "U_U55X_MY2022_Tx" SG_ 1160 PwSustnRdata_B_RqTelem 1;
BA_ "U_CD542_MY2021_Tx" SG_ 1160 PwSustnRdata_B_RqTelem 1;
BA_ "ECGUsedTxSignal" SG_ 1160 PwSustnRdata_B_RqTelem 1;
BA_ "U_CD542_MY2021_Rx" SG_ 1160 PwSustnRdata_B_RqTelem 1;
BA_ "GenSigSendType" SG_ 1160 PwSustnRdata_B_RqTelem 3;
BA_ "U_CD764_MY2022_Tx" SG_ 1160 DataMntrSustn_B_Rq 1;
BA_ "U_U55X_MY2022_Tx" SG_ 1160 DataMntrSustn_B_Rq 1;
BA_ "U_CD542_MY2021_Tx" SG_ 1160 DataMntrSustn_B_Rq 1;
BA_ "ECGUsedTxSignal" SG_ 1160 DataMntrSustn_B_Rq 1;
BA_ "U_CD542_MY2021_Rx" SG_ 1160 DataMntrSustn_B_Rq 1;
BA_ "GenSigSendType" SG_ 1160 DataMntrSustn_B_Rq 3;
BA_ "U_CD764_MY2022_Tx" SG_ 2612087000 PARSEDPushFcGWM_ECGtoBCM 1;
BA_ "U_CD542_MY2021_Tx" SG_ 2612087000 PARSEDPushFcGWM_ECGtoBCM 1;
BA_ "ECGUsedTxSignal" SG_ 2612087000 PARSEDPushFcGWM_ECGtoBCM 1;
BA_ "U_T6_MCA_MY2020_Tx" SG_ 2612087000 PARSEDPushFcGWM_ECGtoBCM 1;
BA_ "U_CD764_MY2022_Rx" SG_ 2612087000 PARSEDPushFcGWM_ECGtoBCM 1;
BA_ "U_CD542_MY2021_Rx" SG_ 2612087000 PARSEDPushFcGWM_ECGtoBCM 1;
BA_ "U_T6_MCA_MY2020_Rx" SG_ 2612087000 PARSEDPushFcGWM_ECGtoBCM 1;
BA_ "U_U55X_MY2022_Rx" SG_ 895 TurnLght_D_RqRmtCtl 1;
BA_ "U_U55X_MY2022_Rx" SG_ 895 RmtCtlRngSet_D_Rq 1;
BA_ "U_U55X_MY2022_Rx" SG_ 895 RmtCtlRes_D_Stat 1;
BA_ "U_U55X_MY2022_Rx" SG_ 895 RmtCtlKeyPoll_D_Rq 1;
BA_ "U_U55X_MY2022_Rx" SG_ 895 RmtCtlDStat_No_Cs 1;
BA_ "MetaData" SG_ 895 RmtCtlDStat_No_Cs 1;
BA_ "U_U55X_MY2022_Rx" SG_ 895 RmtCtlDStat_No_Cnt 1;
BA_ "MetaData" SG_ 895 RmtCtlDStat_No_Cnt 1;
BA_ "U_U55X_MY2022_Rx" SG_ 895 RmtCtlCntnsIn_B_Stat 1;
BA_ "U_U55X_MY2022_Rx" SG_ 895 RmtCtl_D_Stat 1;
BA_ "WakeupSignal" SG_ 895 RmtCtl_D_Stat 1;
BA_ "ECGUsedRxSignal" SG_ 1134 UpftrDgtlIn12_D_Stat 1;
BA_ "GenSigSendType" SG_ 1134 UpftrDgtlIn12_D_Stat 3;
BA_ "ECGUsedRxSignal" SG_ 1134 UpftrDgtlIn11_D_Stat 1;
BA_ "GenSigSendType" SG_ 1134 UpftrDgtlIn11_D_Stat 3;
BA_ "ECGUsedRxSignal" SG_ 1134 UpftrDgtlIn10_D_Stat 1;
BA_ "GenSigSendType" SG_ 1134 UpftrDgtlIn10_D_Stat 3;
BA_ "U_U55X_MY2022_Tx" SG_ 894 RmtCtlTrgtBody_D_Stat 1;
BA_ "U_U55X_MY2022_Tx" SG_ 894 RmtCtlTrgt_D_Rq 1;
BA_ "GenSigSendType" SG_ 894 RmtCtlTrgt_D_Rq 3;
BA_ "U_U55X_MY2022_Tx" SG_ 894 RmtCtlRngSet_D_Stat 1;
BA_ "GenSigSendType" SG_ 894 RmtCtlRngSet_D_Stat 3;
BA_ "U_U55X_MY2022_Tx" SG_ 894 RmtCtlKeySrch_D_Stat 1;
BA_ "GenSigSendType" SG_ 894 RmtCtlKeySrch_D_Stat 3;
BA_ "U_U55X_MY2022_Tx" SG_ 894 RmtCtlBody_D_Stat 1;
BA_ "GenSigSendType" SG_ 894 RmtCtlBody_D_Stat 3;
BA_ "U_U55X_MY2022_Tx" SG_ 894 RmtCtl_D_RqBody 1;
BA_ "GenSigSendType" SG_ 894 RmtCtl_D_RqBody 3;
BA_ "U_CD764_MY2022_Rx" SG_ 515 PtIgnSwtch_D_Stat 1;
BA_ "U_CD542_MY2021_Rx" SG_ 515 PtIgnSwtch_D_Stat 1;
BA_ "GenSigStartValue" SG_ 515 PtIgnSwtch_D_Stat 2;
BA_ "GenSigStartValueInteger" SG_ 515 PtIgnSwtch_D_Stat 2;
BA_ "GenSigStartValue" SG_ 1119 PwrSrcULo_Te_Actl 1022;
BA_ "GenSigSendType" SG_ 1119 PtLatchActv_B_RqDcdc 3;
BA_ "U_CD542_MY2021_Tx" SG_ 1119 CoolFanDcdc_D_Rq 1;
BA_ "U_P702_MY2021_Tx" SG_ 1119 CoolFanDcdc_D_Rq 1;
BA_ "U_CX727_MY2021_Tx" SG_ 1119 CoolFanDcdc_D_Rq 1;
BA_ "U_CD542_MY2021_Rx" SG_ 1119 CoolFanDcdc_D_Rq 1;
BA_ "U_P702_MY2021_Rx" SG_ 1119 CoolFanDcdc_D_Rq 1;
BA_ "U_CX727_MY2021_Rx" SG_ 1119 CoolFanDcdc_D_Rq 1;
BA_ "GenSigSendType" SG_ 1119 CoolFanDcdc_D_Rq 3;
BA_ "U_CD542_MY2021_Tx" SG_ 1119 DcdcClntFlw_D_Rq 1;
BA_ "U_P702_MY2021_Tx" SG_ 1119 DcdcClntFlw_D_Rq 1;
BA_ "U_CX727_MY2021_Tx" SG_ 1119 DcdcClntFlw_D_Rq 1;
BA_ "U_CD542_MY2021_Rx" SG_ 1119 DcdcClntFlw_D_Rq 1;
BA_ "U_P702_MY2021_Rx" SG_ 1119 DcdcClntFlw_D_Rq 1;
BA_ "U_CX727_MY2021_Rx" SG_ 1119 DcdcClntFlw_D_Rq 1;
BA_ "GenSigSendType" SG_ 1119 DcdcClntFlw_D_Rq 3;
BA_ "U_CX727_MY2021_Rx" SG_ 1827 TesterPhysicalReqBECMB_EPM 1;
BA_ "GenSigSendType" SG_ 1827 TesterPhysicalReqBECMB_EPM 3;
BA_ "U_CX727_MY2021_Tx" SG_ 1835 TesterPhysicalResBECMB_EPM 1;
BA_ "GenSigSendType" SG_ 1835 TesterPhysicalResBECMB_EPM 3;
BA_ "U_CD764_MY2022_Tx" SG_ 1110 RstrnMdulePw_D_Falt 1;
BA_ "U_U55X_MY2022_Tx" SG_ 1110 RstrnMdulePw_D_Falt 1;
BA_ "U_T6_MCA_MY2020_Tx" SG_ 1110 RstrnMdulePw_D_Falt 1;
BA_ "U_P702_MY2021_Tx" SG_ 1110 RstrnMdulePw_D_Falt 1;
BA_ "U_CX727_MY2021_Tx" SG_ 1110 RstrnMdulePw_D_Falt 1;
BA_ "GenSigStartValue" SG_ 1110 RstrnMdulePw_D_Falt 1;
BA_ "GenSigStartValueInteger" SG_ 1110 RstrnMdulePw_D_Falt 1;
BA_ "U_CD542_MY2021_Tx" SG_ 1036 PdstrnAlrt_B_Falt 1;
BA_ "U_P702_MY2021_Tx" SG_ 1036 PdstrnAlrt_B_Falt 1;
BA_ "U_CX727_MY2021_Tx" SG_ 1036 PdstrnAlrt_B_Falt 1;
BA_ "GenSigSendType" SG_ 1036 PdstrnAlrt_B_Falt 3;
BA_ "GenSigStartValue" SG_ 1152 StopStrtVThres_D_Stat 1;
BA_ "GenSigStartValueInteger" SG_ 1152 StopStrtVThres_D_Stat 1;
BA_ "GenSigStartValue" SG_ 1152 VehElEff_No_Avg 126;
BA_ "GenSigStartValueInteger" SG_ 1152 VehElEff_No_Avg 126;
BA_ "U_CD542_MY2021_Rx" SG_ 1152 DcdcOn_B_Rq 1;
BA_ "U_P702_MY2021_Rx" SG_ 1152 DcdcOn_B_Rq 1;
BA_ "U_CX727_MY2021_Rx" SG_ 1152 DcdcOn_B_Rq 1;
BA_ "U_CD542_MY2021_Rx" SG_ 1152 BattTracDiagClr_B_Stat 1;
BA_ "U_P702_MY2021_Rx" SG_ 1152 BattTracDiagClr_B_Stat 1;
BA_ "U_CD764_MY2022_Rx" SG_ 1152 ULoBattSpprtSustn_B_Rq 1;
BA_ "U_U55X_MY2022_Rx" SG_ 1152 ULoBattSpprtSustn_B_Rq 1;
BA_ "U_T6_MCA_MY2020_Rx" SG_ 1152 ULoBattSpprtSustn_B_Rq 1;
BA_ "U_P702_MY2021_Rx" SG_ 1152 ULoBattSpprtSustn_B_Rq 1;
BA_ "U_CD542_MY2021_Rx" SG_ 1152 ULoBattSpprtSustn_B_Rq 1;
BA_ "U_CX727_MY2021_Rx" SG_ 1152 ULoBattSpprtSustn_B_Rq 1;
BA_ "U_U55X_MY2022_Tx" SG_ 518 LsdCluPlate_Te_Est 1;
BA_ "GenSigStartValue" SG_ 518 LsdCluPlate_Te_Est 65;
BA_ "U_U55X_MY2022_Tx" SG_ 518 RearDiffLck_Tq_Actl2 1;
BA_ "GenSigStartValue" SG_ 518 RearDiffLck_Tq_Actl2 16382;
BA_ "GenSigStartValueInteger" SG_ 518 RearDiffLck_Tq_Actl2 16382;
BA_ "U_CX727_MY2021_Tx" SG_ 1458 BECMB_GWOnBoardTester 1;
BA_ "U_CD764_MY2022_Rx" SG_ 1458 BECMB_GWOnBoardTester 1;
BA_ "U_U55X_MY2022_Rx" SG_ 1458 BECMB_GWOnBoardTester 1;
BA_ "U_CD542_MY2021_Rx" SG_ 1458 BECMB_GWOnBoardTester 1;
BA_ "U_T6_MCA_MY2020_Rx" SG_ 1458 BECMB_GWOnBoardTester 1;
BA_ "U_P702_MY2021_Rx" SG_ 1458 BECMB_GWOnBoardTester 1;
BA_ "U_CX727_MY2021_Rx" SG_ 1458 BECMB_GWOnBoardTester 1;
BA_ "GenSigStartValue" SG_ 1458 BECMB_GWOnBoardTester 255;
BA_ "ContentDependant" SG_ 1458 BECMB_GWOnBoardTester 1;
BA_ "GenSigStartValueInteger" SG_ 1458 BECMB_GWOnBoardTester 255;
BA_ "U_CX727_MY2021_Tx" SG_ 1458 BECMB_GWNMProxy 1;
BA_ "U_CD764_MY2022_Rx" SG_ 1458 BECMB_GWNMProxy 1;
BA_ "U_U55X_MY2022_Rx" SG_ 1458 BECMB_GWNMProxy 1;
BA_ "U_CD542_MY2021_Rx" SG_ 1458 BECMB_GWNMProxy 1;
BA_ "U_T6_MCA_MY2020_Rx" SG_ 1458 BECMB_GWNMProxy 1;
BA_ "U_P702_MY2021_Rx" SG_ 1458 BECMB_GWNMProxy 1;
BA_ "U_CX727_MY2021_Rx" SG_ 1458 BECMB_GWNMProxy 1;
BA_ "GenSigStartValue" SG_ 1458 BECMB_GWNMProxy 255;
BA_ "ContentDependant" SG_ 1458 BECMB_GWNMProxy 1;
BA_ "GenSigStartValueInteger" SG_ 1458 BECMB_GWNMProxy 255;
BA_ "U_CX727_MY2021_Tx" SG_ 1458 BECMB_AutoSarNMNodeId 1;
BA_ "U_CD764_MY2022_Rx" SG_ 1458 BECMB_AutoSarNMNodeId 1;
BA_ "U_U55X_MY2022_Rx" SG_ 1458 BECMB_AutoSarNMNodeId 1;
BA_ "U_CD542_MY2021_Rx" SG_ 1458 BECMB_AutoSarNMNodeId 1;
BA_ "U_T6_MCA_MY2020_Rx" SG_ 1458 BECMB_AutoSarNMNodeId 1;
BA_ "U_P702_MY2021_Rx" SG_ 1458 BECMB_AutoSarNMNodeId 1;
BA_ "U_CX727_MY2021_Rx" SG_ 1458 BECMB_AutoSarNMNodeId 1;
BA_ "GenSigStartValue" SG_ 1458 BECMB_AutoSarNMNodeId 178;
BA_ "ContentDependant" SG_ 1458 BECMB_AutoSarNMNodeId 1;
BA_ "GenSigStartValueInteger" SG_ 1458 BECMB_AutoSarNMNodeId 178;
BA_ "U_CX727_MY2021_Tx" SG_ 1458 BECMB_AutoSarNMControl 1;
BA_ "U_CD764_MY2022_Rx" SG_ 1458 BECMB_AutoSarNMControl 1;
BA_ "U_U55X_MY2022_Rx" SG_ 1458 BECMB_AutoSarNMControl 1;
BA_ "U_CD542_MY2021_Rx" SG_ 1458 BECMB_AutoSarNMControl 1;
BA_ "U_T6_MCA_MY2020_Rx" SG_ 1458 BECMB_AutoSarNMControl 1;
BA_ "U_P702_MY2021_Rx" SG_ 1458 BECMB_AutoSarNMControl 1;
BA_ "U_CX727_MY2021_Rx" SG_ 1458 BECMB_AutoSarNMControl 1;
BA_ "ContentDependant" SG_ 1458 BECMB_AutoSarNMControl 1;
BA_ "U_CX727_MY2021_Tx" SG_ 1458 BECMB_AutoSarNMReserved4 1;
BA_ "U_CD764_MY2022_Rx" SG_ 1458 BECMB_AutoSarNMReserved4 1;
BA_ "U_U55X_MY2022_Rx" SG_ 1458 BECMB_AutoSarNMReserved4 1;
BA_ "U_CD542_MY2021_Rx" SG_ 1458 BECMB_AutoSarNMReserved4 1;
BA_ "U_T6_MCA_MY2020_Rx" SG_ 1458 BECMB_AutoSarNMReserved4 1;
BA_ "U_P702_MY2021_Rx" SG_ 1458 BECMB_AutoSarNMReserved4 1;
BA_ "U_CX727_MY2021_Rx" SG_ 1458 BECMB_AutoSarNMReserved4 1;
BA_ "GenSigStartValue" SG_ 1458 BECMB_AutoSarNMReserved4 255;
BA_ "ContentDependant" SG_ 1458 BECMB_AutoSarNMReserved4 1;
BA_ "GenSigStartValueInteger" SG_ 1458 BECMB_AutoSarNMReserved4 255;
BA_ "U_CX727_MY2021_Tx" SG_ 1458 BECMB_AutoSarNMReserved3 1;
BA_ "U_CD764_MY2022_Rx" SG_ 1458 BECMB_AutoSarNMReserved3 1;
BA_ "U_U55X_MY2022_Rx" SG_ 1458 BECMB_AutoSarNMReserved3 1;
BA_ "U_CD542_MY2021_Rx" SG_ 1458 BECMB_AutoSarNMReserved3 1;
BA_ "U_T6_MCA_MY2020_Rx" SG_ 1458 BECMB_AutoSarNMReserved3 1;
BA_ "U_P702_MY2021_Rx" SG_ 1458 BECMB_AutoSarNMReserved3 1;
BA_ "U_CX727_MY2021_Rx" SG_ 1458 BECMB_AutoSarNMReserved3 1;
BA_ "GenSigStartValue" SG_ 1458 BECMB_AutoSarNMReserved3 255;
BA_ "ContentDependant" SG_ 1458 BECMB_AutoSarNMReserved3 1;
BA_ "GenSigStartValueInteger" SG_ 1458 BECMB_AutoSarNMReserved3 255;
BA_ "U_CX727_MY2021_Tx" SG_ 1458 BECMB_AutoSarNMReserved2 1;
BA_ "U_CD764_MY2022_Rx" SG_ 1458 BECMB_AutoSarNMReserved2 1;
BA_ "U_U55X_MY2022_Rx" SG_ 1458 BECMB_AutoSarNMReserved2 1;
BA_ "U_CD542_MY2021_Rx" SG_ 1458 BECMB_AutoSarNMReserved2 1;
BA_ "U_T6_MCA_MY2020_Rx" SG_ 1458 BECMB_AutoSarNMReserved2 1;
BA_ "U_P702_MY2021_Rx" SG_ 1458 BECMB_AutoSarNMReserved2 1;
BA_ "U_CX727_MY2021_Rx" SG_ 1458 BECMB_AutoSarNMReserved2 1;
BA_ "GenSigStartValue" SG_ 1458 BECMB_AutoSarNMReserved2 255;
BA_ "ContentDependant" SG_ 1458 BECMB_AutoSarNMReserved2 1;
BA_ "GenSigStartValueInteger" SG_ 1458 BECMB_AutoSarNMReserved2 255;
BA_ "U_CX727_MY2021_Tx" SG_ 1458 BECMB_AutoSarNMReserved1 1;
BA_ "U_CD764_MY2022_Rx" SG_ 1458 BECMB_AutoSarNMReserved1 1;
BA_ "U_U55X_MY2022_Rx" SG_ 1458 BECMB_AutoSarNMReserved1 1;
BA_ "U_CD542_MY2021_Rx" SG_ 1458 BECMB_AutoSarNMReserved1 1;
BA_ "U_T6_MCA_MY2020_Rx" SG_ 1458 BECMB_AutoSarNMReserved1 1;
BA_ "U_P702_MY2021_Rx" SG_ 1458 BECMB_AutoSarNMReserved1 1;
BA_ "U_CX727_MY2021_Rx" SG_ 1458 BECMB_AutoSarNMReserved1 1;
BA_ "GenSigStartValue" SG_ 1458 BECMB_AutoSarNMReserved1 255;
BA_ "ContentDependant" SG_ 1458 BECMB_AutoSarNMReserved1 1;
BA_ "GenSigStartValueInteger" SG_ 1458 BECMB_AutoSarNMReserved1 255;
BA_ "U_CX727_MY2021_Tx" SG_ 1092 BattChrgOvrCurnt_B_Falt 1;
BA_ "U_CD542_MY2021_Tx" SG_ 1092 BattTracCell_U_Mx 1;
BA_ "U_CX727_MY2021_Tx" SG_ 1092 BattTracCell_U_Mx 1;
BA_ "U_U55X_MY2022_Rx" SG_ 1092 BattTracCell_U_Mx 1;
BA_ "U_CD542_MY2021_Rx" SG_ 1092 BattTracCell_U_Mx 1;
BA_ "ECGUsedRxSignal" SG_ 1092 BattTracCell_U_Mx 1;
BA_ "U_CD542_MY2021_Tx" SG_ 1092 BattTracMnCell_Te_Actl 1;
BA_ "U_CX727_MY2021_Tx" SG_ 1092 BattTracMnCell_Te_Actl 1;
BA_ "U_U55X_MY2022_Rx" SG_ 1092 BattTracMnCell_Te_Actl 1;
BA_ "U_CD542_MY2021_Rx" SG_ 1092 BattTracMnCell_Te_Actl 1;
BA_ "ECGUsedRxSignal" SG_ 1092 BattTracMnCell_Te_Actl 1;
BA_ "GenSigStartValue" SG_ 1092 BattTracMnCell_Te_Actl 254;
BA_ "GenSigStartValueInteger" SG_ 1092 BattTracMnCell_Te_Actl 254;
BA_ "U_CD542_MY2021_Tx" SG_ 1092 BattTracInsAlrm_B_Stat 1;
BA_ "U_CX727_MY2021_Tx" SG_ 1092 BattTracInsAlrm_B_Stat 1;
BA_ "U_U55X_MY2022_Rx" SG_ 1092 BattTracInsAlrm_B_Stat 1;
BA_ "U_CD542_MY2021_Rx" SG_ 1092 BattTracInsAlrm_B_Stat 1;
BA_ "ECGUsedRxSignal" SG_ 1092 BattTracInsAlrm_B_Stat 1;
BA_ "U_CD542_MY2021_Tx" SG_ 1092 BattTracUMx_B_Stat 1;
BA_ "U_CX727_MY2021_Tx" SG_ 1092 BattTracUMx_B_Stat 1;
BA_ "U_U55X_MY2022_Rx" SG_ 1092 BattTracUMx_B_Stat 1;
BA_ "U_CD542_MY2021_Rx" SG_ 1092 BattTracUMx_B_Stat 1;
BA_ "ECGUsedRxSignal" SG_ 1092 BattTracUMx_B_Stat 1;
BA_ "U_U55X_MY2022_Rx" SG_ 1092 BattTracTeMx_B_Stat 1;
BA_ "U_CD542_MY2021_Rx" SG_ 1092 BattTracTeMx_B_Stat 1;
BA_ "ECGUsedRxSignal" SG_ 1092 BattTracTeMx_B_Stat 1;
BA_ "U_CD542_MY2021_Tx" SG_ 1092 BattTracMxCell_Te_Actl 1;
BA_ "U_CX727_MY2021_Tx" SG_ 1092 BattTracMxCell_Te_Actl 1;
BA_ "U_U55X_MY2022_Rx" SG_ 1092 BattTracMxCell_Te_Actl 1;
BA_ "U_CD542_MY2021_Rx" SG_ 1092 BattTracMxCell_Te_Actl 1;
BA_ "ECGUsedRxSignal" SG_ 1092 BattTracMxCell_Te_Actl 1;
BA_ "GenSigStartValue" SG_ 1092 BattTracMxCell_Te_Actl 254;
BA_ "GenSigStartValueInteger" SG_ 1092 BattTracMxCell_Te_Actl 254;
BA_ "U_CD542_MY2021_Tx" SG_ 1092 BattTracEq_B_Actl 1;
BA_ "U_CX727_MY2021_Tx" SG_ 1092 BattTracEq_B_Actl 1;
BA_ "U_U55X_MY2022_Rx" SG_ 1092 BattTracEq_B_Actl 1;
BA_ "U_CD542_MY2021_Rx" SG_ 1092 BattTracEq_B_Actl 1;
BA_ "ECGUsedRxSignal" SG_ 1092 BattTracEq_B_Actl 1;
BA_ "U_CD542_MY2021_Tx" SG_ 1092 BattTracCell_U_Mn 1;
BA_ "U_CX727_MY2021_Tx" SG_ 1092 BattTracCell_U_Mn 1;
BA_ "U_U55X_MY2022_Rx" SG_ 1092 BattTracCell_U_Mn 1;
BA_ "U_CD542_MY2021_Rx" SG_ 1092 BattTracCell_U_Mn 1;
BA_ "ECGUsedRxSignal" SG_ 1092 BattTracCell_U_Mn 1;
BA_ "U_CD542_MY2021_Tx" SG_ 1092 BattTracUMn_B_Stat 1;
BA_ "U_CX727_MY2021_Tx" SG_ 1092 BattTracUMn_B_Stat 1;
BA_ "U_U55X_MY2022_Rx" SG_ 1092 BattTracUMn_B_Stat 1;
BA_ "U_CD542_MY2021_Rx" SG_ 1092 BattTracUMn_B_Stat 1;
BA_ "ECGUsedRxSignal" SG_ 1092 BattTracUMn_B_Stat 1;
BA_ "U_CD542_MY2021_Tx" SG_ 1092 BattTracUAlrm_B_Stat 1;
BA_ "U_CX727_MY2021_Tx" SG_ 1092 BattTracUAlrm_B_Stat 1;
BA_ "U_U55X_MY2022_Rx" SG_ 1092 BattTracUAlrm_B_Stat 1;
BA_ "U_CD542_MY2021_Rx" SG_ 1092 BattTracUAlrm_B_Stat 1;
BA_ "ECGUsedRxSignal" SG_ 1092 BattTracUAlrm_B_Stat 1;
BA_ "U_U55X_MY2022_Rx" SG_ 1092 BattTracTeMn_B_Stat 1;
BA_ "U_CD542_MY2021_Rx" SG_ 1092 BattTracTeMn_B_Stat 1;
BA_ "ECGUsedRxSignal" SG_ 1092 BattTracTeMn_B_Stat 1;
BA_ "U_CD542_MY2021_Tx" SG_ 1092 BattTracInsltn_R_Actl 1;
BA_ "U_CX727_MY2021_Tx" SG_ 1092 BattTracInsltn_R_Actl 1;
BA_ "U_U55X_MY2022_Rx" SG_ 1092 BattTracInsltn_R_Actl 1;
BA_ "U_CD542_MY2021_Rx" SG_ 1092 BattTracInsltn_R_Actl 1;
BA_ "ECGUsedRxSignal" SG_ 1092 BattTracInsltn_R_Actl 1;
BA_ "GenSigStartValue" SG_ 1092 BattTracInsltn_R_Actl 255;
BA_ "GenSigStartValueInteger" SG_ 1092 BattTracInsltn_R_Actl 255;
BA_ "U_U55X_MY2022_Rx" SG_ 1075 AwdLck_Tq_Rq 1;
BA_ "ContentDependant" SG_ 1075 AwdLck_Tq_Rq 1;
BA_ "GenSigStartValue" SG_ 126 StePinRelInit_An_Sns 65535;
BA_ "ContentDependant" SG_ 126 StePinRelInit_An_Sns 1;
BA_ "GenSigStartValueInteger" SG_ 126 StePinRelInit_An_Sns 65535;
BA_ "U_CD764_MY2022_Rx" SG_ 126 StePinCompAnEst_D_Qf 1;
BA_ "U_CD542_MY2021_Rx" SG_ 126 StePinCompAnEst_D_Qf 1;
BA_ "U_T6_MCA_MY2020_Rx" SG_ 126 StePinCompAnEst_D_Qf 1;
BA_ "U_P702_MY2021_Rx" SG_ 126 StePinCompAnEst_D_Qf 1;
BA_ "U_CX727_MY2021_Rx" SG_ 126 StePinCompAnEst_D_Qf 1;
BA_ "U_U55X_MY2022_Rx" SG_ 126 StePinCompAnEst_D_Qf 1;
BA_ "GenSigStartValue" SG_ 126 StePinCompAnEst_D_Qf 1;
BA_ "MetaData" SG_ 126 StePinCompAnEst_D_Qf 1;
BA_ "GenSigStartValueInteger" SG_ 126 StePinCompAnEst_D_Qf 1;
BA_ "U_CD764_MY2022_Rx" SG_ 126 StePinComp_An_Est 1;
BA_ "U_CD542_MY2021_Rx" SG_ 126 StePinComp_An_Est 1;
BA_ "U_T6_MCA_MY2020_Rx" SG_ 126 StePinComp_An_Est 1;
BA_ "U_P702_MY2021_Rx" SG_ 126 StePinComp_An_Est 1;
BA_ "U_CX727_MY2021_Rx" SG_ 126 StePinComp_An_Est 1;
BA_ "U_U55X_MY2022_Rx" SG_ 126 StePinComp_An_Est 1;
BA_ "GenSigStartValueInteger" SG_ 126 StePinComp_An_Est 16000;
BA_ "MetaData" SG_ 126 StePinAn_No_Cs 1;
BA_ "ContentDependant" SG_ 126 StePinAn_No_Cs 1;
BA_ "MetaData" SG_ 126 StePinAn_No_Cnt 1;
BA_ "U_CD542_MY2021_Rx" SG_ 1872 TesterPhysicalReqPACM 1;
BA_ "U_P702_MY2021_Rx" SG_ 1872 TesterPhysicalReqPACM 1;
BA_ "U_CX727_MY2021_Rx" SG_ 1872 TesterPhysicalReqPACM 1;
BA_ "GenSigSendType" SG_ 1872 TesterPhysicalReqPACM 3;
BA_ "U_CD542_MY2021_Tx" SG_ 1880 TesterPhysicalResPACM 1;
BA_ "U_P702_MY2021_Tx" SG_ 1880 TesterPhysicalResPACM 1;
BA_ "U_CX727_MY2021_Tx" SG_ 1880 TesterPhysicalResPACM 1;
BA_ "GenSigSendType" SG_ 1880 TesterPhysicalResPACM 3;
BA_ "MetaData" SG_ 118 ApaBrkErrDStat_No_Cs 1;
BA_ "MetaData" SG_ 118 ApaBrkErrDStat_No_Cnt 1;
BA_ "GenSigStartValue" SG_ 118 ApaBrkErr_D_Stat 2;
BA_ "U_CD764_MY2022_Rx" SG_ 118 SteWhlCompAnEst_D_Qf 1;
BA_ "U_U55X_MY2022_Rx" SG_ 118 SteWhlCompAnEst_D_Qf 1;
BA_ "U_CD542_MY2021_Rx" SG_ 118 SteWhlCompAnEst_D_Qf 1;
BA_ "U_T6_MCA_MY2020_Rx" SG_ 118 SteWhlCompAnEst_D_Qf 1;
BA_ "U_P702_MY2021_Rx" SG_ 118 SteWhlCompAnEst_D_Qf 1;
BA_ "U_CX727_MY2021_Rx" SG_ 118 SteWhlCompAnEst_D_Qf 1;
BA_ "MetaData" SG_ 118 SteWhlCompAnEst_D_Qf 1;
BA_ "ContentDependant" SG_ 118 SteWhlCompAnEst_D_Qf 1;
BA_ "U_CD764_MY2022_Rx" SG_ 118 SteWhlComp_An_Est 1;
BA_ "U_U55X_MY2022_Rx" SG_ 118 SteWhlComp_An_Est 1;
BA_ "U_CD542_MY2021_Rx" SG_ 118 SteWhlComp_An_Est 1;
BA_ "U_T6_MCA_MY2020_Rx" SG_ 118 SteWhlComp_An_Est 1;
BA_ "U_P702_MY2021_Rx" SG_ 118 SteWhlComp_An_Est 1;
BA_ "U_CX727_MY2021_Rx" SG_ 118 SteWhlComp_An_Est 1;
BA_ "ContentDependant" SG_ 118 SteWhlComp_An_Est 1;
BA_ "GenSigStartValueInteger" SG_ 118 DrvSte_Tq_Rq 128;
BA_ "U_CD764_MY2022_Rx" SG_ 118 EmgcyBrkLamp_D_Rq 1;
BA_ "U_U55X_MY2022_Rx" SG_ 118 EmgcyBrkLamp_D_Rq 1;
BA_ "U_CD542_MY2021_Rx" SG_ 118 EmgcyBrkLamp_D_Rq 1;
BA_ "U_T6_MCA_MY2020_Rx" SG_ 118 EmgcyBrkLamp_D_Rq 1;
BA_ "U_P702_MY2021_Rx" SG_ 118 EmgcyBrkLamp_D_Rq 1;
BA_ "U_CX727_MY2021_Rx" SG_ 118 EmgcyBrkLamp_D_Rq 1;
BA_ "U_CD764_MY2022_Rx" SG_ 118 StopLamp_B_RqBrk 1;
BA_ "U_CD542_MY2021_Rx" SG_ 118 StopLamp_B_RqBrk 1;
BA_ "U_CX727_MY2021_Rx" SG_ 118 StopLamp_B_RqBrk 1;
BA_ "U_U55X_MY2022_Rx" SG_ 118 StopLamp_B_RqBrk 1;
BA_ "U_T6_MCA_MY2020_Rx" SG_ 118 StopLamp_B_RqBrk 1;
BA_ "U_P702_MY2021_Rx" SG_ 118 StopLamp_B_RqBrk 1;
BA_ "U_CD764_MY2022_Rx" SG_ 1079 DrLatchRr_B_Falt 1;
BA_ "U_U55X_MY2022_Rx" SG_ 1079 DrLatchRr_B_Falt 1;
BA_ "U_CD542_MY2021_Rx" SG_ 1079 DrLatchRr_B_Falt 1;
BA_ "U_T6_MCA_MY2020_Rx" SG_ 1079 DrLatchRr_B_Falt 1;
BA_ "U_P702_MY2021_Rx" SG_ 1079 DrLatchRr_B_Falt 1;
BA_ "U_CX727_MY2021_Rx" SG_ 1079 DrLatchRr_B_Falt 1;
BA_ "U_CD764_MY2022_Rx" SG_ 1079 DrLatchRl_B_Falt 1;
BA_ "U_U55X_MY2022_Rx" SG_ 1079 DrLatchRl_B_Falt 1;
BA_ "U_CD542_MY2021_Rx" SG_ 1079 DrLatchRl_B_Falt 1;
BA_ "U_T6_MCA_MY2020_Rx" SG_ 1079 DrLatchRl_B_Falt 1;
BA_ "U_P702_MY2021_Rx" SG_ 1079 DrLatchRl_B_Falt 1;
BA_ "U_CX727_MY2021_Rx" SG_ 1079 DrLatchRl_B_Falt 1;
BA_ "U_CD764_MY2022_Rx" SG_ 1079 DrLatchLckRr_B_Stat 1;
BA_ "U_U55X_MY2022_Rx" SG_ 1079 DrLatchLckRr_B_Stat 1;
BA_ "U_CD542_MY2021_Rx" SG_ 1079 DrLatchLckRr_B_Stat 1;
BA_ "U_T6_MCA_MY2020_Rx" SG_ 1079 DrLatchLckRr_B_Stat 1;
BA_ "U_P702_MY2021_Rx" SG_ 1079 DrLatchLckRr_B_Stat 1;
BA_ "U_CX727_MY2021_Rx" SG_ 1079 DrLatchLckRr_B_Stat 1;
BA_ "U_CD764_MY2022_Rx" SG_ 1079 DrLatchLckRl_B_Stat 1;
BA_ "U_U55X_MY2022_Rx" SG_ 1079 DrLatchLckRl_B_Stat 1;
BA_ "U_CD542_MY2021_Rx" SG_ 1079 DrLatchLckRl_B_Stat 1;
BA_ "U_T6_MCA_MY2020_Rx" SG_ 1079 DrLatchLckRl_B_Stat 1;
BA_ "U_P702_MY2021_Rx" SG_ 1079 DrLatchLckRl_B_Stat 1;
BA_ "U_CX727_MY2021_Rx" SG_ 1079 DrLatchLckRl_B_Stat 1;
BA_ "U_CD764_MY2022_Rx" SG_ 1079 DrLatchLckFr_B_Stat 1;
BA_ "U_U55X_MY2022_Rx" SG_ 1079 DrLatchLckFr_B_Stat 1;
BA_ "U_CD542_MY2021_Rx" SG_ 1079 DrLatchLckFr_B_Stat 1;
BA_ "U_T6_MCA_MY2020_Rx" SG_ 1079 DrLatchLckFr_B_Stat 1;
BA_ "U_P702_MY2021_Rx" SG_ 1079 DrLatchLckFr_B_Stat 1;
BA_ "U_CX727_MY2021_Rx" SG_ 1079 DrLatchLckFr_B_Stat 1;
BA_ "U_CD764_MY2022_Rx" SG_ 1079 DrLatchLckFl_B_Stat 1;
BA_ "U_U55X_MY2022_Rx" SG_ 1079 DrLatchLckFl_B_Stat 1;
BA_ "U_CD542_MY2021_Rx" SG_ 1079 DrLatchLckFl_B_Stat 1;
BA_ "U_T6_MCA_MY2020_Rx" SG_ 1079 DrLatchLckFl_B_Stat 1;
BA_ "U_P702_MY2021_Rx" SG_ 1079 DrLatchLckFl_B_Stat 1;
BA_ "U_CX727_MY2021_Rx" SG_ 1079 DrLatchLckFl_B_Stat 1;
BA_ "U_CD764_MY2022_Rx" SG_ 1079 DrLatchFr_B_Falt 1;
BA_ "U_U55X_MY2022_Rx" SG_ 1079 DrLatchFr_B_Falt 1;
BA_ "U_CD542_MY2021_Rx" SG_ 1079 DrLatchFr_B_Falt 1;
BA_ "U_T6_MCA_MY2020_Rx" SG_ 1079 DrLatchFr_B_Falt 1;
BA_ "U_P702_MY2021_Rx" SG_ 1079 DrLatchFr_B_Falt 1;
BA_ "U_CX727_MY2021_Rx" SG_ 1079 DrLatchFr_B_Falt 1;
BA_ "U_CD764_MY2022_Rx" SG_ 1079 DrLatchFl_B_Falt 1;
BA_ "U_U55X_MY2022_Rx" SG_ 1079 DrLatchFl_B_Falt 1;
BA_ "U_CD542_MY2021_Rx" SG_ 1079 DrLatchFl_B_Falt 1;
BA_ "U_T6_MCA_MY2020_Rx" SG_ 1079 DrLatchFl_B_Falt 1;
BA_ "U_P702_MY2021_Rx" SG_ 1079 DrLatchFl_B_Falt 1;
BA_ "U_CX727_MY2021_Rx" SG_ 1079 DrLatchFl_B_Falt 1;
BA_ "U_CD764_MY2022_Rx" SG_ 1079 DrLatchCntRr_No_Actl 1;
BA_ "U_U55X_MY2022_Rx" SG_ 1079 DrLatchCntRr_No_Actl 1;
BA_ "U_CD542_MY2021_Rx" SG_ 1079 DrLatchCntRr_No_Actl 1;
BA_ "U_T6_MCA_MY2020_Rx" SG_ 1079 DrLatchCntRr_No_Actl 1;
BA_ "U_P702_MY2021_Rx" SG_ 1079 DrLatchCntRr_No_Actl 1;
BA_ "U_CX727_MY2021_Rx" SG_ 1079 DrLatchCntRr_No_Actl 1;
BA_ "U_CD764_MY2022_Rx" SG_ 1079 DrLatchCntRl_No_Actl 1;
BA_ "U_U55X_MY2022_Rx" SG_ 1079 DrLatchCntRl_No_Actl 1;
BA_ "U_CD542_MY2021_Rx" SG_ 1079 DrLatchCntRl_No_Actl 1;
BA_ "U_T6_MCA_MY2020_Rx" SG_ 1079 DrLatchCntRl_No_Actl 1;
BA_ "U_P702_MY2021_Rx" SG_ 1079 DrLatchCntRl_No_Actl 1;
BA_ "U_CX727_MY2021_Rx" SG_ 1079 DrLatchCntRl_No_Actl 1;
BA_ "U_CD764_MY2022_Rx" SG_ 1079 DrLatchCntFr_No_Actl 1;
BA_ "U_U55X_MY2022_Rx" SG_ 1079 DrLatchCntFr_No_Actl 1;
BA_ "U_CD542_MY2021_Rx" SG_ 1079 DrLatchCntFr_No_Actl 1;
BA_ "U_T6_MCA_MY2020_Rx" SG_ 1079 DrLatchCntFr_No_Actl 1;
BA_ "U_P702_MY2021_Rx" SG_ 1079 DrLatchCntFr_No_Actl 1;
BA_ "U_CX727_MY2021_Rx" SG_ 1079 DrLatchCntFr_No_Actl 1;
BA_ "U_CD764_MY2022_Rx" SG_ 1079 DrLatchCntFl_No_Actl 1;
BA_ "U_U55X_MY2022_Rx" SG_ 1079 DrLatchCntFl_No_Actl 1;
BA_ "U_CD542_MY2021_Rx" SG_ 1079 DrLatchCntFl_No_Actl 1;
BA_ "U_T6_MCA_MY2020_Rx" SG_ 1079 DrLatchCntFl_No_Actl 1;
BA_ "U_P702_MY2021_Rx" SG_ 1079 DrLatchCntFl_No_Actl 1;
BA_ "U_CX727_MY2021_Rx" SG_ 1079 DrLatchCntFl_No_Actl 1;
BA_ "U_CD764_MY2022_Rx" SG_ 1079 ChildLckFdbckRr_B_Stat 1;
BA_ "U_U55X_MY2022_Rx" SG_ 1079 ChildLckFdbckRr_B_Stat 1;
BA_ "U_CD542_MY2021_Rx" SG_ 1079 ChildLckFdbckRr_B_Stat 1;
BA_ "U_T6_MCA_MY2020_Rx" SG_ 1079 ChildLckFdbckRr_B_Stat 1;
BA_ "U_P702_MY2021_Rx" SG_ 1079 ChildLckFdbckRr_B_Stat 1;
BA_ "U_CX727_MY2021_Rx" SG_ 1079 ChildLckFdbckRr_B_Stat 1;
BA_ "U_CD764_MY2022_Rx" SG_ 1079 ChildLckFdbckRl_B_Stat 1;
BA_ "U_U55X_MY2022_Rx" SG_ 1079 ChildLckFdbckRl_B_Stat 1;
BA_ "U_CD542_MY2021_Rx" SG_ 1079 ChildLckFdbckRl_B_Stat 1;
BA_ "U_T6_MCA_MY2020_Rx" SG_ 1079 ChildLckFdbckRl_B_Stat 1;
BA_ "U_P702_MY2021_Rx" SG_ 1079 ChildLckFdbckRl_B_Stat 1;
BA_ "U_CX727_MY2021_Rx" SG_ 1079 ChildLckFdbckRl_B_Stat 1;
BA_ "GenSigSendType" SG_ 954 ExtLghtFront_D_RqBody 3;
BA_ "GenSigStartValue" SG_ 954 ExtLghtFront_D_RqBody 1;
BA_ "WakeupSignal" SG_ 954 ExtLghtFront_D_RqBody 1;
BA_ "U_CD764_MY2022_Tx" SG_ 954 VehWlcmFrwlMde_D_Stat 1;
BA_ "U_U55X_MY2022_Tx" SG_ 954 VehWlcmFrwlMde_D_Stat 1;
BA_ "U_CD542_MY2021_Tx" SG_ 954 VehWlcmFrwlMde_D_Stat 1;
BA_ "U_T6_MCA_MY2020_Tx" SG_ 954 VehWlcmFrwlMde_D_Stat 1;
BA_ "GenSigSendType" SG_ 954 VehWlcmFrwlMde_D_Stat 3;
BA_ "WakeupSignal" SG_ 954 VehWlcmFrwlMde_D_Stat 1;
BA_ "U_CD764_MY2022_Rx" SG_ 954 CrtsyLghtRear_D_Stat 1;
BA_ "ECGUsedRxSignal" SG_ 954 CrtsyLghtRear_D_Stat 1;
BA_ "GenSigSendType" SG_ 954 CrtsyLghtRear_D_Stat 3;
BA_ "U_U55X_MY2022_Tx" SG_ 954 PosLghtFl_D_Stat 1;
BA_ "GenSigSendType" SG_ 954 PosLghtFl_D_Stat 3;
BA_ "U_U55X_MY2022_Tx" SG_ 954 PosLghtFr_D_Stat 1;
BA_ "GenSigSendType" SG_ 954 PosLghtFr_D_Stat 3;
BA_ "U_U55X_MY2022_Tx" SG_ 954 CargoLght_D_Stat 1;
BA_ "U_CD764_MY2022_Rx" SG_ 954 CargoLght_D_Stat 1;
BA_ "U_U55X_MY2022_Rx" SG_ 954 CargoLght_D_Stat 1;
BA_ "U_CD542_MY2021_Rx" SG_ 954 CargoLght_D_Stat 1;
BA_ "ECGUsedRxSignal" SG_ 954 CargoLght_D_Stat 1;
BA_ "U_T6_MCA_MY2020_Rx" SG_ 954 CargoLght_D_Stat 1;
BA_ "GenSigSendType" SG_ 954 CargoLght_D_Stat 3;
BA_ "U_U55X_MY2022_Tx" SG_ 954 TlghtTestLght_D_Stat 1;
BA_ "U_T6_MCA_MY2020_Tx" SG_ 954 TlghtTestLght_D_Stat 1;
BA_ "U_CD764_MY2022_Rx" SG_ 954 TlghtTestLght_D_Stat 1;
BA_ "U_U55X_MY2022_Rx" SG_ 954 TlghtTestLght_D_Stat 1;
BA_ "U_CD542_MY2021_Rx" SG_ 954 TlghtTestLght_D_Stat 1;
BA_ "ECGUsedRxSignal" SG_ 954 TlghtTestLght_D_Stat 1;
BA_ "U_T6_MCA_MY2020_Rx" SG_ 954 TlghtTestLght_D_Stat 1;
BA_ "GenSigSendType" SG_ 954 TlghtTestLght_D_Stat 3;
BA_ "U_CD764_MY2022_Tx" SG_ 954 LghtAmbDrvMde_B_Stat 1;
BA_ "U_CD542_MY2021_Tx" SG_ 954 LghtAmbDrvMde_B_Stat 1;
BA_ "GenSigSendType" SG_ 954 LghtAmbDrvMde_B_Stat 3;
BA_ "WakeupSignal" SG_ 954 LghtAmbDrvMde_B_Stat 1;
BA_ "U_U55X_MY2022_Tx" SG_ 954 KeylessIdl_B_Stat 1;
BA_ "U_T6_MCA_MY2020_Tx" SG_ 954 KeylessIdl_B_Stat 1;
BA_ "GenSigSendType" SG_ 954 KeylessIdl_B_Stat 3;
BA_ "U_CD764_MY2022_Tx" SG_ 954 PwRnngBoardPoll_D_Stat 1;
BA_ "U_U55X_MY2022_Tx" SG_ 954 PwRnngBoardPoll_D_Stat 1;
BA_ "U_CD542_MY2021_Tx" SG_ 954 PwRnngBoardPoll_D_Stat 1;
BA_ "U_T6_MCA_MY2020_Tx" SG_ 954 PwRnngBoardPoll_D_Stat 1;
BA_ "GenSigSendType" SG_ 954 PwRnngBoardPoll_D_Stat 3;
BA_ "WakeupSignal" SG_ 954 PwRnngBoardPoll_D_Stat 1;
BA_ "U_U55X_MY2022_Tx" SG_ 954 GenericSwtch3_No_Actl 1;
BA_ "U_T6_MCA_MY2020_Tx" SG_ 954 GenericSwtch3_No_Actl 1;
BA_ "U_P702_MY2021_Tx" SG_ 954 GenericSwtch3_No_Actl 1;
BA_ "GenSigSendType" SG_ 954 GenericSwtch3_No_Actl 3;
BA_ "U_U55X_MY2022_Tx" SG_ 954 GenericSwtch2_No_Actl 1;
BA_ "U_T6_MCA_MY2020_Tx" SG_ 954 GenericSwtch2_No_Actl 1;
BA_ "U_P702_MY2021_Tx" SG_ 954 GenericSwtch2_No_Actl 1;
BA_ "GenSigSendType" SG_ 954 GenericSwtch2_No_Actl 3;
BA_ "ContentDependant" SG_ 954 GenericSwtch2_No_Actl 1;
BA_ "U_U55X_MY2022_Tx" SG_ 954 GenericSwtch1_No_Actl 1;
BA_ "U_T6_MCA_MY2020_Tx" SG_ 954 GenericSwtch1_No_Actl 1;
BA_ "U_P702_MY2021_Tx" SG_ 954 GenericSwtch1_No_Actl 1;
BA_ "GenSigSendType" SG_ 954 GenericSwtch1_No_Actl 3;
BA_ "U_U55X_MY2022_Tx" SG_ 954 PudSptLghtRight_D_Rq 1;
BA_ "U_T6_MCA_MY2020_Tx" SG_ 954 PudSptLghtRight_D_Rq 1;
BA_ "U_P702_MY2021_Tx" SG_ 954 PudSptLghtRight_D_Rq 1;
BA_ "GenSigSendType" SG_ 954 PudSptLghtRight_D_Rq 3;
BA_ "WakeupSignal" SG_ 954 PudSptLghtRight_D_Rq 1;
BA_ "U_U55X_MY2022_Tx" SG_ 954 PudSptLghtLeft_D_Rq 1;
BA_ "U_T6_MCA_MY2020_Tx" SG_ 954 PudSptLghtLeft_D_Rq 1;
BA_ "U_P702_MY2021_Tx" SG_ 954 PudSptLghtLeft_D_Rq 1;
BA_ "GenSigSendType" SG_ 954 PudSptLghtLeft_D_Rq 3;
BA_ "WakeupSignal" SG_ 954 PudSptLghtLeft_D_Rq 1;
BA_ "U_U55X_MY2022_Tx" SG_ 954 ExtLghtRight_D_Stat 1;
BA_ "U_T6_MCA_MY2020_Tx" SG_ 954 ExtLghtRight_D_Stat 1;
BA_ "U_P702_MY2021_Tx" SG_ 954 ExtLghtRight_D_Stat 1;
BA_ "U_CD764_MY2022_Rx" SG_ 954 ExtLghtRight_D_Stat 1;
BA_ "U_U55X_MY2022_Rx" SG_ 954 ExtLghtRight_D_Stat 1;
BA_ "U_CD542_MY2021_Rx" SG_ 954 ExtLghtRight_D_Stat 1;
BA_ "ECGUsedRxSignal" SG_ 954 ExtLghtRight_D_Stat 1;
BA_ "U_T6_MCA_MY2020_Rx" SG_ 954 ExtLghtRight_D_Stat 1;
BA_ "GenSigSendType" SG_ 954 ExtLghtRight_D_Stat 3;
BA_ "WakeupSignal" SG_ 954 ExtLghtRight_D_Stat 1;
BA_ "U_T6_MCA_MY2020_Tx" SG_ 954 PoliceDmngLvl_D_Stat 1;
BA_ "U_CD764_MY2022_Rx" SG_ 954 PoliceDmngLvl_D_Stat 1;
BA_ "U_U55X_MY2022_Rx" SG_ 954 PoliceDmngLvl_D_Stat 1;
BA_ "U_CD542_MY2021_Rx" SG_ 954 PoliceDmngLvl_D_Stat 1;
BA_ "ECGUsedRxSignal" SG_ 954 PoliceDmngLvl_D_Stat 1;
BA_ "U_T6_MCA_MY2020_Rx" SG_ 954 PoliceDmngLvl_D_Stat 1;
BA_ "GenSigSendType" SG_ 954 PoliceDmngLvl_D_Stat 3;
BA_ "U_U55X_MY2022_Tx" SG_ 954 TrlrHitchLamp_D_Stat 1;
BA_ "U_T6_MCA_MY2020_Tx" SG_ 954 TrlrHitchLamp_D_Stat 1;
BA_ "U_CD764_MY2022_Rx" SG_ 954 TrlrHitchLamp_D_Stat 1;
BA_ "U_U55X_MY2022_Rx" SG_ 954 TrlrHitchLamp_D_Stat 1;
BA_ "U_CD542_MY2021_Rx" SG_ 954 TrlrHitchLamp_D_Stat 1;
BA_ "ECGUsedRxSignal" SG_ 954 TrlrHitchLamp_D_Stat 1;
BA_ "U_T6_MCA_MY2020_Rx" SG_ 954 TrlrHitchLamp_D_Stat 1;
BA_ "GenSigSendType" SG_ 954 TrlrHitchLamp_D_Stat 3;
BA_ "WakeupSignal" SG_ 954 TrlrHitchLamp_D_Stat 1;
BA_ "U_U55X_MY2022_Tx" SG_ 954 LicPlateLght_B_Stat 1;
BA_ "U_T6_MCA_MY2020_Tx" SG_ 954 LicPlateLght_B_Stat 1;
BA_ "U_CD764_MY2022_Rx" SG_ 954 LicPlateLght_B_Stat 1;
BA_ "U_U55X_MY2022_Rx" SG_ 954 LicPlateLght_B_Stat 1;
BA_ "U_CD542_MY2021_Rx" SG_ 954 LicPlateLght_B_Stat 1;
BA_ "ECGUsedRxSignal" SG_ 954 LicPlateLght_B_Stat 1;
BA_ "U_T6_MCA_MY2020_Rx" SG_ 954 LicPlateLght_B_Stat 1;
BA_ "GenSigSendType" SG_ 954 LicPlateLght_B_Stat 3;
BA_ "U_U55X_MY2022_Tx" SG_ 954 TrukBedLght_B_Stat 1;
BA_ "U_T6_MCA_MY2020_Tx" SG_ 954 TrukBedLght_B_Stat 1;
BA_ "U_CD764_MY2022_Rx" SG_ 954 TrukBedLght_B_Stat 1;
BA_ "U_U55X_MY2022_Rx" SG_ 954 TrukBedLght_B_Stat 1;
BA_ "U_CD542_MY2021_Rx" SG_ 954 TrukBedLght_B_Stat 1;
BA_ "ECGUsedRxSignal" SG_ 954 TrukBedLght_B_Stat 1;
BA_ "U_T6_MCA_MY2020_Rx" SG_ 954 TrukBedLght_B_Stat 1;
BA_ "GenSigSendType" SG_ 954 TrukBedLght_B_Stat 3;
BA_ "WakeupSignal" SG_ 954 TrukBedLght_B_Stat 1;
BA_ "U_CD764_MY2022_Tx" SG_ 954 VehWlcmFrwl_D_Stat 1;
BA_ "U_U55X_MY2022_Tx" SG_ 954 VehWlcmFrwl_D_Stat 1;
BA_ "U_CD542_MY2021_Tx" SG_ 954 VehWlcmFrwl_D_Stat 1;
BA_ "U_T6_MCA_MY2020_Tx" SG_ 954 VehWlcmFrwl_D_Stat 1;
BA_ "GenSigSendType" SG_ 954 VehWlcmFrwl_D_Stat 3;
BA_ "WakeupSignal" SG_ 954 VehWlcmFrwl_D_Stat 1;
BA_ "U_U55X_MY2022_Tx" SG_ 954 TlghtTestPrecnd_D_Stat 1;
BA_ "U_T6_MCA_MY2020_Tx" SG_ 954 TlghtTestPrecnd_D_Stat 1;
BA_ "U_CD764_MY2022_Rx" SG_ 954 TlghtTestPrecnd_D_Stat 1;
BA_ "U_U55X_MY2022_Rx" SG_ 954 TlghtTestPrecnd_D_Stat 1;
BA_ "U_CD542_MY2021_Rx" SG_ 954 TlghtTestPrecnd_D_Stat 1;
BA_ "ECGUsedRxSignal" SG_ 954 TlghtTestPrecnd_D_Stat 1;
BA_ "U_T6_MCA_MY2020_Rx" SG_ 954 TlghtTestPrecnd_D_Stat 1;
BA_ "GenSigSendType" SG_ 954 TlghtTestPrecnd_D_Stat 3;
BA_ "U_U55X_MY2022_Tx" SG_ 954 TlghtTest_D_Stat 1;
BA_ "U_T6_MCA_MY2020_Tx" SG_ 954 TlghtTest_D_Stat 1;
BA_ "U_CD764_MY2022_Rx" SG_ 954 TlghtTest_D_Stat 1;
BA_ "U_U55X_MY2022_Rx" SG_ 954 TlghtTest_D_Stat 1;
BA_ "U_CD542_MY2021_Rx" SG_ 954 TlghtTest_D_Stat 1;
BA_ "ECGUsedRxSignal" SG_ 954 TlghtTest_D_Stat 1;
BA_ "U_T6_MCA_MY2020_Rx" SG_ 954 TlghtTest_D_Stat 1;
BA_ "GenSigSendType" SG_ 954 TlghtTest_D_Stat 3;
BA_ "U_U55X_MY2022_Tx" SG_ 954 ExtLghtRear_D_Stat 1;
BA_ "U_T6_MCA_MY2020_Tx" SG_ 954 ExtLghtRear_D_Stat 1;
BA_ "U_P702_MY2021_Tx" SG_ 954 ExtLghtRear_D_Stat 1;
BA_ "U_CD764_MY2022_Rx" SG_ 954 ExtLghtRear_D_Stat 1;
BA_ "U_U55X_MY2022_Rx" SG_ 954 ExtLghtRear_D_Stat 1;
BA_ "U_CD542_MY2021_Rx" SG_ 954 ExtLghtRear_D_Stat 1;
BA_ "ECGUsedRxSignal" SG_ 954 ExtLghtRear_D_Stat 1;
BA_ "U_T6_MCA_MY2020_Rx" SG_ 954 ExtLghtRear_D_Stat 1;
BA_ "GenSigSendType" SG_ 954 ExtLghtRear_D_Stat 3;
BA_ "WakeupSignal" SG_ 954 ExtLghtRear_D_Stat 1;
BA_ "U_U55X_MY2022_Tx" SG_ 954 ExtLghtLeft_D_Stat 1;
BA_ "U_T6_MCA_MY2020_Tx" SG_ 954 ExtLghtLeft_D_Stat 1;
BA_ "U_P702_MY2021_Tx" SG_ 954 ExtLghtLeft_D_Stat 1;
BA_ "U_CD764_MY2022_Rx" SG_ 954 ExtLghtLeft_D_Stat 1;
BA_ "U_U55X_MY2022_Rx" SG_ 954 ExtLghtLeft_D_Stat 1;
BA_ "U_CD542_MY2021_Rx" SG_ 954 ExtLghtLeft_D_Stat 1;
BA_ "ECGUsedRxSignal" SG_ 954 ExtLghtLeft_D_Stat 1;
BA_ "U_T6_MCA_MY2020_Rx" SG_ 954 ExtLghtLeft_D_Stat 1;
BA_ "GenSigSendType" SG_ 954 ExtLghtLeft_D_Stat 3;
BA_ "WakeupSignal" SG_ 954 ExtLghtLeft_D_Stat 1;
BA_ "U_U55X_MY2022_Tx" SG_ 954 ExtLghtAlrt_B_Rq 1;
BA_ "U_T6_MCA_MY2020_Tx" SG_ 954 ExtLghtAlrt_B_Rq 1;
BA_ "U_P702_MY2021_Tx" SG_ 954 ExtLghtAlrt_B_Rq 1;
BA_ "U_CD764_MY2022_Rx" SG_ 954 ExtLghtAlrt_B_Rq 1;
BA_ "U_U55X_MY2022_Rx" SG_ 954 ExtLghtAlrt_B_Rq 1;
BA_ "U_CD542_MY2021_Rx" SG_ 954 ExtLghtAlrt_B_Rq 1;
BA_ "ECGUsedRxSignal" SG_ 954 ExtLghtAlrt_B_Rq 1;
BA_ "U_T6_MCA_MY2020_Rx" SG_ 954 ExtLghtAlrt_B_Rq 1;
BA_ "GenSigSendType" SG_ 954 ExtLghtAlrt_B_Rq 3;
BA_ "WakeupSignal" SG_ 954 ExtLghtAlrt_B_Rq 1;
BA_ "U_U55X_MY2022_Tx" SG_ 954 ExtLght_D_Falt 1;
BA_ "U_T6_MCA_MY2020_Tx" SG_ 954 ExtLght_D_Falt 1;
BA_ "U_P702_MY2021_Tx" SG_ 954 ExtLght_D_Falt 1;
BA_ "U_CD764_MY2022_Rx" SG_ 954 ExtLght_D_Falt 1;
BA_ "U_U55X_MY2022_Rx" SG_ 954 ExtLght_D_Falt 1;
BA_ "U_CD542_MY2021_Rx" SG_ 954 ExtLght_D_Falt 1;
BA_ "ECGUsedRxSignal" SG_ 954 ExtLght_D_Falt 1;
BA_ "U_T6_MCA_MY2020_Rx" SG_ 954 ExtLght_D_Falt 1;
BA_ "GenSigSendType" SG_ 954 ExtLght_D_Falt 3;
BA_ "WakeupSignal" SG_ 954 ExtLght_D_Falt 1;
BA_ "U_U55X_MY2022_Tx" SG_ 954 ExtLghtFront_D_Stat 1;
BA_ "U_T6_MCA_MY2020_Tx" SG_ 954 ExtLghtFront_D_Stat 1;
BA_ "U_P702_MY2021_Tx" SG_ 954 ExtLghtFront_D_Stat 1;
BA_ "U_CD764_MY2022_Rx" SG_ 954 ExtLghtFront_D_Stat 1;
BA_ "U_U55X_MY2022_Rx" SG_ 954 ExtLghtFront_D_Stat 1;
BA_ "U_CD542_MY2021_Rx" SG_ 954 ExtLghtFront_D_Stat 1;
BA_ "ECGUsedRxSignal" SG_ 954 ExtLghtFront_D_Stat 1;
BA_ "U_T6_MCA_MY2020_Rx" SG_ 954 ExtLghtFront_D_Stat 1;
BA_ "GenSigSendType" SG_ 954 ExtLghtFront_D_Stat 3;
BA_ "WakeupSignal" SG_ 954 ExtLghtFront_D_Stat 1;
BA_ "GenSigSendType" SG_ 1118 AcChrgRdy_B_Stat 3;
BA_ "U_CX727_MY2021_Tx" SG_ 1118 DgtlCommGtwyMde_D_Rq 1;
BA_ "U_CD764_MY2022_Rx" SG_ 1118 DgtlCommGtwyMde_D_Rq 1;
BA_ "U_CD542_MY2021_Rx" SG_ 1118 DgtlCommGtwyMde_D_Rq 1;
BA_ "ECGUsedRxSignal" SG_ 1118 DgtlCommGtwyMde_D_Rq 1;
BA_ "GenSigSendType" SG_ 1118 DgtlCommGtwyMde_D_Rq 3;
BA_ "U_CD542_MY2021_Tx" SG_ 1118 ExtChrgNowButtn_B_Rq 1;
BA_ "U_CX727_MY2021_Tx" SG_ 1118 ExtChrgNowButtn_B_Rq 1;
BA_ "GenSigSendType" SG_ 1118 ExtChrgNowButtn_B_Rq 3;
BA_ "U_CD542_MY2021_Tx" SG_ 1118 CoolFanChrgr_D_Rq 1;
BA_ "U_CX727_MY2021_Tx" SG_ 1118 CoolFanChrgr_D_Rq 1;
BA_ "U_CD542_MY2021_Rx" SG_ 1118 CoolFanChrgr_D_Rq 1;
BA_ "U_CX727_MY2021_Rx" SG_ 1118 CoolFanChrgr_D_Rq 1;
BA_ "GenSigSendType" SG_ 1118 CoolFanChrgr_D_Rq 3;
BA_ "GenSigSendType" SG_ 1118 ChrgrDcOvrVolt_B_Falt 3;
BA_ "GenSigSendType" SG_ 1118 ChrgrDcOvrCurnt_B_Falt 3;
BA_ "U_CD764_MY2022_Rx" SG_ 1118 ChrgrPncEnbl_D_Stat 1;
BA_ "U_CD542_MY2021_Rx" SG_ 1118 ChrgrPncEnbl_D_Stat 1;
BA_ "ECGUsedRxSignal" SG_ 1118 ChrgrPncEnbl_D_Stat 1;
BA_ "GenSigSendType" SG_ 1118 ChrgrPncEnbl_D_Stat 3;
BA_ "GenSigStartValue" SG_ 1118 ChrgrPncEnbl_D_Stat 3;
BA_ "GenSigStartValueInteger" SG_ 1118 ChrgrPncEnbl_D_Stat 3;
BA_ "U_CD542_MY2021_Tx" SG_ 1118 ChrgrClntFlw_D_Rq 1;
BA_ "U_CX727_MY2021_Tx" SG_ 1118 ChrgrClntFlw_D_Rq 1;
BA_ "U_CD542_MY2021_Rx" SG_ 1118 ChrgrClntFlw_D_Rq 1;
BA_ "U_CX727_MY2021_Rx" SG_ 1118 ChrgrClntFlw_D_Rq 1;
BA_ "GenSigSendType" SG_ 1118 ChrgrClntFlw_D_Rq 3;
BA_ "U_CD542_MY2021_Tx" SG_ 1118 PlgStatEvnt_B_Stat 1;
BA_ "U_CX727_MY2021_Tx" SG_ 1118 PlgStatEvnt_B_Stat 1;
BA_ "U_CD542_MY2021_Rx" SG_ 1118 PlgStatEvnt_B_Stat 1;
BA_ "U_CX727_MY2021_Rx" SG_ 1118 PlgStatEvnt_B_Stat 1;
BA_ "GenSigSendType" SG_ 1118 PlgStatEvnt_B_Stat 3;
BA_ "U_CD542_MY2021_Tx" SG_ 1118 ChrgrCnnctPwr_B_Stat 1;
BA_ "U_CX727_MY2021_Tx" SG_ 1118 ChrgrCnnctPwr_B_Stat 1;
BA_ "U_CD542_MY2021_Rx" SG_ 1118 ChrgrCnnctPwr_B_Stat 1;
BA_ "U_CX727_MY2021_Rx" SG_ 1118 ChrgrCnnctPwr_B_Stat 1;
BA_ "GenSigSendType" SG_ 1118 ChrgrCnnctPwr_B_Stat 3;
BA_ "U_CD542_MY2021_Tx" SG_ 1118 ChrgrAvailEvnt_B_Stat 1;
BA_ "U_CX727_MY2021_Tx" SG_ 1118 ChrgrAvailEvnt_B_Stat 1;
BA_ "U_CD542_MY2021_Rx" SG_ 1118 ChrgrAvailEvnt_B_Stat 1;
BA_ "U_CX727_MY2021_Rx" SG_ 1118 ChrgrAvailEvnt_B_Stat 1;
BA_ "GenSigSendType" SG_ 1118 ChrgrAvailEvnt_B_Stat 3;
BA_ "U_CD542_MY2021_Tx" SG_ 1118 ChrgrSrvcRqd_B_Rq 1;
BA_ "U_CX727_MY2021_Tx" SG_ 1118 ChrgrSrvcRqd_B_Rq 1;
BA_ "U_CD764_MY2022_Rx" SG_ 1118 ChrgrSrvcRqd_B_Rq 1;
BA_ "U_CD542_MY2021_Rx" SG_ 1118 ChrgrSrvcRqd_B_Rq 1;
BA_ "ECGUsedRxSignal" SG_ 1118 ChrgrSrvcRqd_B_Rq 1;
BA_ "GenSigSendType" SG_ 1118 ChrgrSrvcRqd_B_Rq 3;
BA_ "U_CD542_MY2021_Tx" SG_ 1118 ChrgrS2Swtch_B_Stat 1;
BA_ "U_CX727_MY2021_Tx" SG_ 1118 ChrgrS2Swtch_B_Stat 1;
BA_ "GenSigSendType" SG_ 1118 ChrgrS2Swtch_B_Stat 3;
BA_ "U_CD542_MY2021_Tx" SG_ 1118 ChrgChngEvnt_B_Stat 1;
BA_ "U_CX727_MY2021_Tx" SG_ 1118 ChrgChngEvnt_B_Stat 1;
BA_ "U_CD542_MY2021_Rx" SG_ 1118 ChrgChngEvnt_B_Stat 1;
BA_ "U_CX727_MY2021_Rx" SG_ 1118 ChrgChngEvnt_B_Stat 1;
BA_ "GenSigSendType" SG_ 1118 ChrgChngEvnt_B_Stat 3;
BA_ "GenSigSendType" SG_ 1118 ChrgrCc2Cnnct_B_Falt 3;
BA_ "GenSigSendType" SG_ 1118 ChrgPortDcTeMx_B_Falt 3;
BA_ "U_CD542_MY2021_Tx" SG_ 1118 ChrgCordLck_D_Stat 1;
BA_ "U_CX727_MY2021_Tx" SG_ 1118 ChrgCordLck_D_Stat 1;
BA_ "GenSigSendType" SG_ 1118 ChrgCordLck_D_Stat 3;
BA_ "U_CD542_MY2021_Tx" SG_ 1118 ChrgrInPwMde_D_Actl 1;
BA_ "U_CX727_MY2021_Tx" SG_ 1118 ChrgrInPwMde_D_Actl 1;
BA_ "U_CD764_MY2022_Rx" SG_ 1118 ChrgrInPwMde_D_Actl 1;
BA_ "ECGUsedRxSignal" SG_ 1118 ChrgrInPwMde_D_Actl 1;
BA_ "U_CD542_MY2021_Rx" SG_ 1118 ChrgrInPwMde_D_Actl 1;
BA_ "U_CX727_MY2021_Rx" SG_ 1118 ChrgrInPwMde_D_Actl 1;
BA_ "GenSigSendType" SG_ 1118 ChrgrInPwMde_D_Actl 3;
BA_ "U_CD542_MY2021_Tx" SG_ 1118 ChrgPortDrOpen_B_Stat 1;
BA_ "U_CX727_MY2021_Tx" SG_ 1118 ChrgPortDrOpen_B_Stat 1;
BA_ "GenSigSendType" SG_ 1118 ChrgPortDrOpen_B_Stat 3;
BA_ "U_CD542_MY2021_Tx" SG_ 1118 ChrgCordChlng2_No_Actl 1;
BA_ "U_CX727_MY2021_Tx" SG_ 1118 ChrgCordChlng2_No_Actl 1;
BA_ "U_CD764_MY2022_Rx" SG_ 1118 ChrgCordChlng2_No_Actl 1;
BA_ "U_U55X_MY2022_Rx" SG_ 1118 ChrgCordChlng2_No_Actl 1;
BA_ "U_CD542_MY2021_Rx" SG_ 1118 ChrgCordChlng2_No_Actl 1;
BA_ "U_T6_MCA_MY2020_Rx" SG_ 1118 ChrgCordChlng2_No_Actl 1;
BA_ "U_P702_MY2021_Rx" SG_ 1118 ChrgCordChlng2_No_Actl 1;
BA_ "U_CX727_MY2021_Rx" SG_ 1118 ChrgCordChlng2_No_Actl 1;
BA_ "GenSigSendType" SG_ 1118 ChrgCordChlng2_No_Actl 3;
BA_ "U_CD542_MY2021_Tx" SG_ 1118 ChrgCordChlng1_No_Actl 1;
BA_ "U_CX727_MY2021_Tx" SG_ 1118 ChrgCordChlng1_No_Actl 1;
BA_ "U_CD764_MY2022_Rx" SG_ 1118 ChrgCordChlng1_No_Actl 1;
BA_ "U_U55X_MY2022_Rx" SG_ 1118 ChrgCordChlng1_No_Actl 1;
BA_ "U_CD542_MY2021_Rx" SG_ 1118 ChrgCordChlng1_No_Actl 1;
BA_ "U_T6_MCA_MY2020_Rx" SG_ 1118 ChrgCordChlng1_No_Actl 1;
BA_ "U_P702_MY2021_Rx" SG_ 1118 ChrgCordChlng1_No_Actl 1;
BA_ "U_CX727_MY2021_Rx" SG_ 1118 ChrgCordChlng1_No_Actl 1;
BA_ "GenSigSendType" SG_ 1118 ChrgCordChlng1_No_Actl 3;
BA_ "U_CD542_MY2021_Tx" SG_ 1118 ChrgCrdLck_D_Falt 1;
BA_ "GenSigSendType" SG_ 1118 ChrgCrdLck_D_Falt 3;
BA_ "U_CD764_MY2022_Tx" SG_ 953 KeyMyKeyTot_No2_Cnt 1;
BA_ "U_U55X_MY2022_Tx" SG_ 953 KeyMyKeyTot_No2_Cnt 1;
BA_ "U_CD542_MY2021_Tx" SG_ 953 KeyMyKeyTot_No2_Cnt 1;
BA_ "U_T6_MCA_MY2020_Tx" SG_ 953 KeyMyKeyTot_No2_Cnt 1;
BA_ "U_P702_MY2021_Tx" SG_ 953 KeyMyKeyTot_No2_Cnt 1;
BA_ "U_CX727_MY2021_Tx" SG_ 953 KeyMyKeyTot_No2_Cnt 1;
BA_ "U_CD764_MY2022_Tx" SG_ 953 KeyAdmnTot_No2_Cnt 1;
BA_ "U_U55X_MY2022_Tx" SG_ 953 KeyAdmnTot_No2_Cnt 1;
BA_ "U_CD542_MY2021_Tx" SG_ 953 KeyAdmnTot_No2_Cnt 1;
BA_ "U_T6_MCA_MY2020_Tx" SG_ 953 KeyAdmnTot_No2_Cnt 1;
BA_ "U_P702_MY2021_Tx" SG_ 953 KeyAdmnTot_No2_Cnt 1;
BA_ "U_CX727_MY2021_Tx" SG_ 953 KeyAdmnTot_No2_Cnt 1;
BA_ "U_CD764_MY2022_Tx" SG_ 953 PaakMyKeySearch_D_Stat 1;
BA_ "U_U55X_MY2022_Tx" SG_ 953 PaakMyKeySearch_D_Stat 1;
BA_ "U_CD542_MY2021_Tx" SG_ 953 PaakMyKeySearch_D_Stat 1;
BA_ "U_T6_MCA_MY2020_Tx" SG_ 953 PaakMyKeySearch_D_Stat 1;
BA_ "U_P702_MY2021_Tx" SG_ 953 PaakMyKeySearch_D_Stat 1;
BA_ "U_CX727_MY2021_Tx" SG_ 953 PaakMyKeySearch_D_Stat 1;
BA_ "GenSigSendType" SG_ 953 PaakMyKeySearch_D_Stat 3;
BA_ "U_CD764_MY2022_Tx" SG_ 953 BattULoChrgHyb_D_Stat 1;
BA_ "U_CD542_MY2021_Tx" SG_ 953 BattULoChrgHyb_D_Stat 1;
BA_ "U_T6_MCA_MY2020_Tx" SG_ 953 BattULoChrgHyb_D_Stat 1;
BA_ "U_CD764_MY2022_Rx" SG_ 953 BattULoChrgHyb_D_Stat 1;
BA_ "U_U55X_MY2022_Rx" SG_ 953 BattULoChrgHyb_D_Stat 1;
BA_ "U_CD542_MY2021_Rx" SG_ 953 BattULoChrgHyb_D_Stat 1;
BA_ "ECGUsedRxSignal" SG_ 953 BattULoChrgHyb_D_Stat 1;
BA_ "U_T6_MCA_MY2020_Rx" SG_ 953 BattULoChrgHyb_D_Stat 1;
BA_ "GenSigSendType" SG_ 953 BattULoChrgHyb_D_Stat 3;
BA_ "U_CD764_MY2022_Tx" SG_ 953 BattULoChrgHyb_B_Rq 1;
BA_ "U_CD542_MY2021_Tx" SG_ 953 BattULoChrgHyb_B_Rq 1;
BA_ "U_T6_MCA_MY2020_Tx" SG_ 953 BattULoChrgHyb_B_Rq 1;
BA_ "GenSigSendType" SG_ 953 BattULoChrgHyb_B_Rq 3;
BA_ "U_CD764_MY2022_Tx" SG_ 953 ChrgCordLck_B_Stat 1;
BA_ "U_U55X_MY2022_Tx" SG_ 953 ChrgCordLck_B_Stat 1;
BA_ "U_CD542_MY2021_Tx" SG_ 953 ChrgCordLck_B_Stat 1;
BA_ "U_T6_MCA_MY2020_Tx" SG_ 953 ChrgCordLck_B_Stat 1;
BA_ "U_P702_MY2021_Tx" SG_ 953 ChrgCordLck_B_Stat 1;
BA_ "U_CX727_MY2021_Tx" SG_ 953 ChrgCordLck_B_Stat 1;
BA_ "U_CD764_MY2022_Rx" SG_ 953 ChrgCordLck_B_Stat 1;
BA_ "U_U55X_MY2022_Rx" SG_ 953 ChrgCordLck_B_Stat 1;
BA_ "ECGUsedRxSignal" SG_ 953 ChrgCordLck_B_Stat 1;
BA_ "U_T6_MCA_MY2020_Rx" SG_ 953 ChrgCordLck_B_Stat 1;
BA_ "U_CD542_MY2021_Rx" SG_ 953 ChrgCordLck_B_Stat 1;
BA_ "U_CX727_MY2021_Rx" SG_ 953 ChrgCordLck_B_Stat 1;
BA_ "GenSigSendType" SG_ 953 ChrgCordLck_B_Stat 3;
BA_ "U_CD764_MY2022_Tx" SG_ 953 ChrgCordResp2_No_Actl 1;
BA_ "U_U55X_MY2022_Tx" SG_ 953 ChrgCordResp2_No_Actl 1;
BA_ "U_CD542_MY2021_Tx" SG_ 953 ChrgCordResp2_No_Actl 1;
BA_ "U_T6_MCA_MY2020_Tx" SG_ 953 ChrgCordResp2_No_Actl 1;
BA_ "U_P702_MY2021_Tx" SG_ 953 ChrgCordResp2_No_Actl 1;
BA_ "U_CX727_MY2021_Tx" SG_ 953 ChrgCordResp2_No_Actl 1;
BA_ "U_CD542_MY2021_Rx" SG_ 953 ChrgCordResp2_No_Actl 1;
BA_ "U_CX727_MY2021_Rx" SG_ 953 ChrgCordResp2_No_Actl 1;
BA_ "U_CD764_MY2022_Tx" SG_ 953 ChrgCordResp1_No_Actl 1;
BA_ "U_U55X_MY2022_Tx" SG_ 953 ChrgCordResp1_No_Actl 1;
BA_ "U_CD542_MY2021_Tx" SG_ 953 ChrgCordResp1_No_Actl 1;
BA_ "U_T6_MCA_MY2020_Tx" SG_ 953 ChrgCordResp1_No_Actl 1;
BA_ "U_P702_MY2021_Tx" SG_ 953 ChrgCordResp1_No_Actl 1;
BA_ "U_CX727_MY2021_Tx" SG_ 953 ChrgCordResp1_No_Actl 1;
BA_ "U_CD542_MY2021_Rx" SG_ 953 ChrgCordResp1_No_Actl 1;
BA_ "U_CX727_MY2021_Rx" SG_ 953 ChrgCordResp1_No_Actl 1;
BA_ "U_CD764_MY2022_Tx" SG_ 953 WakeAlarm3_D_Stat 1;
BA_ "U_U55X_MY2022_Tx" SG_ 953 WakeAlarm3_D_Stat 1;
BA_ "U_CD542_MY2021_Tx" SG_ 953 WakeAlarm3_D_Stat 1;
BA_ "U_T6_MCA_MY2020_Tx" SG_ 953 WakeAlarm3_D_Stat 1;
BA_ "U_P702_MY2021_Tx" SG_ 953 WakeAlarm3_D_Stat 1;
BA_ "U_CX727_MY2021_Tx" SG_ 953 WakeAlarm3_D_Stat 1;
BA_ "GenSigSendType" SG_ 953 WakeAlarm3_D_Stat 3;
BA_ "GenSigStartValue" SG_ 953 WakeAlarm3_D_Stat 3;
BA_ "GenSigStartValueInteger" SG_ 953 WakeAlarm3_D_Stat 3;
BA_ "U_CD764_MY2022_Tx" SG_ 953 WakeAlarm2_D_Stat 1;
BA_ "U_U55X_MY2022_Tx" SG_ 953 WakeAlarm2_D_Stat 1;
BA_ "U_CD542_MY2021_Tx" SG_ 953 WakeAlarm2_D_Stat 1;
BA_ "U_T6_MCA_MY2020_Tx" SG_ 953 WakeAlarm2_D_Stat 1;
BA_ "U_P702_MY2021_Tx" SG_ 953 WakeAlarm2_D_Stat 1;
BA_ "U_CX727_MY2021_Tx" SG_ 953 WakeAlarm2_D_Stat 1;
BA_ "GenSigSendType" SG_ 953 WakeAlarm2_D_Stat 3;
BA_ "GenSigStartValue" SG_ 953 WakeAlarm2_D_Stat 3;
BA_ "GenSigStartValueInteger" SG_ 953 WakeAlarm2_D_Stat 3;
BA_ "U_CD764_MY2022_Tx" SG_ 953 WakeAlarm1_D_Stat 1;
BA_ "U_U55X_MY2022_Tx" SG_ 953 WakeAlarm1_D_Stat 1;
BA_ "U_CD542_MY2021_Tx" SG_ 953 WakeAlarm1_D_Stat 1;
BA_ "U_T6_MCA_MY2020_Tx" SG_ 953 WakeAlarm1_D_Stat 1;
BA_ "U_P702_MY2021_Tx" SG_ 953 WakeAlarm1_D_Stat 1;
BA_ "U_CX727_MY2021_Tx" SG_ 953 WakeAlarm1_D_Stat 1;
BA_ "GenSigSendType" SG_ 953 WakeAlarm1_D_Stat 3;
BA_ "GenSigStartValue" SG_ 953 WakeAlarm1_D_Stat 3;
BA_ "GenSigStartValueInteger" SG_ 953 WakeAlarm1_D_Stat 3;
BA_ "U_CD764_MY2022_Tx" SG_ 953 WakeAlarm0_D_Stat 1;
BA_ "U_U55X_MY2022_Tx" SG_ 953 WakeAlarm0_D_Stat 1;
BA_ "U_CD542_MY2021_Tx" SG_ 953 WakeAlarm0_D_Stat 1;
BA_ "U_T6_MCA_MY2020_Tx" SG_ 953 WakeAlarm0_D_Stat 1;
BA_ "U_P702_MY2021_Tx" SG_ 953 WakeAlarm0_D_Stat 1;
BA_ "U_CX727_MY2021_Tx" SG_ 953 WakeAlarm0_D_Stat 1;
BA_ "GenSigSendType" SG_ 953 WakeAlarm0_D_Stat 3;
BA_ "GenSigStartValue" SG_ 953 WakeAlarm0_D_Stat 3;
BA_ "GenSigStartValueInteger" SG_ 953 WakeAlarm0_D_Stat 3;
BA_ "U_U55X_MY2022_Tx" SG_ 953 BattRgenLoSoc_Pc_LimLo 1;
BA_ "U_T6_MCA_MY2020_Tx" SG_ 953 BattRgenLoSoc_Pc_LimLo 1;
BA_ "U_P702_MY2021_Tx" SG_ 953 BattRgenLoSoc_Pc_LimLo 1;
BA_ "U_T6_MCA_MY2020_Rx" SG_ 953 BattRgenLoSoc_Pc_LimLo 1;
BA_ "GenSigStartValue" SG_ 953 BattRgenLoSoc_Pc_LimLo 30;
BA_ "GenSigStartValueInteger" SG_ 953 BattRgenLoSoc_Pc_LimLo 30;
BA_ "U_U55X_MY2022_Tx" SG_ 953 BattRgenLoChrg_D_Rq 1;
BA_ "U_T6_MCA_MY2020_Tx" SG_ 953 BattRgenLoChrg_D_Rq 1;
BA_ "U_P702_MY2021_Tx" SG_ 953 BattRgenLoChrg_D_Rq 1;
BA_ "U_T6_MCA_MY2020_Rx" SG_ 953 BattRgenLoChrg_D_Rq 1;
BA_ "GenSigSendType" SG_ 953 BattRgenLoChrg_D_Rq 3;
BA_ "U_U55X_MY2022_Tx" SG_ 953 BattRgenLoDChrg_D_Rq 1;
BA_ "U_T6_MCA_MY2020_Tx" SG_ 953 BattRgenLoDChrg_D_Rq 1;
BA_ "U_P702_MY2021_Tx" SG_ 953 BattRgenLoDChrg_D_Rq 1;
BA_ "U_T6_MCA_MY2020_Rx" SG_ 953 BattRgenLoDChrg_D_Rq 1;
BA_ "GenSigSendType" SG_ 953 BattRgenLoDChrg_D_Rq 3;
BA_ "U_CX727_MY2021_Tx" SG_ 1112 BattTracIsoDis_B_Stat 1;
BA_ "ECGUsedRxSignal" SG_ 1112 BattTracIsoDis_B_Stat 1;
BA_ "U_CX727_MY2021_Rx" SG_ 1112 BattTracIsoDis_B_Stat 1;
BA_ "GenSigSendType" SG_ 1112 BattTracIsoDis_B_Stat 3;
BA_ "U_CD542_MY2021_Tx" SG_ 1112 BattTrac2_E_Max 1;
BA_ "U_CX727_MY2021_Tx" SG_ 1112 BattTrac2_E_Max 1;
BA_ "U_CD764_MY2022_Rx" SG_ 1112 BattTrac2_E_Max 1;
BA_ "U_U55X_MY2022_Rx" SG_ 1112 BattTrac2_E_Max 1;
BA_ "U_CD542_MY2021_Rx" SG_ 1112 BattTrac2_E_Max 1;
BA_ "ECGUsedRxSignal" SG_ 1112 BattTrac2_E_Max 1;
BA_ "GenSigStartValue" SG_ 1112 BattTrac2_E_Max 4094;
BA_ "GenSigStartValueInteger" SG_ 1112 BattTrac2_E_Max 4094;
BA_ "GenSigSendType" SG_ 1112 BattTracHeat_D_Rq 3;
BA_ "U_CX727_MY2021_Tx" SG_ 1112 BattDcCnnct_D_Cmd 1;
BA_ "U_CX727_MY2021_Rx" SG_ 1112 BattDcCnnct_D_Cmd 1;
BA_ "GenSigSendType" SG_ 1112 BattDcCnnct_D_Cmd 3;
BA_ "U_CD542_MY2021_Tx" SG_ 1112 BattTrac2_E_Avail 1;
BA_ "U_CX727_MY2021_Tx" SG_ 1112 BattTrac2_E_Avail 1;
BA_ "U_CD764_MY2022_Rx" SG_ 1112 BattTrac2_E_Avail 1;
BA_ "U_U55X_MY2022_Rx" SG_ 1112 BattTrac2_E_Avail 1;
BA_ "U_CD542_MY2021_Rx" SG_ 1112 BattTrac2_E_Avail 1;
BA_ "ECGUsedRxSignal" SG_ 1112 BattTrac2_E_Avail 1;
BA_ "U_CD542_MY2021_Tx" SG_ 1112 BattTracCnnct_D_Cmd 1;
BA_ "U_P702_MY2021_Tx" SG_ 1112 BattTracCnnct_D_Cmd 1;
BA_ "U_CX727_MY2021_Tx" SG_ 1112 BattTracCnnct_D_Cmd 1;
BA_ "U_CD542_MY2021_Rx" SG_ 1112 BattTracCnnct_D_Cmd 1;
BA_ "U_CX727_MY2021_Rx" SG_ 1112 BattTracCnnct_D_Cmd 1;
BA_ "GenSigSendType" SG_ 1112 BattTracCnnct_D_Cmd 3;
BA_ "U_CD542_MY2021_Tx" SG_ 1112 BattTracHvilOpen_B_Stat 1;
BA_ "U_P702_MY2021_Tx" SG_ 1112 BattTracHvilOpen_B_Stat 1;
BA_ "U_CX727_MY2021_Tx" SG_ 1112 BattTracHvilOpen_B_Stat 1;
BA_ "GenSigSendType" SG_ 1112 BattTracHvilOpen_B_Stat 3;
BA_ "GenSigSendType" SG_ 1112 BattTracCoolLvl_D_Rq 3;
BA_ "U_CD764_MY2022_Rx" SG_ 1112 BattTracTeSustn_B_Rq 1;
BA_ "U_U55X_MY2022_Rx" SG_ 1112 BattTracTeSustn_B_Rq 1;
BA_ "U_CD542_MY2021_Rx" SG_ 1112 BattTracTeSustn_B_Rq 1;
BA_ "U_T6_MCA_MY2020_Rx" SG_ 1112 BattTracTeSustn_B_Rq 1;
BA_ "U_P702_MY2021_Rx" SG_ 1112 BattTracTeSustn_B_Rq 1;
BA_ "U_CX727_MY2021_Rx" SG_ 1112 BattTracTeSustn_B_Rq 1;
BA_ "GenSigSendType" SG_ 1112 BattTracTeSustn_B_Rq 3;
BA_ "U_CD542_MY2021_Tx" SG_ 1112 BattTracTeEvnt_B_Stat 1;
BA_ "U_CX727_MY2021_Tx" SG_ 1112 BattTracTeEvnt_B_Stat 1;
BA_ "U_CD542_MY2021_Rx" SG_ 1112 BattTracTeEvnt_B_Stat 1;
BA_ "U_CX727_MY2021_Rx" SG_ 1112 BattTracTeEvnt_B_Stat 1;
BA_ "GenSigSendType" SG_ 1112 BattTracTeEvnt_B_Stat 3;
BA_ "U_CD542_MY2021_Tx" SG_ 1112 BattTracDcdcDis_B_Rq 1;
BA_ "U_P702_MY2021_Tx" SG_ 1112 BattTracDcdcDis_B_Rq 1;
BA_ "U_CX727_MY2021_Tx" SG_ 1112 BattTracDcdcDis_B_Rq 1;
BA_ "GenSigSendType" SG_ 1112 BattTracDcdcDis_B_Rq 3;
BA_ "U_CD542_MY2021_Tx" SG_ 1112 BattChrgTrgtEvnt_B_Stat 1;
BA_ "U_CX727_MY2021_Tx" SG_ 1112 BattChrgTrgtEvnt_B_Stat 1;
BA_ "U_CD542_MY2021_Rx" SG_ 1112 BattChrgTrgtEvnt_B_Stat 1;
BA_ "U_CX727_MY2021_Rx" SG_ 1112 BattChrgTrgtEvnt_B_Stat 1;
BA_ "GenSigSendType" SG_ 1112 BattChrgTrgtEvnt_B_Stat 3;
BA_ "U_CD542_MY2021_Tx" SG_ 1112 BattTracDiagClr_B_Rq 1;
BA_ "U_P702_MY2021_Tx" SG_ 1112 BattTracDiagClr_B_Rq 1;
BA_ "U_CX727_MY2021_Tx" SG_ 1112 BattTracDiagClr_B_Rq 1;
BA_ "GenSigSendType" SG_ 1112 BattTracDiagClr_B_Rq 3;
BA_ "U_CD542_MY2021_Tx" SG_ 1112 BattTracHazrd_D_Stat 1;
BA_ "GenSigSendType" SG_ 1112 BattTracHazrd_D_Stat 3;
BA_ "U_CD542_MY2021_Tx" SG_ 1112 BattTracChrgSustn_B_Rq 1;
BA_ "U_CX727_MY2021_Tx" SG_ 1112 BattTracChrgSustn_B_Rq 1;
BA_ "U_CD764_MY2022_Rx" SG_ 1112 BattTracChrgSustn_B_Rq 1;
BA_ "U_U55X_MY2022_Rx" SG_ 1112 BattTracChrgSustn_B_Rq 1;
BA_ "U_T6_MCA_MY2020_Rx" SG_ 1112 BattTracChrgSustn_B_Rq 1;
BA_ "U_P702_MY2021_Rx" SG_ 1112 BattTracChrgSustn_B_Rq 1;
BA_ "U_CD542_MY2021_Rx" SG_ 1112 BattTracChrgSustn_B_Rq 1;
BA_ "U_CX727_MY2021_Rx" SG_ 1112 BattTracChrgSustn_B_Rq 1;
BA_ "GenSigSendType" SG_ 1112 BattTracChrgSustn_B_Rq 3;
BA_ "U_CD542_MY2021_Tx" SG_ 1112 HtrnClntPump_D_Stat 1;
BA_ "U_P702_MY2021_Tx" SG_ 1112 HtrnClntPump_D_Stat 1;
BA_ "U_CX727_MY2021_Tx" SG_ 1112 HtrnClntPump_D_Stat 1;
BA_ "U_P702_MY2021_Rx" SG_ 1112 HtrnClntPump_D_Stat 1;
BA_ "U_CD542_MY2021_Rx" SG_ 1112 HtrnClntPump_D_Stat 1;
BA_ "U_CX727_MY2021_Rx" SG_ 1112 HtrnClntPump_D_Stat 1;
BA_ "GenSigSendType" SG_ 1112 HtrnClntPump_D_Stat 3;
BA_ "U_CD542_MY2021_Tx" SG_ 1112 BattTracDelta_Te_Actl 1;
BA_ "U_P702_MY2021_Tx" SG_ 1112 BattTracDelta_Te_Actl 1;
BA_ "U_CX727_MY2021_Tx" SG_ 1112 BattTracDelta_Te_Actl 1;
BA_ "GenSigStartValue" SG_ 1112 BattTracDelta_Te_Actl 254;
BA_ "GenSigStartValueInteger" SG_ 1112 BattTracDelta_Te_Actl 164;
BA_ "U_CD542_MY2021_Tx" SG_ 1112 BattTracClntPmp_D_Stat 1;
BA_ "U_P702_MY2021_Tx" SG_ 1112 BattTracClntPmp_D_Stat 1;
BA_ "U_CX727_MY2021_Tx" SG_ 1112 BattTracClntPmp_D_Stat 1;
BA_ "GenSigSendType" SG_ 1112 BattTracClntPmp_D_Stat 3;
BA_ "ContentDependant" SG_ 1112 BattTracClntPmp_D_Stat 1;
BA_ "U_CD764_MY2022_Rx" SG_ 1116 RstrtRq_No_ActlUpftr 1;
BA_ "U_CD542_MY2021_Rx" SG_ 1116 RstrtRq_No_ActlUpftr 1;
BA_ "U_T6_MCA_MY2020_Rx" SG_ 1116 RstrtRq_No_ActlUpftr 1;
BA_ "U_P702_MY2021_Rx" SG_ 1116 RstrtRq_No_ActlUpftr 1;
BA_ "U_CX727_MY2021_Rx" SG_ 1116 RstrtRq_No_ActlUpftr 1;
BA_ "WakeupSignal" SG_ 1116 RstrtRq_No_ActlUpftr 1;
BA_ "U_CD764_MY2022_Rx" SG_ 1116 Rstrt_D_RqUpftr 1;
BA_ "U_CD542_MY2021_Rx" SG_ 1116 Rstrt_D_RqUpftr 1;
BA_ "U_T6_MCA_MY2020_Rx" SG_ 1116 Rstrt_D_RqUpftr 1;
BA_ "U_P702_MY2021_Rx" SG_ 1116 Rstrt_D_RqUpftr 1;
BA_ "U_CX727_MY2021_Rx" SG_ 1116 Rstrt_D_RqUpftr 1;
BA_ "GenSigSendType" SG_ 1116 Rstrt_D_RqUpftr 3;
BA_ "WakeupSignal" SG_ 1116 Rstrt_D_RqUpftr 1;
BA_ "U_CD764_MY2022_Rx" SG_ 1116 RollCode_No_ActlUpftr 1;
BA_ "U_CD542_MY2021_Rx" SG_ 1116 RollCode_No_ActlUpftr 1;
BA_ "U_T6_MCA_MY2020_Rx" SG_ 1116 RollCode_No_ActlUpftr 1;
BA_ "U_P702_MY2021_Rx" SG_ 1116 RollCode_No_ActlUpftr 1;
BA_ "U_CX727_MY2021_Rx" SG_ 1116 RollCode_No_ActlUpftr 1;
BA_ "U_CD764_MY2022_Rx" SG_ 1116 PanicRq_No_ActlUpftr 1;
BA_ "U_CD542_MY2021_Rx" SG_ 1116 PanicRq_No_ActlUpftr 1;
BA_ "U_T6_MCA_MY2020_Rx" SG_ 1116 PanicRq_No_ActlUpftr 1;
BA_ "U_P702_MY2021_Rx" SG_ 1116 PanicRq_No_ActlUpftr 1;
BA_ "U_CX727_MY2021_Rx" SG_ 1116 PanicRq_No_ActlUpftr 1;
BA_ "WakeupSignal" SG_ 1116 PanicRq_No_ActlUpftr 1;
BA_ "U_CD764_MY2022_Rx" SG_ 1116 Panic_D_RqUpftr 1;
BA_ "U_CD542_MY2021_Rx" SG_ 1116 Panic_D_RqUpftr 1;
BA_ "U_T6_MCA_MY2020_Rx" SG_ 1116 Panic_D_RqUpftr 1;
BA_ "U_P702_MY2021_Rx" SG_ 1116 Panic_D_RqUpftr 1;
BA_ "U_CX727_MY2021_Rx" SG_ 1116 Panic_D_RqUpftr 1;
BA_ "GenSigSendType" SG_ 1116 Panic_D_RqUpftr 3;
BA_ "WakeupSignal" SG_ 1116 Panic_D_RqUpftr 1;
BA_ "U_CD764_MY2022_Rx" SG_ 1116 LockRq_No_ActlUpftr 1;
BA_ "U_CD542_MY2021_Rx" SG_ 1116 LockRq_No_ActlUpftr 1;
BA_ "U_T6_MCA_MY2020_Rx" SG_ 1116 LockRq_No_ActlUpftr 1;
BA_ "U_P702_MY2021_Rx" SG_ 1116 LockRq_No_ActlUpftr 1;
BA_ "U_CX727_MY2021_Rx" SG_ 1116 LockRq_No_ActlUpftr 1;
BA_ "WakeupSignal" SG_ 1116 LockRq_No_ActlUpftr 1;
BA_ "U_CD764_MY2022_Rx" SG_ 1116 Lock_D_RqUpftr 1;
BA_ "U_CD542_MY2021_Rx" SG_ 1116 Lock_D_RqUpftr 1;
BA_ "U_T6_MCA_MY2020_Rx" SG_ 1116 Lock_D_RqUpftr 1;
BA_ "U_P702_MY2021_Rx" SG_ 1116 Lock_D_RqUpftr 1;
BA_ "U_CX727_MY2021_Rx" SG_ 1116 Lock_D_RqUpftr 1;
BA_ "GenSigSendType" SG_ 1116 Lock_D_RqUpftr 3;
BA_ "WakeupSignal" SG_ 1116 Lock_D_RqUpftr 1;
BA_ "U_CD764_MY2022_Rx" SG_ 1116 ChirpRq_No_ActlUpftr 1;
BA_ "U_CD542_MY2021_Rx" SG_ 1116 ChirpRq_No_ActlUpftr 1;
BA_ "U_T6_MCA_MY2020_Rx" SG_ 1116 ChirpRq_No_ActlUpftr 1;
BA_ "U_P702_MY2021_Rx" SG_ 1116 ChirpRq_No_ActlUpftr 1;
BA_ "U_CX727_MY2021_Rx" SG_ 1116 ChirpRq_No_ActlUpftr 1;
BA_ "WakeupSignal" SG_ 1116 ChirpRq_No_ActlUpftr 1;
BA_ "U_CD764_MY2022_Rx" SG_ 1116 Chirp_D_RqUpftr 1;
BA_ "U_CD542_MY2021_Rx" SG_ 1116 Chirp_D_RqUpftr 1;
BA_ "U_T6_MCA_MY2020_Rx" SG_ 1116 Chirp_D_RqUpftr 1;
BA_ "U_P702_MY2021_Rx" SG_ 1116 Chirp_D_RqUpftr 1;
BA_ "U_CX727_MY2021_Rx" SG_ 1116 Chirp_D_RqUpftr 1;
BA_ "GenSigSendType" SG_ 1116 Chirp_D_RqUpftr 3;
BA_ "WakeupSignal" SG_ 1116 Chirp_D_RqUpftr 1;
BA_ "U_CD542_MY2021_Rx" SG_ 1144 BattChrgTrgtSoC_D_Rq 1;
BA_ "U_CX727_MY2021_Rx" SG_ 1144 BattChrgTrgtSoC_D_Rq 1;
BA_ "GenSigSendType" SG_ 1144 PreCondBatt_B_Actl 3;
BA_ "U_U55X_MY2022_Rx" SG_ 1144 CabnEvapSovFront_B_Rq 1;
BA_ "U_CD542_MY2021_Rx" SG_ 1144 CabnEvapSovFront_B_Rq 1;
BA_ "U_P702_MY2021_Rx" SG_ 1144 CabnEvapSovFront_B_Rq 1;
BA_ "U_CX727_MY2021_Rx" SG_ 1144 CabnEvapSovFront_B_Rq 1;
BA_ "GenSigSendType" SG_ 1144 CabnEvapSovFront_B_Rq 3;
BA_ "WakeupSignal" SG_ 1144 CabnEvapSovFront_B_Rq 1;
BA_ "GenSigSendType" SG_ 1144 HeatCoreSovRear_B_Rq 3;
BA_ "WakeupSignal" SG_ 1144 HeatCoreSovRear_B_Rq 1;
BA_ "U_U55X_MY2022_Rx" SG_ 1144 BattChlrSov_B_Rq 1;
BA_ "U_CD542_MY2021_Rx" SG_ 1144 BattChlrSov_B_Rq 1;
BA_ "U_P702_MY2021_Rx" SG_ 1144 BattChlrSov_B_Rq 1;
BA_ "U_CX727_MY2021_Rx" SG_ 1144 BattChlrSov_B_Rq 1;
BA_ "GenSigSendType" SG_ 1144 BattChlrSov_B_Rq 3;
BA_ "WakeupSignal" SG_ 1144 BattChlrSov_B_Rq 1;
BA_ "GenSigSendType" SG_ 1144 CabnEvapSovRear_B_Rq 3;
BA_ "WakeupSignal" SG_ 1144 CabnEvapSovRear_B_Rq 1;
BA_ "GenSigSendType" SG_ 1144 BrkAppl_D_RqPt 3;
BA_ "GenSigSendType" SG_ 1144 BattClntVlvOvrrd_D_Rq 3;
BA_ "GenSigSendType" SG_ 1144 BattTracChillerOn_B_Rq 3;
BA_ "GenSigSendType" SG_ 1144 BattTracChiller_D_Stat 3;
BA_ "U_CD764_MY2022_Rx" SG_ 1144 ULoBattTrnsfrSustn_B_Rq 1;
BA_ "U_U55X_MY2022_Rx" SG_ 1144 ULoBattTrnsfrSustn_B_Rq 1;
BA_ "U_CD542_MY2021_Rx" SG_ 1144 ULoBattTrnsfrSustn_B_Rq 1;
BA_ "GenSigSendType" SG_ 1144 ULoBattTrnsfrSustn_B_Rq 3;
BA_ "U_CD764_MY2022_Rx" SG_ 1144 ULoBattTransfer_D_Stat 1;
BA_ "U_U55X_MY2022_Rx" SG_ 1144 ULoBattTransfer_D_Stat 1;
BA_ "U_CD542_MY2021_Rx" SG_ 1144 ULoBattTransfer_D_Stat 1;
BA_ "GenSigSendType" SG_ 1144 ULoBattTransfer_D_Stat 3;
BA_ "GenSigSendType" SG_ 1144 HtrnDcdcDis_B_Rq 3;
BA_ "U_P702_MY2021_Rx" SG_ 1144 HtrnCnnctPwr_B_Stat 1;
BA_ "U_CD542_MY2021_Rx" SG_ 1144 HtrnCnnctPwr_B_Stat 1;
BA_ "U_CX727_MY2021_Rx" SG_ 1144 HtrnCnnctPwr_B_Stat 1;
BA_ "GenSigSendType" SG_ 1144 HtrnCnnctPwr_B_Stat 3;
BA_ "GenSigSendType" SG_ 1144 PtcHtr_D_Stat 3;
BA_ "GenSigStartValue" SG_ 1144 BattChrgInhbt_D2_Rq 1;
BA_ "U_CD764_MY2022_Rx" SG_ 1144 WakeAlarm0_B_Typ 1;
BA_ "U_U55X_MY2022_Rx" SG_ 1144 WakeAlarm0_B_Typ 1;
BA_ "U_CD542_MY2021_Rx" SG_ 1144 WakeAlarm0_B_Typ 1;
BA_ "U_T6_MCA_MY2020_Rx" SG_ 1144 WakeAlarm0_B_Typ 1;
BA_ "U_P702_MY2021_Rx" SG_ 1144 WakeAlarm0_B_Typ 1;
BA_ "U_CX727_MY2021_Rx" SG_ 1144 WakeAlarm0_B_Typ 1;
BA_ "GenSigSendType" SG_ 1144 WakeAlarm0_B_Typ 3;
BA_ "U_CD764_MY2022_Rx" SG_ 1144 WakeAlarm0_T_Rq 1;
BA_ "U_U55X_MY2022_Rx" SG_ 1144 WakeAlarm0_T_Rq 1;
BA_ "U_CD542_MY2021_Rx" SG_ 1144 WakeAlarm0_T_Rq 1;
BA_ "U_T6_MCA_MY2020_Rx" SG_ 1144 WakeAlarm0_T_Rq 1;
BA_ "U_P702_MY2021_Rx" SG_ 1144 WakeAlarm0_T_Rq 1;
BA_ "U_CX727_MY2021_Rx" SG_ 1144 WakeAlarm0_T_Rq 1;
BA_ "GenSigStartValue" SG_ 1144 WakeAlarm0_T_Rq 32767;
BA_ "GenSigStartValueInteger" SG_ 1144 WakeAlarm0_T_Rq 32767;
BA_ "GenSigSendType" SG_ 1144 BattTracClimtDis_B_Stat 3;
BA_ "U_CD542_MY2021_Rx" SG_ 1144 HtrnClntFlw_D_Rq 1;
BA_ "U_P702_MY2021_Rx" SG_ 1144 HtrnClntFlw_D_Rq 1;
BA_ "U_CX727_MY2021_Rx" SG_ 1144 HtrnClntFlw_D_Rq 1;
BA_ "GenSigSendType" SG_ 1144 HtrnClntFlw_D_Rq 3;
BA_ "U_CD764_MY2022_Rx" SG_ 1144 BattTracDrvSustn_B_Rq 1;
BA_ "U_U55X_MY2022_Rx" SG_ 1144 BattTracDrvSustn_B_Rq 1;
BA_ "U_T6_MCA_MY2020_Rx" SG_ 1144 BattTracDrvSustn_B_Rq 1;
BA_ "U_P702_MY2021_Rx" SG_ 1144 BattTracDrvSustn_B_Rq 1;
BA_ "U_CD542_MY2021_Rx" SG_ 1144 BattTracDrvSustn_B_Rq 1;
BA_ "U_CX727_MY2021_Rx" SG_ 1144 BattTracDrvSustn_B_Rq 1;
BA_ "GenSigSendType" SG_ 1144 BattTracDrvSustn_B_Rq 3;
BA_ "U_CD764_MY2022_Rx" SG_ 1144 CabinDrvSustn_B_Rq 1;
BA_ "U_U55X_MY2022_Rx" SG_ 1144 CabinDrvSustn_B_Rq 1;
BA_ "U_T6_MCA_MY2020_Rx" SG_ 1144 CabinDrvSustn_B_Rq 1;
BA_ "U_P702_MY2021_Rx" SG_ 1144 CabinDrvSustn_B_Rq 1;
BA_ "U_CD542_MY2021_Rx" SG_ 1144 CabinDrvSustn_B_Rq 1;
BA_ "U_CX727_MY2021_Rx" SG_ 1144 CabinDrvSustn_B_Rq 1;
BA_ "GenSigSendType" SG_ 1144 CabinDrvSustn_B_Rq 3;
BA_ "U_U55X_MY2022_Rx" SG_ 1144 BattTracClntVlv_B_Rq 1;
BA_ "U_CD542_MY2021_Rx" SG_ 1144 BattTracClntVlv_B_Rq 1;
BA_ "U_P702_MY2021_Rx" SG_ 1144 BattTracClntVlv_B_Rq 1;
BA_ "GenSigSendType" SG_ 1144 BattTracClntVlv_B_Rq 3;
BA_ "U_CD542_MY2021_Rx" SG_ 1144 ChrgNowEvnt_B_Stat 1;
BA_ "U_CX727_MY2021_Rx" SG_ 1144 ChrgNowEvnt_B_Stat 1;
BA_ "GenSigSendType" SG_ 1144 ChrgNowEvnt_B_Stat 3;
BA_ "GenSigStartValueInteger" SG_ 127 AwdLckRgen_Tq_RqMn 4095;
BA_ "GenSigStartValue" SG_ 127 AwdLatDelta_Tq_Rq 1;
BA_ "GenSigStartValueInteger" SG_ 127 AwdLatDelta_Tq_Rq 1;
BA_ "U_U55X_MY2022_Tx" SG_ 1070 BattULo24_Te_Actl 1;
BA_ "U_T6_MCA_MY2020_Tx" SG_ 1070 BattULo24_Te_Actl 1;
BA_ "GenSigStartValue" SG_ 1070 BattULo24_Te_Actl 127;
BA_ "GenSigStartValueInteger" SG_ 1070 BattULo24_Te_Actl 127;
BA_ "U_U55X_MY2022_Tx" SG_ 1070 BattULo24State_D_Qlty 1;
BA_ "U_T6_MCA_MY2020_Tx" SG_ 1070 BattULo24State_D_Qlty 1;
BA_ "U_P702_MY2021_Tx" SG_ 1070 BattULo24State_D_Qlty 1;
BA_ "GenSigStartValue" SG_ 1070 BattULo24State_D_Qlty 1;
BA_ "GenSigStartValueInteger" SG_ 1070 BattULo24State_D_Qlty 1;
BA_ "U_U55X_MY2022_Tx" SG_ 1070 BattULo24Soc_Pc_Actl 1;
BA_ "U_T6_MCA_MY2020_Tx" SG_ 1070 BattULo24Soc_Pc_Actl 1;
BA_ "U_P702_MY2021_Tx" SG_ 1070 BattULo24Soc_Pc_Actl 1;
BA_ "U_U55X_MY2022_Tx" SG_ 1070 BattULo24_I_Actl 1;
BA_ "U_T6_MCA_MY2020_Tx" SG_ 1070 BattULo24_I_Actl 1;
BA_ "U_P702_MY2021_Tx" SG_ 1070 BattULo24_I_Actl 1;
BA_ "GenSigStartValue" SG_ 1070 BattULo24_I_Actl 8192;
BA_ "U_U55X_MY2022_Tx" SG_ 1070 BattULo24_B_Falt 1;
BA_ "U_T6_MCA_MY2020_Tx" SG_ 1070 BattULo24_B_Falt 1;
BA_ "U_P702_MY2021_Tx" SG_ 1070 BattULo24_B_Falt 1;
BA_ "U_U55X_MY2022_Tx" SG_ 1070 BattULo24_Ah_DeltaRide 1;
BA_ "U_T6_MCA_MY2020_Tx" SG_ 1070 BattULo24_Ah_DeltaRide 1;
BA_ "U_P702_MY2021_Tx" SG_ 1070 BattULo24_Ah_DeltaRide 1;
BA_ "GenSigStartValue" SG_ 1070 BattULo24_Ah_DeltaRide 12800;
BA_ "U_U55X_MY2022_Tx" SG_ 1070 BattULo24_D_Falt 1;
BA_ "U_T6_MCA_MY2020_Tx" SG_ 1070 BattULo24_D_Falt 1;
BA_ "U_CD542_MY2021_Tx" SG_ 589 BattTrac2_Pw_LimChrg 1;
BA_ "U_P702_MY2021_Tx" SG_ 589 BattTrac2_Pw_LimChrg 1;
BA_ "U_CX727_MY2021_Tx" SG_ 589 BattTrac2_Pw_LimChrg 1;
BA_ "U_CD542_MY2021_Tx" SG_ 589 BattTrac2_Pw_LimDchrg 1;
BA_ "U_P702_MY2021_Tx" SG_ 589 BattTrac2_Pw_LimDchrg 1;
BA_ "U_CX727_MY2021_Tx" SG_ 589 BattTrac2_Pw_LimDchrg 1;
BA_ "U_CD542_MY2021_Tx" SG_ 589 BattTrac2_Pw_DchrgInst 1;
BA_ "U_P702_MY2021_Tx" SG_ 589 BattTrac2_Pw_DchrgInst 1;
BA_ "U_CX727_MY2021_Tx" SG_ 589 BattTrac2_Pw_DchrgInst 1;
BA_ "U_CD542_MY2021_Tx" SG_ 589 BattTrac2_Pw_ChrgInst 1;
BA_ "U_P702_MY2021_Tx" SG_ 589 BattTrac2_Pw_ChrgInst 1;
BA_ "U_CX727_MY2021_Tx" SG_ 589 BattTrac2_Pw_ChrgInst 1;
BA_ "GenSigStartValue" SG_ 968 CurrentColor_CmdGage 8;
BA_ "GenSigStartValueInteger" SG_ 968 CurrentColor_CmdGage 8;
BA_ "GenSigStartValue" SG_ 968 BlendedColor_CmdGage 2;
BA_ "GenSigStartValueInteger" SG_ 968 BlendedColor_CmdGage 2;
BA_ "GenSigStartValue" SG_ 968 Current_Color_Cmd 8;
BA_ "GenSigStartValueInteger" SG_ 968 Current_Color_Cmd 8;
BA_ "GenSigStartValue" SG_ 968 BlendedColor_Cmd 2;
BA_ "GenSigStartValueInteger" SG_ 968 BlendedColor_Cmd 2;
BA_ "GenSigStartValue" SG_ 968 SlMde_D_Rq 2;
BA_ "GenSigStartValueInteger" SG_ 968 SlMde_D_Rq 2;
BA_ "GenSigStartValue" SG_ 968 IsaOffst_D_Rq 14;
BA_ "GenSigStartValueInteger" SG_ 968 IsaOffst_D_Rq 14;
BA_ "U_CD764_MY2022_Rx" SG_ 1081 ChirpRq_No_ActlTrlr_UB 1;
BA_ "U_U55X_MY2022_Rx" SG_ 1081 ChirpRq_No_ActlTrlr_UB 1;
BA_ "U_CD542_MY2021_Rx" SG_ 1081 ChirpRq_No_ActlTrlr_UB 1;
BA_ "U_T6_MCA_MY2020_Rx" SG_ 1081 ChirpRq_No_ActlTrlr_UB 1;
BA_ "U_P702_MY2021_Rx" SG_ 1081 ChirpRq_No_ActlTrlr_UB 1;
BA_ "U_CX727_MY2021_Rx" SG_ 1081 ChirpRq_No_ActlTrlr_UB 1;
BA_ "U_CD764_MY2022_Rx" SG_ 1081 ChirpRq_No_ActlTrlr 1;
BA_ "U_U55X_MY2022_Rx" SG_ 1081 ChirpRq_No_ActlTrlr 1;
BA_ "U_CD542_MY2021_Rx" SG_ 1081 ChirpRq_No_ActlTrlr 1;
BA_ "U_T6_MCA_MY2020_Rx" SG_ 1081 ChirpRq_No_ActlTrlr 1;
BA_ "U_P702_MY2021_Rx" SG_ 1081 ChirpRq_No_ActlTrlr 1;
BA_ "U_CX727_MY2021_Rx" SG_ 1081 ChirpRq_No_ActlTrlr 1;
BA_ "U_CD764_MY2022_Rx" SG_ 1081 Chirp_D_RqTrlr_UB 1;
BA_ "U_U55X_MY2022_Rx" SG_ 1081 Chirp_D_RqTrlr_UB 1;
BA_ "U_CD542_MY2021_Rx" SG_ 1081 Chirp_D_RqTrlr_UB 1;
BA_ "U_T6_MCA_MY2020_Rx" SG_ 1081 Chirp_D_RqTrlr_UB 1;
BA_ "U_P702_MY2021_Rx" SG_ 1081 Chirp_D_RqTrlr_UB 1;
BA_ "U_CX727_MY2021_Rx" SG_ 1081 Chirp_D_RqTrlr_UB 1;
BA_ "U_CD764_MY2022_Rx" SG_ 1081 Chirp_D_RqTrlr 1;
BA_ "U_U55X_MY2022_Rx" SG_ 1081 Chirp_D_RqTrlr 1;
BA_ "U_CD542_MY2021_Rx" SG_ 1081 Chirp_D_RqTrlr 1;
BA_ "U_T6_MCA_MY2020_Rx" SG_ 1081 Chirp_D_RqTrlr 1;
BA_ "U_P702_MY2021_Rx" SG_ 1081 Chirp_D_RqTrlr 1;
BA_ "U_CX727_MY2021_Rx" SG_ 1081 Chirp_D_RqTrlr 1;
BA_ "GenSigSendType" SG_ 1081 Chirp_D_RqTrlr 3;
BA_ "U_CD764_MY2022_Rx" SG_ 1081 RearPassWindowPos_UB 1;
BA_ "U_U55X_MY2022_Rx" SG_ 1081 RearPassWindowPos_UB 1;
BA_ "U_CD542_MY2021_Rx" SG_ 1081 RearPassWindowPos_UB 1;
BA_ "U_T6_MCA_MY2020_Rx" SG_ 1081 RearPassWindowPos_UB 1;
BA_ "U_P702_MY2021_Rx" SG_ 1081 RearPassWindowPos_UB 1;
BA_ "U_CX727_MY2021_Rx" SG_ 1081 RearPassWindowPos_UB 1;
BA_ "U_CD764_MY2022_Rx" SG_ 1081 RearPassWindowPos 1;
BA_ "U_U55X_MY2022_Rx" SG_ 1081 RearPassWindowPos 1;
BA_ "U_CD542_MY2021_Rx" SG_ 1081 RearPassWindowPos 1;
BA_ "U_T6_MCA_MY2020_Rx" SG_ 1081 RearPassWindowPos 1;
BA_ "U_P702_MY2021_Rx" SG_ 1081 RearPassWindowPos 1;
BA_ "U_CX727_MY2021_Rx" SG_ 1081 RearPassWindowPos 1;
BA_ "GenSigSendType" SG_ 1081 RearPassWindowPos 3;
BA_ "WakeupSignal" SG_ 1081 RearPassWindowPos 1;
BA_ "U_CD764_MY2022_Rx" SG_ 1081 RearDriverWindowPos_UB 1;
BA_ "U_U55X_MY2022_Rx" SG_ 1081 RearDriverWindowPos_UB 1;
BA_ "U_CD542_MY2021_Rx" SG_ 1081 RearDriverWindowPos_UB 1;
BA_ "U_T6_MCA_MY2020_Rx" SG_ 1081 RearDriverWindowPos_UB 1;
BA_ "U_P702_MY2021_Rx" SG_ 1081 RearDriverWindowPos_UB 1;
BA_ "U_CX727_MY2021_Rx" SG_ 1081 RearDriverWindowPos_UB 1;
BA_ "U_CD764_MY2022_Rx" SG_ 1081 RearDriverWindowPos 1;
BA_ "U_U55X_MY2022_Rx" SG_ 1081 RearDriverWindowPos 1;
BA_ "U_CD542_MY2021_Rx" SG_ 1081 RearDriverWindowPos 1;
BA_ "U_T6_MCA_MY2020_Rx" SG_ 1081 RearDriverWindowPos 1;
BA_ "U_P702_MY2021_Rx" SG_ 1081 RearDriverWindowPos 1;
BA_ "U_CX727_MY2021_Rx" SG_ 1081 RearDriverWindowPos 1;
BA_ "GenSigSendType" SG_ 1081 RearDriverWindowPos 3;
BA_ "WakeupSignal" SG_ 1081 RearDriverWindowPos 1;
BA_ "U_CD764_MY2022_Rx" SG_ 1081 PassWindowPosition_UB 1;
BA_ "U_U55X_MY2022_Rx" SG_ 1081 PassWindowPosition_UB 1;
BA_ "U_CD542_MY2021_Rx" SG_ 1081 PassWindowPosition_UB 1;
BA_ "U_T6_MCA_MY2020_Rx" SG_ 1081 PassWindowPosition_UB 1;
BA_ "U_P702_MY2021_Rx" SG_ 1081 PassWindowPosition_UB 1;
BA_ "U_CX727_MY2021_Rx" SG_ 1081 PassWindowPosition_UB 1;
BA_ "U_CD764_MY2022_Rx" SG_ 1081 PassWindowPosition 1;
BA_ "U_U55X_MY2022_Rx" SG_ 1081 PassWindowPosition 1;
BA_ "U_CD542_MY2021_Rx" SG_ 1081 PassWindowPosition 1;
BA_ "U_T6_MCA_MY2020_Rx" SG_ 1081 PassWindowPosition 1;
BA_ "U_P702_MY2021_Rx" SG_ 1081 PassWindowPosition 1;
BA_ "U_CX727_MY2021_Rx" SG_ 1081 PassWindowPosition 1;
BA_ "GenSigSendType" SG_ 1081 PassWindowPosition 3;
BA_ "WakeupSignal" SG_ 1081 PassWindowPosition 1;
BA_ "U_CD764_MY2022_Rx" SG_ 1081 DriverWindowPosition_UB 1;
BA_ "U_U55X_MY2022_Rx" SG_ 1081 DriverWindowPosition_UB 1;
BA_ "U_CD542_MY2021_Rx" SG_ 1081 DriverWindowPosition_UB 1;
BA_ "U_T6_MCA_MY2020_Rx" SG_ 1081 DriverWindowPosition_UB 1;
BA_ "U_P702_MY2021_Rx" SG_ 1081 DriverWindowPosition_UB 1;
BA_ "U_CX727_MY2021_Rx" SG_ 1081 DriverWindowPosition_UB 1;
BA_ "U_CD764_MY2022_Rx" SG_ 1081 DriverWindowPosition 1;
BA_ "U_U55X_MY2022_Rx" SG_ 1081 DriverWindowPosition 1;
BA_ "U_CD542_MY2021_Rx" SG_ 1081 DriverWindowPosition 1;
BA_ "U_T6_MCA_MY2020_Rx" SG_ 1081 DriverWindowPosition 1;
BA_ "U_P702_MY2021_Rx" SG_ 1081 DriverWindowPosition 1;
BA_ "U_CX727_MY2021_Rx" SG_ 1081 DriverWindowPosition 1;
BA_ "GenSigSendType" SG_ 1081 DriverWindowPosition 3;
BA_ "WakeupSignal" SG_ 1081 DriverWindowPosition 1;
BA_ "GenSigSendType" SG_ 1081 ChrgCrdLckEnbl_B_Stat 3;
BA_ "U_CD764_MY2022_Rx" SG_ 1081 EcoInhbt_B_RqHvac_UB 1;
BA_ "U_U55X_MY2022_Rx" SG_ 1081 EcoInhbt_B_RqHvac_UB 1;
BA_ "U_CD542_MY2021_Rx" SG_ 1081 EcoInhbt_B_RqHvac_UB 1;
BA_ "U_T6_MCA_MY2020_Rx" SG_ 1081 EcoInhbt_B_RqHvac_UB 1;
BA_ "U_P702_MY2021_Rx" SG_ 1081 EcoInhbt_B_RqHvac_UB 1;
BA_ "U_CX727_MY2021_Rx" SG_ 1081 EcoInhbt_B_RqHvac_UB 1;
BA_ "U_CD764_MY2022_Rx" SG_ 1081 EmgcyAsstActv_D_Stat_UB 1;
BA_ "U_U55X_MY2022_Rx" SG_ 1081 EmgcyAsstActv_D_Stat_UB 1;
BA_ "U_CD542_MY2021_Rx" SG_ 1081 EmgcyAsstActv_D_Stat_UB 1;
BA_ "U_T6_MCA_MY2020_Rx" SG_ 1081 EmgcyAsstActv_D_Stat_UB 1;
BA_ "U_P702_MY2021_Rx" SG_ 1081 EmgcyAsstActv_D_Stat_UB 1;
BA_ "U_CX727_MY2021_Rx" SG_ 1081 EmgcyAsstActv_D_Stat_UB 1;
BA_ "U_CD764_MY2022_Rx" SG_ 1081 EmgcyAsstActv_D_Stat 1;
BA_ "U_U55X_MY2022_Rx" SG_ 1081 EmgcyAsstActv_D_Stat 1;
BA_ "U_CD542_MY2021_Rx" SG_ 1081 EmgcyAsstActv_D_Stat 1;
BA_ "U_T6_MCA_MY2020_Rx" SG_ 1081 EmgcyAsstActv_D_Stat 1;
BA_ "U_P702_MY2021_Rx" SG_ 1081 EmgcyAsstActv_D_Stat 1;
BA_ "U_CX727_MY2021_Rx" SG_ 1081 EmgcyAsstActv_D_Stat 1;
BA_ "GenSigSendType" SG_ 1081 EmgcyAsstActv_D_Stat 3;
BA_ "U_CD764_MY2022_Rx" SG_ 1081 TrlrHitchLamp_D_Rq2_UB 1;
BA_ "U_U55X_MY2022_Rx" SG_ 1081 TrlrHitchLamp_D_Rq2_UB 1;
BA_ "U_T6_MCA_MY2020_Rx" SG_ 1081 TrlrHitchLamp_D_Rq2_UB 1;
BA_ "U_P702_MY2021_Rx" SG_ 1081 TrlrHitchLamp_D_Rq2_UB 1;
BA_ "U_CX727_MY2021_Rx" SG_ 1081 TrlrHitchLamp_D_Rq2_UB 1;
BA_ "U_CD764_MY2022_Rx" SG_ 1081 TrlrHitchLamp_D_Rq2 1;
BA_ "U_U55X_MY2022_Rx" SG_ 1081 TrlrHitchLamp_D_Rq2 1;
BA_ "U_T6_MCA_MY2020_Rx" SG_ 1081 TrlrHitchLamp_D_Rq2 1;
BA_ "U_P702_MY2021_Rx" SG_ 1081 TrlrHitchLamp_D_Rq2 1;
BA_ "U_CX727_MY2021_Rx" SG_ 1081 TrlrHitchLamp_D_Rq2 1;
BA_ "GenSigSendType" SG_ 1081 TrlrHitchLamp_D_Rq2 3;
BA_ "U_CD764_MY2022_Rx" SG_ 1081 EcoInhbt_B_RqHvac 1;
BA_ "U_U55X_MY2022_Rx" SG_ 1081 EcoInhbt_B_RqHvac 1;
BA_ "U_CD542_MY2021_Rx" SG_ 1081 EcoInhbt_B_RqHvac 1;
BA_ "U_T6_MCA_MY2020_Rx" SG_ 1081 EcoInhbt_B_RqHvac 1;
BA_ "U_P702_MY2021_Rx" SG_ 1081 EcoInhbt_B_RqHvac 1;
BA_ "U_CX727_MY2021_Rx" SG_ 1081 EcoInhbt_B_RqHvac 1;
BA_ "GenSigSendType" SG_ 1081 EcoInhbt_B_RqHvac 3;
BA_ "GenSigStartValue" SG_ 1479 ICM_GWOnBoardTester 255;
BA_ "ContentDependant" SG_ 1479 ICM_GWOnBoardTester 1;
BA_ "GenSigStartValueInteger" SG_ 1479 ICM_GWOnBoardTester 255;
BA_ "GenSigStartValue" SG_ 1479 ICM_GWNMProxy 255;
BA_ "ContentDependant" SG_ 1479 ICM_GWNMProxy 1;
BA_ "GenSigStartValueInteger" SG_ 1479 ICM_GWNMProxy 255;
BA_ "GenSigStartValue" SG_ 1479 ICM_AutoSarNMReserved4 255;
BA_ "ContentDependant" SG_ 1479 ICM_AutoSarNMReserved4 1;
BA_ "GenSigStartValueInteger" SG_ 1479 ICM_AutoSarNMReserved4 255;
BA_ "GenSigStartValue" SG_ 1479 ICM_AutoSarNMReserved3 255;
BA_ "ContentDependant" SG_ 1479 ICM_AutoSarNMReserved3 1;
BA_ "GenSigStartValueInteger" SG_ 1479 ICM_AutoSarNMReserved3 255;
BA_ "GenSigStartValue" SG_ 1479 ICM_AutoSarNMReserved2 255;
BA_ "ContentDependant" SG_ 1479 ICM_AutoSarNMReserved2 1;
BA_ "GenSigStartValueInteger" SG_ 1479 ICM_AutoSarNMReserved2 255;
BA_ "GenSigStartValue" SG_ 1479 ICM_AutoSarNMReserved1 255;
BA_ "ContentDependant" SG_ 1479 ICM_AutoSarNMReserved1 1;
BA_ "GenSigStartValueInteger" SG_ 1479 ICM_AutoSarNMReserved1 255;
BA_ "GenSigStartValue" SG_ 1479 ICM_AutoSarNMNodeId 199;
BA_ "ContentDependant" SG_ 1479 ICM_AutoSarNMNodeId 1;
BA_ "GenSigStartValueInteger" SG_ 1479 ICM_AutoSarNMNodeId 199;
BA_ "ContentDependant" SG_ 1479 ICM_AutoSarNMControl 1;
BA_ "GenSigSendType" SG_ 1932 TesterPhysicalResICM 3;
BA_ "GenSigSendType" SG_ 1924 TesterPhysicalReqICM 3;
BA_ "GenSigStartValue" SG_ 829 DcdcUHi3_I_Actl 2046;
BA_ "U_CD764_MY2022_Tx" SG_ 910 CloudVehCtlData_Tp_Rq 1;
BA_ "U_U55X_MY2022_Tx" SG_ 910 CloudVehCtlData_Tp_Rq 1;
BA_ "U_CD542_MY2021_Tx" SG_ 910 CloudVehCtlData_Tp_Rq 1;
BA_ "ECGUsedTxSignal" SG_ 910 CloudVehCtlData_Tp_Rq 1;
BA_ "U_T6_MCA_MY2020_Tx" SG_ 910 CloudVehCtlData_Tp_Rq 1;
BA_ "U_CD764_MY2022_Rx" SG_ 910 CloudVehCtlData_Tp_Rq 1;
BA_ "U_U55X_MY2022_Rx" SG_ 910 CloudVehCtlData_Tp_Rq 1;
BA_ "U_CD542_MY2021_Rx" SG_ 910 CloudVehCtlData_Tp_Rq 1;
BA_ "U_T6_MCA_MY2020_Rx" SG_ 910 CloudVehCtlData_Tp_Rq 1;
BA_ "GenSigSendType" SG_ 910 CloudVehCtlData_Tp_Rq 3;
BA_ "U_CD764_MY2022_Tx" SG_ 911 CloudVehCtlData_Tp_Res 1;
BA_ "U_U55X_MY2022_Tx" SG_ 911 CloudVehCtlData_Tp_Res 1;
BA_ "U_CD542_MY2021_Tx" SG_ 911 CloudVehCtlData_Tp_Res 1;
BA_ "U_T6_MCA_MY2020_Tx" SG_ 911 CloudVehCtlData_Tp_Res 1;
BA_ "U_CD764_MY2022_Rx" SG_ 911 CloudVehCtlData_Tp_Res 1;
BA_ "U_U55X_MY2022_Rx" SG_ 911 CloudVehCtlData_Tp_Res 1;
BA_ "U_CD542_MY2021_Rx" SG_ 911 CloudVehCtlData_Tp_Res 1;
BA_ "ECGUsedRxSignal" SG_ 911 CloudVehCtlData_Tp_Res 1;
BA_ "U_T6_MCA_MY2020_Rx" SG_ 911 CloudVehCtlData_Tp_Res 1;
BA_ "GenSigSendType" SG_ 911 CloudVehCtlData_Tp_Res 3;
BA_ "U_U55X_MY2022_Tx" SG_ 2609984728 OTAPhysGWM_ECGtoOBCC 1;
BA_ "ECGUsedTxSignal" SG_ 2609984728 OTAPhysGWM_ECGtoOBCC 1;
BA_ "GenSigSendType" SG_ 2609984728 OTAPhysGWM_ECGtoOBCC 3;
BA_ "U_U55X_MY2022_Rx" SG_ 2610126925 OTAPhysOBCCtoGWM_ECG 1;
BA_ "U_CD542_MY2021_Rx" SG_ 2610126925 OTAPhysOBCCtoGWM_ECG 1;
BA_ "ECGUsedRxSignal" SG_ 2610126925 OTAPhysOBCCtoGWM_ECG 1;
BA_ "GenSigSendType" SG_ 2610126925 OTAPhysOBCCtoGWM_ECG 3;
BA_ "GenSigSendType" SG_ 1789 TesterPhysicalResOBCC 3;
BA_ "GenSigSendType" SG_ 1781 TesterPhysicalReqOBCC 3;
BA_ "U_CD764_MY2022_Tx" SG_ 2612224082 PARSEDPushBCMtoGWM_ECG 1;
BA_ "U_CD542_MY2021_Tx" SG_ 2612224082 PARSEDPushBCMtoGWM_ECG 1;
BA_ "U_T6_MCA_MY2020_Tx" SG_ 2612224082 PARSEDPushBCMtoGWM_ECG 1;
BA_ "U_U55X_MY2022_Rx" SG_ 2612224082 PARSEDPushBCMtoGWM_ECG 1;
BA_ "U_CD542_MY2021_Rx" SG_ 2612224082 PARSEDPushBCMtoGWM_ECG 1;
BA_ "ECGUsedRxSignal" SG_ 2612224082 PARSEDPushBCMtoGWM_ECG 1;
BA_ "U_T6_MCA_MY2020_Rx" SG_ 2612224082 PARSEDPushBCMtoGWM_ECG 1;
BA_ "GenSigSendType" SG_ 2612224082 PARSEDPushBCMtoGWM_ECG 3;
BA_ "U_CD764_MY2022_Tx" SG_ 2611175506 PARSEDPhysBCMtoGWM_ECG 1;
BA_ "U_CD542_MY2021_Tx" SG_ 2611175506 PARSEDPhysBCMtoGWM_ECG 1;
BA_ "U_T6_MCA_MY2020_Tx" SG_ 2611175506 PARSEDPhysBCMtoGWM_ECG 1;
BA_ "U_CD764_MY2022_Rx" SG_ 2611175506 PARSEDPhysBCMtoGWM_ECG 1;
BA_ "U_U55X_MY2022_Rx" SG_ 2611175506 PARSEDPhysBCMtoGWM_ECG 1;
BA_ "U_CD542_MY2021_Rx" SG_ 2611175506 PARSEDPhysBCMtoGWM_ECG 1;
BA_ "ECGUsedRxSignal" SG_ 2611175506 PARSEDPhysBCMtoGWM_ECG 1;
BA_ "U_T6_MCA_MY2020_Rx" SG_ 2611175506 PARSEDPhysBCMtoGWM_ECG 1;
BA_ "GenSigSendType" SG_ 2611175506 PARSEDPhysBCMtoGWM_ECG 3;
BA_ "U_CD764_MY2022_Tx" SG_ 2611038424 PARSEDPhysGWM_ECGtoBCM 1;
BA_ "U_CD542_MY2021_Tx" SG_ 2611038424 PARSEDPhysGWM_ECGtoBCM 1;
BA_ "ECGUsedTxSignal" SG_ 2611038424 PARSEDPhysGWM_ECGtoBCM 1;
BA_ "U_T6_MCA_MY2020_Tx" SG_ 2611038424 PARSEDPhysGWM_ECGtoBCM 1;
BA_ "U_CD764_MY2022_Rx" SG_ 2611038424 PARSEDPhysGWM_ECGtoBCM 1;
BA_ "U_CD542_MY2021_Rx" SG_ 2611038424 PARSEDPhysGWM_ECGtoBCM 1;
BA_ "U_T6_MCA_MY2020_Rx" SG_ 2611038424 PARSEDPhysGWM_ECGtoBCM 1;
BA_ "GenSigSendType" SG_ 2611038424 PARSEDPhysGWM_ECGtoBCM 3;
BA_ "U_CD764_MY2022_Tx" SG_ 2609989848 OTAPhysGWM_ECGtoBCM 1;
BA_ "U_CD542_MY2021_Tx" SG_ 2609989848 OTAPhysGWM_ECGtoBCM 1;
BA_ "ECGUsedTxSignal" SG_ 2609989848 OTAPhysGWM_ECGtoBCM 1;
BA_ "U_T6_MCA_MY2020_Tx" SG_ 2609989848 OTAPhysGWM_ECGtoBCM 1;
BA_ "U_CD764_MY2022_Rx" SG_ 2609989848 OTAPhysGWM_ECGtoBCM 1;
BA_ "U_U55X_MY2022_Rx" SG_ 2609989848 OTAPhysGWM_ECGtoBCM 1;
BA_ "U_CD542_MY2021_Rx" SG_ 2609989848 OTAPhysGWM_ECGtoBCM 1;
BA_ "U_T6_MCA_MY2020_Rx" SG_ 2609989848 OTAPhysGWM_ECGtoBCM 1;
BA_ "GenSigSendType" SG_ 2609989848 OTAPhysGWM_ECGtoBCM 3;
BA_ "U_CD764_MY2022_Tx" SG_ 2610126930 OTAPhysBCMtoGWM_ECG 1;
BA_ "U_U55X_MY2022_Tx" SG_ 2610126930 OTAPhysBCMtoGWM_ECG 1;
BA_ "U_CD542_MY2021_Tx" SG_ 2610126930 OTAPhysBCMtoGWM_ECG 1;
BA_ "U_T6_MCA_MY2020_Tx" SG_ 2610126930 OTAPhysBCMtoGWM_ECG 1;
BA_ "U_CD764_MY2022_Rx" SG_ 2610126930 OTAPhysBCMtoGWM_ECG 1;
BA_ "U_U55X_MY2022_Rx" SG_ 2610126930 OTAPhysBCMtoGWM_ECG 1;
BA_ "U_CD542_MY2021_Rx" SG_ 2610126930 OTAPhysBCMtoGWM_ECG 1;
BA_ "ECGUsedRxSignal" SG_ 2610126930 OTAPhysBCMtoGWM_ECG 1;
BA_ "U_T6_MCA_MY2020_Rx" SG_ 2610126930 OTAPhysBCMtoGWM_ECG 1;
BA_ "GenSigSendType" SG_ 2610126930 OTAPhysBCMtoGWM_ECG 3;
BA_ "U_CD764_MY2022_Tx" SG_ 2610126914 OTAPhysBCMCtoGWM_ECG 1;
BA_ "U_U55X_MY2022_Tx" SG_ 2610126914 OTAPhysBCMCtoGWM_ECG 1;
BA_ "U_P702_MY2021_Tx" SG_ 2610126914 OTAPhysBCMCtoGWM_ECG 1;
BA_ "U_CD764_MY2022_Rx" SG_ 2610126914 OTAPhysBCMCtoGWM_ECG 1;
BA_ "U_U55X_MY2022_Rx" SG_ 2610126914 OTAPhysBCMCtoGWM_ECG 1;
BA_ "U_CD542_MY2021_Rx" SG_ 2610126914 OTAPhysBCMCtoGWM_ECG 1;
BA_ "ECGUsedRxSignal" SG_ 2610126914 OTAPhysBCMCtoGWM_ECG 1;
BA_ "GenSigSendType" SG_ 2610126914 OTAPhysBCMCtoGWM_ECG 3;
BA_ "U_CD764_MY2022_Tx" SG_ 2609973464 OTAPhysGWM_ECGtoBCMC 1;
BA_ "U_U55X_MY2022_Tx" SG_ 2609973464 OTAPhysGWM_ECGtoBCMC 1;
BA_ "U_CD542_MY2021_Tx" SG_ 2609973464 OTAPhysGWM_ECGtoBCMC 1;
BA_ "ECGUsedTxSignal" SG_ 2609973464 OTAPhysGWM_ECGtoBCMC 1;
BA_ "U_CD764_MY2022_Rx" SG_ 2609973464 OTAPhysGWM_ECGtoBCMC 1;
BA_ "U_U55X_MY2022_Rx" SG_ 2609973464 OTAPhysGWM_ECGtoBCMC 1;
BA_ "U_P702_MY2021_Rx" SG_ 2609973464 OTAPhysGWM_ECGtoBCMC 1;
BA_ "GenSigSendType" SG_ 2609973464 OTAPhysGWM_ECGtoBCMC 3;
BA_ "U_U55X_MY2022_Rx" SG_ 2612224062 PARSEDPushPACMtoGWM_ECG 1;
BA_ "U_CD542_MY2021_Rx" SG_ 2612224062 PARSEDPushPACMtoGWM_ECG 1;
BA_ "ECGUsedRxSignal" SG_ 2612224062 PARSEDPushPACMtoGWM_ECG 1;
BA_ "GenSigSendType" SG_ 2612224062 PARSEDPushPACMtoGWM_ECG 3;
BA_ "U_U55X_MY2022_Rx" SG_ 2611175486 PARSEDPhysPACMtoGWM_ECG 1;
BA_ "U_CD542_MY2021_Rx" SG_ 2611175486 PARSEDPhysPACMtoGWM_ECG 1;
BA_ "ECGUsedRxSignal" SG_ 2611175486 PARSEDPhysPACMtoGWM_ECG 1;
BA_ "GenSigSendType" SG_ 2611175486 PARSEDPhysPACMtoGWM_ECG 3;
BA_ "U_CD542_MY2021_Tx" SG_ 2611017944 PARSEDPhysGWM_ECGtoPACM 1;
BA_ "ECGUsedTxSignal" SG_ 2611017944 PARSEDPhysGWM_ECGtoPACM 1;
BA_ "U_CD542_MY2021_Rx" SG_ 2611017944 PARSEDPhysGWM_ECGtoPACM 1;
BA_ "GenSigSendType" SG_ 2611017944 PARSEDPhysGWM_ECGtoPACM 3;
BA_ "U_CD764_MY2022_Tx" SG_ 2612002008 PARSEDFuncGWM_ECG 1;
BA_ "U_U55X_MY2022_Tx" SG_ 2612002008 PARSEDFuncGWM_ECG 1;
BA_ "U_CD542_MY2021_Tx" SG_ 2612002008 PARSEDFuncGWM_ECG 1;
BA_ "ECGUsedTxSignal" SG_ 2612002008 PARSEDFuncGWM_ECG 1;
BA_ "U_T6_MCA_MY2020_Tx" SG_ 2612002008 PARSEDFuncGWM_ECG 1;
BA_ "U_U55X_MY2022_Rx" SG_ 2612002008 PARSEDFuncGWM_ECG 1;
BA_ "U_P702_MY2021_Rx" SG_ 2612002008 PARSEDFuncGWM_ECG 1;
BA_ "U_CD764_MY2022_Rx" SG_ 2612002008 PARSEDFuncGWM_ECG 1;
BA_ "U_CD542_MY2021_Rx" SG_ 2612002008 PARSEDFuncGWM_ECG 1;
BA_ "U_T6_MCA_MY2020_Rx" SG_ 2612002008 PARSEDFuncGWM_ECG 1;
BA_ "GenSigSendType" SG_ 2612002008 PARSEDFuncGWM_ECG 3;
BA_ "U_CD764_MY2022_Tx" SG_ 2610953432 OTAFuncGWM_ECG 1;
BA_ "U_U55X_MY2022_Tx" SG_ 2610953432 OTAFuncGWM_ECG 1;
BA_ "U_CD542_MY2021_Tx" SG_ 2610953432 OTAFuncGWM_ECG 1;
BA_ "ECGUsedTxSignal" SG_ 2610953432 OTAFuncGWM_ECG 1;
BA_ "U_T6_MCA_MY2020_Tx" SG_ 2610953432 OTAFuncGWM_ECG 1;
BA_ "U_CD542_MY2021_Rx" SG_ 2610953432 OTAFuncGWM_ECG 1;
BA_ "U_T6_MCA_MY2020_Rx" SG_ 2610953432 OTAFuncGWM_ECG 1;
BA_ "U_CD764_MY2022_Rx" SG_ 2610953432 OTAFuncGWM_ECG 1;
BA_ "U_U55X_MY2022_Rx" SG_ 2610953432 OTAFuncGWM_ECG 1;
BA_ "U_P702_MY2021_Rx" SG_ 2610953432 OTAFuncGWM_ECG 1;
BA_ "GenSigSendType" SG_ 2610953432 OTAFuncGWM_ECG 3;
BA_ "U_CD764_MY2022_Tx" SG_ 2611022040 PARSEDPhysGWM_ECGtoBCMC 1;
BA_ "U_U55X_MY2022_Tx" SG_ 2611022040 PARSEDPhysGWM_ECGtoBCMC 1;
BA_ "U_CD542_MY2021_Tx" SG_ 2611022040 PARSEDPhysGWM_ECGtoBCMC 1;
BA_ "ECGUsedTxSignal" SG_ 2611022040 PARSEDPhysGWM_ECGtoBCMC 1;
BA_ "U_CD764_MY2022_Rx" SG_ 2611022040 PARSEDPhysGWM_ECGtoBCMC 1;
BA_ "U_U55X_MY2022_Rx" SG_ 2611022040 PARSEDPhysGWM_ECGtoBCMC 1;
BA_ "U_CD542_MY2021_Rx" SG_ 2611022040 PARSEDPhysGWM_ECGtoBCMC 1;
BA_ "U_T6_MCA_MY2020_Rx" SG_ 2611022040 PARSEDPhysGWM_ECGtoBCMC 1;
BA_ "U_P702_MY2021_Rx" SG_ 2611022040 PARSEDPhysGWM_ECGtoBCMC 1;
BA_ "GenSigSendType" SG_ 2611022040 PARSEDPhysGWM_ECGtoBCMC 3;
BA_ "U_CD764_MY2022_Tx" SG_ 2612224066 PARSEDPushBCMCtoGWM_ECG 1;
BA_ "U_U55X_MY2022_Tx" SG_ 2612224066 PARSEDPushBCMCtoGWM_ECG 1;
BA_ "U_CD542_MY2021_Tx" SG_ 2612224066 PARSEDPushBCMCtoGWM_ECG 1;
BA_ "U_T6_MCA_MY2020_Tx" SG_ 2612224066 PARSEDPushBCMCtoGWM_ECG 1;
BA_ "U_P702_MY2021_Tx" SG_ 2612224066 PARSEDPushBCMCtoGWM_ECG 1;
BA_ "U_CD764_MY2022_Rx" SG_ 2612224066 PARSEDPushBCMCtoGWM_ECG 1;
BA_ "U_U55X_MY2022_Rx" SG_ 2612224066 PARSEDPushBCMCtoGWM_ECG 1;
BA_ "U_CD542_MY2021_Rx" SG_ 2612224066 PARSEDPushBCMCtoGWM_ECG 1;
BA_ "ECGUsedRxSignal" SG_ 2612224066 PARSEDPushBCMCtoGWM_ECG 1;
BA_ "GenSigSendType" SG_ 2612224066 PARSEDPushBCMCtoGWM_ECG 3;
BA_ "U_CD542_MY2021_Tx" SG_ 2609969368 OTAPhysGWM_ECGtoPACM 1;
BA_ "ECGUsedTxSignal" SG_ 2609969368 OTAPhysGWM_ECGtoPACM 1;
BA_ "GenSigSendType" SG_ 2609969368 OTAPhysGWM_ECGtoPACM 3;
BA_ "U_U55X_MY2022_Rx" SG_ 2610126910 OTAPhysPACMtoGWM_ECG 1;
BA_ "U_CD542_MY2021_Rx" SG_ 2610126910 OTAPhysPACMtoGWM_ECG 1;
BA_ "ECGUsedRxSignal" SG_ 2610126910 OTAPhysPACMtoGWM_ECG 1;
BA_ "GenSigSendType" SG_ 2610126910 OTAPhysPACMtoGWM_ECG 3;
BA_ "U_CD764_MY2022_Tx" SG_ 2611175490 PARSEDPhysBCMCtoGWM_ECG 1;
BA_ "U_U55X_MY2022_Tx" SG_ 2611175490 PARSEDPhysBCMCtoGWM_ECG 1;
BA_ "U_CD542_MY2021_Tx" SG_ 2611175490 PARSEDPhysBCMCtoGWM_ECG 1;
BA_ "U_T6_MCA_MY2020_Tx" SG_ 2611175490 PARSEDPhysBCMCtoGWM_ECG 1;
BA_ "U_P702_MY2021_Tx" SG_ 2611175490 PARSEDPhysBCMCtoGWM_ECG 1;
BA_ "U_CD764_MY2022_Rx" SG_ 2611175490 PARSEDPhysBCMCtoGWM_ECG 1;
BA_ "U_U55X_MY2022_Rx" SG_ 2611175490 PARSEDPhysBCMCtoGWM_ECG 1;
BA_ "U_CD542_MY2021_Rx" SG_ 2611175490 PARSEDPhysBCMCtoGWM_ECG 1;
BA_ "ECGUsedRxSignal" SG_ 2611175490 PARSEDPhysBCMCtoGWM_ECG 1;
BA_ "GenSigSendType" SG_ 2611175490 PARSEDPhysBCMCtoGWM_ECG 3;
BA_ "U_U55X_MY2022_Rx" SG_ 811 ExtLghtRight_D_RqMnu 1;
BA_ "U_T6_MCA_MY2020_Rx" SG_ 811 ExtLghtRight_D_RqMnu 1;
BA_ "WakeupSignal" SG_ 811 ExtLghtRight_D_RqMnu 1;
BA_ "U_U55X_MY2022_Rx" SG_ 811 ExtLghtRear_D_RqMnu 1;
BA_ "U_T6_MCA_MY2020_Rx" SG_ 811 ExtLghtRear_D_RqMnu 1;
BA_ "WakeupSignal" SG_ 811 ExtLghtRear_D_RqMnu 1;
BA_ "U_U55X_MY2022_Rx" SG_ 811 ExtLghtLeft_D_RqMnu 1;
BA_ "U_T6_MCA_MY2020_Rx" SG_ 811 ExtLghtLeft_D_RqMnu 1;
BA_ "WakeupSignal" SG_ 811 ExtLghtLeft_D_RqMnu 1;
BA_ "U_U55X_MY2022_Rx" SG_ 811 ExtLghtFront_D_RqMnu 1;
BA_ "U_T6_MCA_MY2020_Rx" SG_ 811 ExtLghtFront_D_RqMnu 1;
BA_ "WakeupSignal" SG_ 811 ExtLghtFront_D_RqMnu 1;
BA_ "GenSigStartValue" SG_ 811 ScMnSoc_Pc_RqMnu 126;
BA_ "GenSigStartValue" SG_ 811 GoTEditMnte_T_RqMnu 14;
BA_ "GenSigStartValue" SG_ 811 GoTEditHr_T_RqMnu 30;
BA_ "GenSigStartValue" SG_ 811 DistToStopover_L_Actl 65535;
BA_ "U_U55X_MY2022_Rx" SG_ 811 AutoLghtOvrrd_B_RqDrv 1;
BA_ "U_T6_MCA_MY2020_Rx" SG_ 811 AutoLghtOvrrd_B_RqDrv 1;
BA_ "WakeupSignal" SG_ 811 AutoLghtOvrrd_B_RqDrv 1;
BA_ "U_CD764_MY2022_Rx" SG_ 811 BecRleas_No_RqMnu 1;
BA_ "U_CD542_MY2021_Rx" SG_ 811 BecRleas_No_RqMnu 1;
BA_ "WakeupSignal" SG_ 811 BecRleas_No_RqMnu 1;
BA_ "U_CD542_MY2021_Rx" SG_ 811 TrnkFrontRleas_No_RqMnu 1;
BA_ "WakeupSignal" SG_ 811 TrnkFrontRleas_No_RqMnu 1;
BA_ "U_CD764_MY2022_Tx" SG_ 810 VehHorn_B_RqOccAlrt 1;
BA_ "ECGUsedTxSignal" SG_ 810 VehHorn_B_RqOccAlrt 1;
BA_ "GenSigSendType" SG_ 810 VehHorn_B_RqOccAlrt 3;
BA_ "WakeupSignal" SG_ 810 VehHorn_B_RqOccAlrt 1;
BA_ "U_CD764_MY2022_Tx" SG_ 810 DteCldAcceptData_B_Rq 1;
BA_ "U_CD542_MY2021_Tx" SG_ 810 DteCldAcceptData_B_Rq 1;
BA_ "ECGUsedTxSignal" SG_ 810 DteCldAcceptData_B_Rq 1;
BA_ "GenSigSendType" SG_ 810 DteCldAcceptData_B_Rq 3;
BA_ "U_CD764_MY2022_Tx" SG_ 810 RmtViewMde_B_Rq 1;
BA_ "U_CD542_MY2021_Tx" SG_ 810 RmtViewMde_B_Rq 1;
BA_ "ECGUsedTxSignal" SG_ 810 RmtViewMde_B_Rq 1;
BA_ "U_CD764_MY2022_Rx" SG_ 810 RmtViewMde_B_Rq 1;
BA_ "GenSigSendType" SG_ 810 RmtViewMde_B_Rq 3;
BA_ "U_CD764_MY2022_Tx" SG_ 810 ExtLghtDsply_B_StatArb 1;
BA_ "U_U55X_MY2022_Tx" SG_ 810 ExtLghtDsply_B_StatArb 1;
BA_ "U_CD542_MY2021_Tx" SG_ 810 ExtLghtDsply_B_StatArb 1;
BA_ "ECGUsedTxSignal" SG_ 810 ExtLghtDsply_B_StatArb 1;
BA_ "U_T6_MCA_MY2020_Tx" SG_ 810 ExtLghtDsply_B_StatArb 1;
BA_ "U_U55X_MY2022_Rx" SG_ 810 ExtLghtDsply_B_StatArb 1;
BA_ "U_T6_MCA_MY2020_Rx" SG_ 810 ExtLghtDsply_B_StatArb 1;
BA_ "GenSigSendType" SG_ 810 ExtLghtDsply_B_StatArb 3;
BA_ "WakeupSignal" SG_ 810 ExtLghtDsply_B_StatArb 1;
BA_ "U_CD764_MY2022_Tx" SG_ 810 ExtLghtRight_D_RqOta 1;
BA_ "U_U55X_MY2022_Tx" SG_ 810 ExtLghtRight_D_RqOta 1;
BA_ "U_CD542_MY2021_Tx" SG_ 810 ExtLghtRight_D_RqOta 1;
BA_ "ECGUsedTxSignal" SG_ 810 ExtLghtRight_D_RqOta 1;
BA_ "U_T6_MCA_MY2020_Tx" SG_ 810 ExtLghtRight_D_RqOta 1;
BA_ "U_U55X_MY2022_Rx" SG_ 810 ExtLghtRight_D_RqOta 1;
BA_ "U_T6_MCA_MY2020_Rx" SG_ 810 ExtLghtRight_D_RqOta 1;
BA_ "GenSigSendType" SG_ 810 ExtLghtRight_D_RqOta 3;
BA_ "WakeupSignal" SG_ 810 ExtLghtRight_D_RqOta 1;
BA_ "U_CD764_MY2022_Tx" SG_ 810 ExtLghtRear_D_RqOta 1;
BA_ "U_U55X_MY2022_Tx" SG_ 810 ExtLghtRear_D_RqOta 1;
BA_ "U_CD542_MY2021_Tx" SG_ 810 ExtLghtRear_D_RqOta 1;
BA_ "ECGUsedTxSignal" SG_ 810 ExtLghtRear_D_RqOta 1;
BA_ "U_T6_MCA_MY2020_Tx" SG_ 810 ExtLghtRear_D_RqOta 1;
BA_ "U_U55X_MY2022_Rx" SG_ 810 ExtLghtRear_D_RqOta 1;
BA_ "U_T6_MCA_MY2020_Rx" SG_ 810 ExtLghtRear_D_RqOta 1;
BA_ "GenSigSendType" SG_ 810 ExtLghtRear_D_RqOta 3;
BA_ "WakeupSignal" SG_ 810 ExtLghtRear_D_RqOta 1;
BA_ "U_CD764_MY2022_Tx" SG_ 810 DteCldCnclRoute_B_Rq 1;
BA_ "U_U55X_MY2022_Tx" SG_ 810 DteCldCnclRoute_B_Rq 1;
BA_ "U_CD542_MY2021_Tx" SG_ 810 DteCldCnclRoute_B_Rq 1;
BA_ "ECGUsedTxSignal" SG_ 810 DteCldCnclRoute_B_Rq 1;
BA_ "GenSigSendType" SG_ 810 DteCldCnclRoute_B_Rq 3;
BA_ "U_CD764_MY2022_Tx" SG_ 810 PtRmtRprt_D_Stat 1;
BA_ "U_U55X_MY2022_Tx" SG_ 810 PtRmtRprt_D_Stat 1;
BA_ "U_CD542_MY2021_Tx" SG_ 810 PtRmtRprt_D_Stat 1;
BA_ "ECGUsedTxSignal" SG_ 810 PtRmtRprt_D_Stat 1;
BA_ "GenSigSendType" SG_ 810 PtRmtRprt_D_Stat 3;
BA_ "WakeupSignal" SG_ 810 PtRmtRprt_D_Stat 1;
BA_ "U_CD764_MY2022_Tx" SG_ 810 NtfyDrvTrgtDist_L_Rq 1;
BA_ "U_U55X_MY2022_Tx" SG_ 810 NtfyDrvTrgtDist_L_Rq 1;
BA_ "U_CD542_MY2021_Tx" SG_ 810 NtfyDrvTrgtDist_L_Rq 1;
BA_ "ECGUsedTxSignal" SG_ 810 NtfyDrvTrgtDist_L_Rq 1;
BA_ "GenSigSendType" SG_ 810 NtfyDrvTrgtDist_L_Rq 3;
BA_ "GenSigStartValue" SG_ 810 NtfyDrvTrgtDist_L_Rq 4095;
BA_ "GenSigStartValueInteger" SG_ 810 NtfyDrvTrgtDist_L_Rq 1;
BA_ "WakeupSignal" SG_ 810 NtfyDrvTrgtDist_L_Rq 1;
BA_ "U_CD764_MY2022_Tx" SG_ 810 NtfyDrvSocLvl1_Pc_Rq 1;
BA_ "U_U55X_MY2022_Tx" SG_ 810 NtfyDrvSocLvl1_Pc_Rq 1;
BA_ "U_CD542_MY2021_Tx" SG_ 810 NtfyDrvSocLvl1_Pc_Rq 1;
BA_ "ECGUsedTxSignal" SG_ 810 NtfyDrvSocLvl1_Pc_Rq 1;
BA_ "GenSigSendType" SG_ 810 NtfyDrvSocLvl1_Pc_Rq 3;
BA_ "GenSigStartValue" SG_ 810 NtfyDrvSocLvl1_Pc_Rq 127;
BA_ "GenSigStartValueInteger" SG_ 810 NtfyDrvSocLvl1_Pc_Rq 1;
BA_ "WakeupSignal" SG_ 810 NtfyDrvSocLvl1_Pc_Rq 1;
BA_ "U_CD764_MY2022_Tx" SG_ 810 ChrgrPncEnbl_D_Rq 1;
BA_ "U_U55X_MY2022_Tx" SG_ 810 ChrgrPncEnbl_D_Rq 1;
BA_ "U_CD542_MY2021_Tx" SG_ 810 ChrgrPncEnbl_D_Rq 1;
BA_ "ECGUsedTxSignal" SG_ 810 ChrgrPncEnbl_D_Rq 1;
BA_ "GenSigSendType" SG_ 810 ChrgrPncEnbl_D_Rq 3;
BA_ "GenSigStartValue" SG_ 810 ChrgrPncEnbl_D_Rq 3;
BA_ "GenSigStartValueInteger" SG_ 810 ChrgrPncEnbl_D_Rq 3;
BA_ "U_CD764_MY2022_Tx" SG_ 810 OBCCSerial_D_Rq 1;
BA_ "U_U55X_MY2022_Tx" SG_ 810 OBCCSerial_D_Rq 1;
BA_ "U_CD542_MY2021_Tx" SG_ 810 OBCCSerial_D_Rq 1;
BA_ "ECGUsedTxSignal" SG_ 810 OBCCSerial_D_Rq 1;
BA_ "GenSigSendType" SG_ 810 OBCCSerial_D_Rq 3;
BA_ "U_CD764_MY2022_Tx" SG_ 810 ExtLghtLeft_D_RqOta 1;
BA_ "U_U55X_MY2022_Tx" SG_ 810 ExtLghtLeft_D_RqOta 1;
BA_ "U_CD542_MY2021_Tx" SG_ 810 ExtLghtLeft_D_RqOta 1;
BA_ "ECGUsedTxSignal" SG_ 810 ExtLghtLeft_D_RqOta 1;
BA_ "U_T6_MCA_MY2020_Tx" SG_ 810 ExtLghtLeft_D_RqOta 1;
BA_ "U_U55X_MY2022_Rx" SG_ 810 ExtLghtLeft_D_RqOta 1;
BA_ "U_T6_MCA_MY2020_Rx" SG_ 810 ExtLghtLeft_D_RqOta 1;
BA_ "GenSigSendType" SG_ 810 ExtLghtLeft_D_RqOta 3;
BA_ "WakeupSignal" SG_ 810 ExtLghtLeft_D_RqOta 1;
BA_ "U_CD764_MY2022_Tx" SG_ 810 ExtLghtFront_D_RqOta 1;
BA_ "U_U55X_MY2022_Tx" SG_ 810 ExtLghtFront_D_RqOta 1;
BA_ "U_CD542_MY2021_Tx" SG_ 810 ExtLghtFront_D_RqOta 1;
BA_ "ECGUsedTxSignal" SG_ 810 ExtLghtFront_D_RqOta 1;
BA_ "U_T6_MCA_MY2020_Tx" SG_ 810 ExtLghtFront_D_RqOta 1;
BA_ "U_U55X_MY2022_Rx" SG_ 810 ExtLghtFront_D_RqOta 1;
BA_ "U_T6_MCA_MY2020_Rx" SG_ 810 ExtLghtFront_D_RqOta 1;
BA_ "GenSigSendType" SG_ 810 ExtLghtFront_D_RqOta 3;
BA_ "WakeupSignal" SG_ 810 ExtLghtFront_D_RqOta 1;
BA_ "U_CD764_MY2022_Tx" SG_ 810 TlghtTest_D_RqArb 1;
BA_ "U_U55X_MY2022_Tx" SG_ 810 TlghtTest_D_RqArb 1;
BA_ "U_CD542_MY2021_Tx" SG_ 810 TlghtTest_D_RqArb 1;
BA_ "ECGUsedTxSignal" SG_ 810 TlghtTest_D_RqArb 1;
BA_ "U_T6_MCA_MY2020_Tx" SG_ 810 TlghtTest_D_RqArb 1;
BA_ "U_U55X_MY2022_Rx" SG_ 810 TlghtTest_D_RqArb 1;
BA_ "U_T6_MCA_MY2020_Rx" SG_ 810 TlghtTest_D_RqArb 1;
BA_ "GenSigSendType" SG_ 810 TlghtTest_D_RqArb 3;
BA_ "U_CD764_MY2022_Tx" SG_ 810 ChrgrPncSustn_B_Rq 1;
BA_ "U_U55X_MY2022_Tx" SG_ 810 ChrgrPncSustn_B_Rq 1;
BA_ "U_CD542_MY2021_Tx" SG_ 810 ChrgrPncSustn_B_Rq 1;
BA_ "ECGUsedTxSignal" SG_ 810 ChrgrPncSustn_B_Rq 1;
BA_ "GenSigSendType" SG_ 810 ChrgrPncSustn_B_Rq 3;
BA_ "GenSigStartValueInteger" SG_ 810 ChrgrPncSustn_B_Rq 3;
BA_ "U_U55X_MY2022_Rx" SG_ 519 RearDiffLck_Tq_Rq 1;
BA_ "GenSigStartValue" SG_ 519 RearDiffLck_Tq_Rq 16382;
BA_ "GenSigStartValueInteger" SG_ 519 RearDiffLck_Tq_Rq 16382;
BA_ "U_CX727_MY2021_Tx" SG_ 751 ChrgrAcIn_I_Mn 1;
BA_ "U_CX727_MY2021_Tx" SG_ 751 ChrgrAcIn_I_Mx 1;
BA_ "U_CX727_MY2021_Tx" SG_ 751 ChrgrAcIn_U_Mx 1;
BA_ "GenSigSendType" SG_ 2029 TesterPhysicalResAFCM 3;
BA_ "U_CD764_MY2022_Tx" SG_ 303 CanMsg12F_No_Crc 1;
BA_ "MetaData" SG_ 303 CanMsg12F_No_Crc 1;
BA_ "ContentDependant" SG_ 303 CanMsg12F_No_Crc 1;
BA_ "U_CD764_MY2022_Tx" SG_ 303 CanMsg12F_No_Cnt 1;
BA_ "MetaData" SG_ 303 CanMsg12F_No_Cnt 1;
BA_ "ContentDependant" SG_ 303 CanMsg12F_No_Cnt 1;
BA_ "U_CD764_MY2022_Tx" SG_ 303 DrStatHood_D2_Actl 1;
BA_ "WakeupSignal" SG_ 303 DrStatHood_D2_Actl 1;
BA_ "ECGUsedRxSignal" SG_ 2612224034 PARSEDPushSOBDMBtoGWM_ECG 1;
BA_ "GenSigSendType" SG_ 2612224034 PARSEDPushSOBDMBtoGWM_ECG 3;
BA_ "ECGUsedTxSignal" SG_ 2612037848 PARSEDPushFcGWMECGtoSOBDMB 1;
BA_ "GenSigSendType" SG_ 2612037848 PARSEDPushFcGWMECGtoSOBDMB 3;
BA_ "ECGUsedRxSignal" SG_ 2611175458 PARSEDPhysSOBDMBtoGWM_ECG 1;
BA_ "GenSigSendType" SG_ 2611175458 PARSEDPhysSOBDMBtoGWM_ECG 3;
BA_ "ECGUsedTxSignal" SG_ 2610989272 PARSEDPhysGWM_ECGtoSOBDMB 1;
BA_ "GenSigSendType" SG_ 2610989272 PARSEDPhysGWM_ECGtoSOBDMB 3;
BA_ "ECGUsedRxSignal" SG_ 2610126882 OTAPhysSOBDMBtoGWM_ECG 1;
BA_ "GenSigSendType" SG_ 2610126882 OTAPhysSOBDMBtoGWM_ECG 3;
BA_ "ECGUsedTxSignal" SG_ 2609940696 OTAPhysGWM_ECGtoSOBDMB 1;
BA_ "GenSigSendType" SG_ 2609940696 OTAPhysGWM_ECGtoSOBDMB 3;
VAL_ 943 InhbtGlblClkAdj_B_Rq 1 "Request" 0 "NoRequest" ;
VAL_ 932 RmtCtlBattMntr_B_Falt 1 "Yes" 0 "No" ;
VAL_ 932 VehInhbtMde_D_Stat 7 "NotUsed_3" 6 "NotUsed_2" 5 "NotUsed_1" 4 "FullVehicleOta" 3 "Iviota" 2 "SyncOta" 1 "NoOtaSupport" 0 "Unconfigured" ;
VAL_ 932 VehStrtInhbt_D_Stat 1 "Inhibit" 0 "NoInhibit" ;
VAL_ 932 VehOnCtl_D_Stat 3 "NotUsed" 2 "On" 1 "Off" 0 "Null" ;
VAL_ 932 VehOnSrc2_D_Stat 15 "NotUsed_11" 14 "NotUsed_10" 13 "NotUsed_9" 12 "NotUsed_8" 11 "NotUsed_7" 10 "NotUsed_6" 9 "EsclRssd" 8 "AutonomousVehicle" 7 "SecureIdle" 6 "FleetVehicleInhibit" 5 "StolenVehicleInhibit" 4 "OverTheAir" 3 "RemoteParkAssist" 2 "RemoteStart" 1 "Manual" 0 "Off" ;
VAL_ 885 BattULoChrg_D_RqOta 1 "Yes" 0 "No" ;
VAL_ 885 VehStrtInhbt_D_Dsply 15 "NotUsed_12" 14 "NotUsed_11" 13 "NotUsed_10" 12 "NotUsed_9" 11 "NotUsed_8" 10 "NotUsed_7" 9 "NotUsed_6" 8 "NotUsed_5" 7 "NotUsed_4" 6 "FleetPhoneNumber" 5 "FleetGeneral" 4 "OtaSuccess" 3 "PostOtaActivatePermFail" 2 "PostOtaActivateWarning" 1 "DuringOtaActivate" 0 "NoMessage" ;
VAL_ 885 VehOnRqstr_D_Stat 11 "NotUsed_8" 10 "NotUsed_7" 9 "NotUsed_6" 8 "NotUsed_5" 7 "NotUsed_4" 6 "NotUsed_3" 5 "NotUsed_2" 4 "NotUsed_1" 3 "FleetVehInhbt" 2 "StolenVehInhbt" 1 "OverTheAir" 0 "NoRequestor" 15 "NotUsed_12" 14 "NotUsed_11" 13 "NotUsed_10" 12 "NotUsed_9" ;
VAL_ 885 VehStrtInhbt_D_RqCld 3 "NotUsed" 2 "On" 1 "Off" 0 "Null" ;
VAL_ 885 VehOn_D_RqCld 3 "NoControl" 2 "On" 1 "Off" 0 "Null" ;
VAL_ 885 OtaActv_D_Stat 15 "NotUsed_10" 14 "NotUsed_9" 13 "NotUsed_8" 12 "NotUsed_7" 11 "NotUsed_6" 10 "NotUsed_5" 9 "NotUsed_4" 8 "NotUsed_3" 7 "NotUsed_2" 6 "NotUsed_1" 5 "NonInterruptible_Pending" 4 "NonInterruptible_Config" 3 "NonInterruptible_ER" 2 "NonInterruptible_AB" 1 "Interruptible_AB" 0 "NoInVehicleOta" ;
VAL_ 1160 ReFuelSwtchStat_D_Actl2 3 "NotUsed_2" 2 "NotUsed_1" 1 "On" 0 "Off" ;
VAL_ 1160 DgtlCommPncReset_B_Req 1 "Yes" 0 "No" ;
VAL_ 1160 DgtlCommPnc_D_Rq 3 "DeleteAll" 2 "Disable" 1 "Reset" 0 "NoRequest" ;
VAL_ 1160 PwSustnRdata_B_RqTelem 1 "Active" 0 "Inactive" ;
VAL_ 1160 DataMntrSustn_B_Rq 1 "Active" 0 "Inactive" ;
VAL_ 895 TurnLght_D_RqRmtCtl 3 "NotUsed" 2 "Right" 1 "Left" 0 "Null" ;
VAL_ 895 RmtCtlRngSet_D_Rq 3 "NotUsed" 2 "RangeSetB" 1 "RangeSetA" 0 "None" ;
VAL_ 895 RmtCtlKeyPoll_D_Rq 3 "NotUsed" 2 "Polling" 1 "NoPolling" 0 "Null" ;
VAL_ 895 RmtCtlCntnsIn_B_Stat 1 "Available" 0 "NotAvailable" ;
VAL_ 895 RmtCtl_D_Stat 15 "Faulty" 14 "NotUsed_5" 13 "NotUsed_4" 12 "NotUsed_3" 11 "NotUsed_2" 10 "NotUsed_1" 9 "Shutdown" 8 "ManeuverFinished" 7 "ReadyForResume" 6 "Pause" 5 "Maneuvering" 4 "ReadyForManeuvering" 3 "Activation" 2 "Initialize" 1 "Preparation" 0 "Disabled" ;
VAL_ 1134 UpftrDgtlIn12_D_Stat 3 "NotUsed" 2 "OutOfRange" 1 "On" 0 "Off" ;
VAL_ 1134 UpftrDgtlIn11_D_Stat 3 "NotUsed" 2 "OutOfRange" 1 "On" 0 "Off" ;
VAL_ 1134 UpftrDgtlIn10_D_Stat 3 "NotUsed" 2 "OutOfRange" 1 "On" 0 "Off" ;
VAL_ 894 RmtCtlTrgt_D_Rq 3 "NotUsed" 2 "Null" 1 "RemoteParkAssist" 0 "ManeuverId" ;
VAL_ 894 RmtCtlRngSet_D_Stat 3 "NotUsed" 2 "RangeSetB" 1 "RangeSetA" 0 "None" ;
VAL_ 894 RmtCtlKeySrch_D_Stat 3 "NotUsed" 2 "Valid" 1 "Invalid" 0 "Null" ;
VAL_ 894 RmtCtlBody_D_Stat 15 "NotUsed_6" 14 "NotUsed_5" 13 "NotUsed_4" 12 "NotUsed_3" 11 "NotUsed_2" 10 "NotUsed_1" 9 "Shutdown" 8 "ManeuverFinished" 7 "ReadyForResume" 6 "Pause" 5 "Maneuvering" 4 "ReadyForManeuvering" 3 "Activation" 2 "Initialize" 1 "Preparation" 0 "Disabled" ;
VAL_ 894 RmtCtl_D_RqBody 7 "NotUsed_2" 6 "NotUsed_1" 5 "Error" 4 "Abort" 3 "PauseKeypad" 2 "PauseHazard" 1 "PauseDoorHandle" 0 "Null" ;
VAL_ 515 PtIgnSwtch_D_Stat 3 "Faulty" 2 "No_Data_Exists" 1 "On" 0 "Off" ;
VAL_ 1119 PwrSrcULo_Te_Actl 1023 "Faulty" 1022 "NoDataExists" ;
VAL_ 1119 PtLatchActv_B_RqDcdc 1 "On" 0 "Off" ;
VAL_ 1119 CoolFanDcdc_D_Rq 3 "High" 2 "Medium" 1 "Low" 0 "Off" ;
VAL_ 1119 DcdcClntFlw_D_Rq 3 "High" 2 "Medium" 1 "Low" 0 "Off" ;
VAL_ 1110 RstrnMdulePw_D_Falt 3 "NotUsed_1" 2 "NoFault" 1 "Fault" 0 "Null" ;
VAL_ 1036 PdstrnAlrt_B_Falt 1 "Yes" 0 "No" ;
VAL_ 1152 OnePdlDrvLamp_B_Rq 1 "On" 0 "Off" ;
VAL_ 1152 OnePdlDrv_D_Dsply 3 "Faulty" 2 "Suspended" 1 "On" 0 "Off" ;
VAL_ 1152 HybPwULoLamp_B_Rq 1 "On" 0 "Off" ;
VAL_ 1152 GrdAsstActv_B_Stat 1 "On" 0 "Off" ;
VAL_ 1152 StopStrtVThres_D_Stat 3 "High" 2 "Medium" 1 "Low" 0 "NoSelection" ;
VAL_ 1152 VehElEff_No_Avg 127 "Faulty" 126 "NoDataExists" ;
VAL_ 1152 EngTeHi_B_Actl 1 "EngineTempHigh" 0 "Normal" ;
VAL_ 1152 DcdcOn_B_Rq 1 "On" 0 "Off" ;
VAL_ 1152 BattTracDiagClr_B_Stat 1 "On" 0 "Off" ;
VAL_ 1152 ULoBattSpprtSustn_B_Rq 1 "Active" 0 "Inactive" ;
VAL_ 518 LsdCluPlate_Te_Est 511 "Faulty" ;
VAL_ 518 RearDiffLck_Tq_Actl2 16383 "Faulty" 16382 "NoDataExists" ;
VAL_ 1092 BattChrgOvrCurnt_B_Falt 1 "Yes" 0 "No" ;
VAL_ 1092 BattTracCell_U_Mx 16383 "Faulty" ;
VAL_ 1092 BattTracMnCell_Te_Actl 255 "Faulty" 254 "NoDataExists" ;
VAL_ 1092 BattTracInsAlrm_B_Stat 1 "Active" 0 "Inactive" ;
VAL_ 1092 BattTracUMx_B_Stat 1 "Active" 0 "Inactive" ;
VAL_ 1092 BattTracTeMx_B_Stat 1 "Exceeded" 0 "NotExceeded" ;
VAL_ 1092 BattTracMxCell_Te_Actl 255 "Faulty" 254 "NoDataExists" ;
VAL_ 1092 BattTracEq_B_Actl 1 "Active" 0 "Inactive" ;
VAL_ 1092 BattTracCell_U_Mn 16383 "Faulty" ;
VAL_ 1092 BattTracUMn_B_Stat 1 "Active" 0 "Inactive" ;
VAL_ 1092 BattTracUAlrm_B_Stat 1 "Active" 0 "Inactive" ;
VAL_ 1092 BattTracTeMn_B_Stat 1 "Exceeded" 0 "NotExceeded" ;
VAL_ 1092 BattTracInsltn_R_Actl 255 "Faulty" ;
VAL_ 1075 AwdLck_Tq_Rq_UB 1 "Fresh_data" 0 "Unchanged_data" ;
VAL_ 1075 AwdLck_Tq_Rq 4095 "Fault" 4094 "Unknown" ;
VAL_ 1075 RearDiffLck_Tq_RqMn_UB 1 "Fresh_data" 0 "Unchanged_data" ;
VAL_ 1075 RearDiffLck_Tq_RqMn 4095 "Faulty" ;
VAL_ 126 StePw_B_Rq 1 "Yes" 0 "No" ;
VAL_ 126 StePinRelInit_An_Sns 65535 "Faulty" 65534 "NoDataExists" ;
VAL_ 126 StePinCompAnEst_D_Qf 3 "OK" 2 "Degraded" 1 "No_Data_Exists" 0 "Faulty" ;
VAL_ 118 BrkTerrMdeChng_D_Rdy 7 "Fault" 6 "Undefined_2" 5 "Undefined_1" 4 "ModeUnavailDrInputRqd" 3 "SpOpModes_NotSupported" 2 "ModeUnavailDynamicCond" 1 "Module_In_Initialization" 0 "Mode_Change_Available" ;
VAL_ 118 BrkTerrMde_D_Actl 7 "Fail_Safe_Default" 6 "Dynamic_Mode" 5 "Rock_Crawl_Mode" 4 "Mud_Ruts_Mode" 3 "Sand_Mode" 2 "Undefined" 1 "Low_Mu_Mode" 0 "Special_Operating_Mode_Off" ;
VAL_ 118 BrkCtrFnd_B_Stat 1 "Yes" 0 "No" ;
VAL_ 118 ApaBrkErr_D_Stat 3 "Faulty" 2 "NoDataExists" 1 "Yes" 0 "No" ;
VAL_ 118 SteWhlCompAnEst_D_Qf 3 "OK" 2 "Not_Within_Specifications" 1 "No_Data_Exists" 0 "Faulty" ;
VAL_ 118 DrvSte_D_Stat 15 "NotUsed10" 14 "NotUsed9" 13 "NotUsed8" 12 "NotUsed7" 11 "NotUsed6" 10 "NotUsed5" 9 "NotUsed4" 8 "NotUsed3" 7 "NotUsed2" 6 "NotUsed1" 5 "Request_Active" 4 "Ignition_Off" 3 "DSR_in_Normal_Idle_Mode" 2 "EPAS_Comm_Disturbed" 1 "DSR_Request_Not_Applicable" 0 "DSR_Deactivated" ;
VAL_ 118 DrvSte_Tq_Rq 255 "Invalid" 254 "Unknown" ;
VAL_ 118 EmgcyBrkLamp_D_Rq 3 "NotUsed" 2 "Active_at_standstill" 1 "Active_at_speed" 0 "Inactive" ;
VAL_ 118 StopLamp_B_RqBrk 1 "Active" 0 "Inactive" ;
VAL_ 1079 DrLatchRr_B_Falt 1 "Yes" 0 "No" ;
VAL_ 1079 DrLatchRl_B_Falt 1 "Yes" 0 "No" ;
VAL_ 1079 DrLatchLckRr_B_Stat 1 "Locked" 0 "Unlock" ;
VAL_ 1079 DrLatchLckRl_B_Stat 1 "Locked" 0 "Unlock" ;
VAL_ 1079 DrLatchLckFr_B_Stat 1 "Locked" 0 "Unlock" ;
VAL_ 1079 DrLatchLckFl_B_Stat 1 "Locked" 0 "Unlock" ;
VAL_ 1079 DrLatchFr_B_Falt 1 "Yes" 0 "No" ;
VAL_ 1079 DrLatchFl_B_Falt 1 "Yes" 0 "No" ;
VAL_ 1079 ChildLckFdbckRr_B_Stat 1 "Locked" 0 "Unlock" ;
VAL_ 1079 ChildLckFdbckRl_B_Stat 1 "Locked" 0 "Unlock" ;
VAL_ 954 ExtLghtFront_D_RqBody 3 "NotUsed" 2 "On" 1 "Off" 0 "Null" ;
VAL_ 954 VehWlcmFrwlMde_D_Stat 7 "IlluminatedExit" 6 "CourtesyLightingDelayExt" 5 "CourtesyLightingExtended" 4 "CourtesyLightingDelayAll" 3 "CourtesyLightingAll" 2 "IlluminatedEntry" 1 "Approach" 0 "Null" ;
VAL_ 954 CrtsyLghtRear_D_Stat 3 "NotUsed" 2 "Automatic" 1 "Manual" 0 "Null" ;
VAL_ 954 PosLghtFl_D_Stat 3 "Faulty" 2 "Outage" 1 "On" 0 "Off" ;
VAL_ 954 PosLghtFr_D_Stat 3 "Faulty" 2 "Outage" 1 "On" 0 "Off" ;
VAL_ 954 CargoLght_D_Stat 3 "NotUsed" 2 "Automatic" 1 "Manual" 0 "Null" ;
VAL_ 954 TlghtTestLght_D_Stat 7 "Error" 6 "AllOff" 5 "TestingReverseLights" 4 "TestingBrakeLights" 3 "TestingLeftTurnSignal" 2 "TestingRightTurnSignal" 1 "ParkingLightsIlluminated" 0 "Null" ;
VAL_ 954 LghtAmbDrvMde_B_Stat 1 "Automatic" 0 "Manual" ;
VAL_ 954 KeylessIdl_B_Stat 1 "Pressed" 0 "Not_Pressed" ;
VAL_ 954 PwRnngBoardPoll_D_Stat 3 "NotUsed" 2 "PkPresent" 1 "PkNotPresent" 0 "NotPolling" ;
VAL_ 954 PudSptLghtRight_D_Rq 3 "NotUsed" 2 "On" 1 "Off" 0 "Null" ;
VAL_ 954 PudSptLghtLeft_D_Rq 3 "NotUsed" 2 "On" 1 "Off" 0 "Null" ;
VAL_ 954 ExtLghtRight_D_Stat 3 "NotUsed" 2 "On" 1 "Off" 0 "Null" ;
VAL_ 954 PoliceDmngLvl_D_Stat 7 "NotUsed" 6 "Off_Night" 5 "Off_Day" 4 "Low1Night" 3 "Low1Day" 2 "Inactive" 1 "Decommissioned" 0 "Null" ;
VAL_ 954 TrlrHitchLamp_D_Stat 1 "On" 0 "Off" ;
VAL_ 954 LicPlateLght_B_Stat 1 "On" 0 "Off" ;
VAL_ 954 TrukBedLght_B_Stat 1 "On" 0 "Off" ;
VAL_ 954 VehWlcmFrwl_D_Stat 3 "RunStart" 2 "Farewell" 1 "Welcome" 0 "Null" ;
VAL_ 954 TlghtTestPrecnd_D_Stat 7 "Error" 6 "NotStationary" 5 "InteractionPresent" 4 "PreconditionsPassed" 3 "BattSocLessThan75Percent" 2 "TailLightsOn" 1 "IgnitionNotOn" 0 "Null" ;
VAL_ 954 TlghtTest_D_Stat 3 "InProgress" 2 "Ended" 1 "Completed" 0 "Null" ;
VAL_ 954 ExtLghtRear_D_Stat 3 "NotUsed" 2 "On" 1 "Off" 0 "Null" ;
VAL_ 954 ExtLghtLeft_D_Stat 3 "NotUsed" 2 "On" 1 "Off" 0 "Null" ;
VAL_ 954 ExtLghtAlrt_B_Rq 1 "Yes" 0 "No" ;
VAL_ 954 ExtLght_D_Falt 3 "Error" 2 "NoStationary" 1 "StartEngine" 0 "Null" ;
VAL_ 954 ExtLghtFront_D_Stat 3 "NotUsed" 2 "On" 1 "Off" 0 "Null" ;
VAL_ 1118 AcChrgRdy_B_Stat 1 "True" 0 "False" ;
VAL_ 1118 DgtlCommGtwyMde_D_Rq 15 "NotUsed_10" 14 "NotUsed_9" 13 "NotUsed_8" 12 "NotUsed_7" 11 "NotUsed_6" 10 "NotUsed_5" 9 "NotUsed_4" 8 "NotUsed_3" 7 "NotUsed_2" 6 "NotUsed_1" 5 "AcPnC" 4 "AcEIM" 3 "DcPnC" 2 "DcEIM" 1 "AttemptDgtlComm" 0 "NoDgtlComm" ;
VAL_ 1118 ExtChrgNowButtn_B_Rq 1 "Request" 0 "NoRequest" ;
VAL_ 1118 CoolFanChrgr_D_Rq 3 "High" 2 "Medium" 1 "Low" 0 "Off" ;
VAL_ 1118 ChrgrDcOvrVolt_B_Falt 1 "Yes" 0 "No" ;
VAL_ 1118 ChrgrDcOvrCurnt_B_Falt 1 "Yes" 0 "No" ;
VAL_ 1118 ChrgrPncEnbl_D_Stat 3 "NotUsed" 2 "Enable" 1 "Disable" 0 "Null" ;
VAL_ 1118 ChrgrClntFlw_D_Rq 3 "High" 2 "Medium" 1 "Low" 0 "Off" ;
VAL_ 1118 PlgStatEvnt_B_Stat 1 "Active" 0 "Inactive" ;
VAL_ 1118 ChrgrCnnctPwr_B_Stat 1 "Asserted" 0 "NotAsserted" ;
VAL_ 1118 ChrgrAvailEvnt_B_Stat 1 "Active" 0 "Inactive" ;
VAL_ 1118 ChrgrSrvcRqd_B_Rq 1 "On" 0 "Off" ;
VAL_ 1118 ChrgrS2Swtch_B_Stat 1 "Close" 0 "Open" ;
VAL_ 1118 ChrgChngEvnt_B_Stat 1 "Active" 0 "Inactive" ;
VAL_ 1118 ChrgrCc2Cnnct_B_Falt 1 "Yes" 0 "No" ;
VAL_ 1118 ChrgPortDcTeMx_B_Falt 1 "Yes" 0 "No" ;
VAL_ 1118 ChrgCordLck_D_Stat 7 "Faulty" 6 "LockFail" 5 "UnlockFail" 4 "LockInProgress" 3 "UnlockInProgress" 2 "Lock" 1 "Unlock" 0 "Retain" ;
VAL_ 1118 ChrgrInPwMde_D_Actl 15 "NotUsed_9" 14 "NotUsed_8" 13 "NotUsed_7" 12 "NotUsed_6" 11 "NotUsed_5" 10 "NotUsed_4" 9 "DigitalCommEnd" 8 "EvseFault" 7 "EvseNotCompatible" 6 "IcCharging" 5 "DcCharging" 4 "AcDigital" 3 "AcBasic" 2 "DigitalCommDetected" 1 "EvsePaused" 0 "EvseNotDetected" ;
VAL_ 1118 ChrgPortDrOpen_B_Stat 1 "True" 0 "False" ;
VAL_ 1118 ChrgCrdLck_D_Falt 3 "NotUsed" 2 "HardwareFault" 1 "CsiFault" 0 "NoFault" ;
VAL_ 953 PaakMyKeySearch_D_Stat 7 "PhoneErased" 6 "LockButtonTimeOut" 5 "PressLockButton" 4 "ConfirmHmi" 3 "MyKeyPaakFound" 2 "StandardPaakFound" 1 "NoValidPaakFound" 0 "Null" ;
VAL_ 953 BattULoChrgHyb_D_Stat 7 "NotUsed_4" 6 "NotUsed_3" 5 "NotUsed_2" 4 "NotUsed_1" 3 "VehicleServiceRequired" 2 "EvRangeLossDueToLoadActive" 1 "BatteryServiceRequired" 0 "Null" ;
VAL_ 953 BattULoChrgHyb_B_Rq 1 "True" 0 "False" ;
VAL_ 953 ChrgCordLck_B_Stat 1 "Unlock" 0 "Null" ;
VAL_ 953 WakeAlarm3_D_Stat 3 "PublisherReset" 2 "Wake" 1 "AlarmRunning" 0 "AlarmOff" ;
VAL_ 953 WakeAlarm2_D_Stat 3 "PublisherReset" 2 "Wake" 1 "AlarmRunning" 0 "AlarmOff" ;
VAL_ 953 WakeAlarm1_D_Stat 3 "PublisherReset" 2 "Wake" 1 "AlarmRunning" 0 "AlarmOff" ;
VAL_ 953 WakeAlarm0_D_Stat 3 "PublisherReset" 2 "Wake" 1 "AlarmRunning" 0 "AlarmOff" ;
VAL_ 953 BattRgenLoChrg_D_Rq 3 "DoNotCare" 2 "Retain" 1 "Closed" 0 "Open" ;
VAL_ 953 BattRgenLoDChrg_D_Rq 3 "DoNotCare" 2 "Retain" 1 "Closed" 0 "Open" ;
VAL_ 1112 BattTracIsoDis_B_Stat 1 "Yes" 0 "No" ;
VAL_ 1112 BattTrac2_E_Max 4095 "Faulty" 4094 "NoDataExists" ;
VAL_ 1112 BattTracHeat_D_Rq 3 "Faulty" 2 "NotUsed" 1 "On" 0 "Off" ;
VAL_ 1112 BattTracDcFstSustn_B_Rq 1 "Active" 0 "Inactive" ;
VAL_ 1112 BattDcCnnct_D_Cmd 7 "NotUsed_3" 6 "NotUsed_2" 5 "NotUsed_1" 4 "WeldCheck" 3 "OkToDischarge" 2 "Closed" 1 "Precharge" 0 "Open" ;
VAL_ 1112 BattTrac2_E_Avail 4095 "Faulty" 4094 "NoDataExists" ;
VAL_ 1112 BattTracCnnct_D_Cmd 7 "NotUsed_3" 6 "NotUsed_2" 5 "NotUsed_1" 4 "WeldCheck" 3 "OkToDischarge" 2 "Closed" 1 "Precharge" 0 "Open" ;
VAL_ 1112 BattTracHvilOpen_B_Stat 1 "Open" 0 "Closed" ;
VAL_ 1112 BattTracCoolLvl_D_Rq 7 "Faulty" 6 "NotUsed" 5 "ChillerCoolingBattFirst" 4 "ChillerCoolingCabinFirst" 3 "ForcedCoolingRadiator" 2 "OpportunisticCoolingRad" 1 "CoolantFlowBypassLine" 0 "Off" ;
VAL_ 1112 BattTracTeSustn_B_Rq 1 "Active" 0 "Inactive" ;
VAL_ 1112 BattTracTeEvnt_B_Stat 1 "Active" 0 "Inactive" ;
VAL_ 1112 BattTracDcdcDis_B_Rq 1 "Yes" 0 "No" ;
VAL_ 1112 BattChrgTrgtEvnt_B_Stat 1 "Active" 0 "Inactive" ;
VAL_ 1112 BattTracDiagClr_B_Rq 1 "On" 0 "Off" ;
VAL_ 1112 BattTracHazrd_D_Stat 3 "Disabled" 2 "HazardConfirmed" 1 "ExternalMonitoringRequired" 0 "NoHazardDetected" ;
VAL_ 1112 BattTracChrgSustn_B_Rq 1 "Active" 0 "Inactive" ;
VAL_ 1112 HtrnClntPump_D_Stat 3 "Faulty" 2 "No_Data_Exists" 1 "On" 0 "Off" ;
VAL_ 1112 BattTracDelta_Te_Actl 255 "Faulty" 254 "NoDataExists" ;
VAL_ 1112 BattTracClntPmp_D_Stat 3 "Faulty" 2 "No_Data_Exists" 1 "On" 0 "Off" ;
VAL_ 1116 Rstrt_D_RqUpftr 3 "NotUsed" 2 "RemoteCancel" 1 "RemoteStart" 0 "NoRequest" ;
VAL_ 1116 Panic_D_RqUpftr 3 "NotUsed" 2 "On" 1 "Off" 0 "Null" ;
VAL_ 1116 Lock_D_RqUpftr 7 "NotUsed3" 6 "NotUsed2" 5 "NotUsed1" 4 "TrunkRelPopGlassLgCargo" 3 "LockAllDoorsandTailgate" 2 "UnlockDriversDoor" 1 "UnlockAllDoorsandTailgate" 0 "NoRequest" ;
VAL_ 1116 Chirp_D_RqUpftr 7 "NotUsed3" 6 "NotUsed2" 5 "NotUsed1" 4 "Honk" 3 "ChirpHonk" 2 "Chirp2" 1 "Chirp1" 0 "NoRequest" ;
VAL_ 1144 BattChrgTrgtSoC_D_Rq 7 "Percent_50" 6 "Percent_60" 5 "Percent_70" 4 "Percent_80" 3 "Percent_85" 2 "Percent_90" 1 "Percent_95" 0 "Percent_100" ;
VAL_ 1144 PreCondBatt_B_Actl 1 "On" 0 "Off" ;
VAL_ 1144 CabnEvapSovFront_B_Rq 1 "On" 0 "Off" ;
VAL_ 1144 HeatCoreSovRear_B_Rq 1 "On" 0 "Off" ;
VAL_ 1144 BattChlrSov_B_Rq 1 "On" 0 "Off" ;
VAL_ 1144 CabnEvapSovRear_B_Rq 1 "On" 0 "Off" ;
VAL_ 1144 BrkAppl_D_RqPt 3 "BrakesSlowRelease" 2 "BrakesFastRelease" 1 "BrakesEngage" 0 "NotActive" ;
VAL_ 1144 BattClntVlvOvrrd_D_Rq 3 "NotUsed" 2 "OverrideTbcvToChiller" 1 "OverrideTbcvToRadiator" 0 "NoOverrideToTbcvCLogic" ;
VAL_ 1144 BattTracChillerOn_B_Rq 1 "On" 0 "Off" ;
VAL_ 1144 BattTracChiller_D_Stat 3 "NotUsed" 2 "ChillerNotAvailable" 1 "ChillerBrieflyAvailable" 0 "ChillerAvailable" ;
VAL_ 1144 ULoBattTrnsfrSustn_B_Rq 1 "Active" 0 "Inactive" ;
VAL_ 1144 ULoBattTransfer_D_Stat 7 "NotUsed_2" 6 "NotUsed_1" 5 "TransferError" 4 "TransferComplete" 3 "TransferThroughGridEnergy" 2 "InsufficientEnergyToXfer" 1 "TransferInProgress" 0 "NoTransfer" ;
VAL_ 1144 HtrnDcdcDis_B_Rq 1 "Yes" 0 "No" ;
VAL_ 1144 HtrnCnnctPwr_B_Stat 1 "Asserted" 0 "NotAsserted" ;
VAL_ 1144 PtcHtr_D_Stat 3 "Faulty" 2 "NotUsed" 1 "On" 0 "Off" ;
VAL_ 1144 BattChrgInhbt_D2_Rq 7 "NotUsed_4" 6 "NotUsed_3" 5 "NotUsed_2" 4 "NotUsed_1" 3 "MaintainTargetSoc" 2 "EndAtTarget" 1 "InhibitCharging" 0 "Enable_Charging" ;
VAL_ 1144 WakeAlarm0_B_Typ 1 "CanAndEcuDriveCircuit" 0 "CanOnly" ;
VAL_ 1144 BattTracClimtDis_B_Stat 1 "Enable" 0 "Disable" ;
VAL_ 1144 HtrnClntFlw_D_Rq 3 "High" 2 "Medium" 1 "Low" 0 "Off" ;
VAL_ 1144 BattTracDrvSustn_B_Rq 1 "Active" 0 "Inactive" ;
VAL_ 1144 CabinDrvSustn_B_Rq 1 "Active" 0 "Inactive" ;
VAL_ 1144 BattTracClntVlv_B_Rq 1 "On" 0 "Off" ;
VAL_ 1144 ChrgNowEvnt_B_Stat 1 "Active" 0 "Inactive" ;
VAL_ 127 AwdLatDelta_B_Rq 1 "Active" 0 "Inactive" ;
VAL_ 1070 BattULo24_Te_Actl 127 "Fault" ;
VAL_ 1070 BattULo24State_D_Qlty 3 "OK" 2 "Not_Within_Spec" 1 "Eval_In_Progress" 0 "Faulty" ;
VAL_ 1070 BattULo24_I_Actl 16383 "Faulty" ;
VAL_ 1070 BattULo24_B_Falt 1 "Yes" 0 "No" ;
VAL_ 1070 BattULo24_D_Falt 3 "NotUsed" 2 "TemporaryFault" 1 "Fault" 0 "NoFault" ;
VAL_ 589 DcdcUHi2_I_Actl 2047 "Faulty" ;
VAL_ 968 LnchCtl_D_Rq 3 "NotUsed2" 2 "NotUsed1" 1 "LC_On" 0 "LC_Off" ;
VAL_ 968 CurrentColor_CmdGage 15 "NotUsed7" 14 "NotUsed6" 13 "NotUsed5" 12 "NotUsed4" 11 "NotUsed3" 10 "NotUsed2" 9 "NotUsed1" 8 "Null" 7 "Color7" 6 "Color6" 5 "Color5" 4 "Color4" 3 "Color3" 2 "Color2" 1 "Color1" 0 "Off" ;
VAL_ 968 BlendedColor_CmdGage 3 "NotUsed" 2 "Null" 1 "On" 0 "Off" ;
VAL_ 968 BlendColorRed_CmdGage 15 "NotUsed10" 14 "NotUsed9" 13 "NotUsed8" 12 "NotUsed7" 11 "NotUsed6" 10 "NotUsed5" 9 "NotUsed4" 8 "NotUsed3" 7 "NotUsed2" 6 "NotUsed1" 5 "_5" 4 "_4" 3 "_3" 2 "_2" 1 "_1" 0 "Null" ;
VAL_ 968 BlendColorGrn_CmdGage 15 "NotUsed10" 14 "NotUsed9" 13 "NotUsed8" 12 "NotUsed7" 11 "NotUsed6" 10 "NotUsed5" 9 "NotUsed4" 8 "NotUsed3" 7 "NotUsed2" 6 "NotUsed1" 5 "_5" 4 "_4" 3 "_3" 2 "_2" 1 "_1" 0 "Null" ;
VAL_ 968 BlendColorBlue_CmdGage 15 "NotUsed10" 14 "NotUsed9" 13 "NotUsed8" 12 "NotUsed7" 11 "NotUsed6" 10 "NotUsed5" 9 "NotUsed4" 8 "NotUsed3" 7 "NotUsed2" 6 "NotUsed1" 5 "_5" 4 "_4" 3 "_3" 2 "_2" 1 "_1" 0 "Null" ;
VAL_ 968 BrkDrvMde_D_Rq 7 "Faulty" 6 "RockCrawl" 5 "Baja" 4 "DragOrMudAndSand" 3 "Track" 2 "Snow_Wet" 1 "Sport" 0 "Normal" ;
VAL_ 968 Dimming_Level_Cmd 3 "Low" 2 "Not_Used" 1 "High" 0 "Null" ;
VAL_ 968 Current_Color_Cmd 15 "NotUsed7" 14 "NotUsed6" 13 "NotUsed5" 12 "NotUsed4" 11 "NotUsed3" 10 "NotUsed2" 9 "NotUsed1" 8 "Null" 7 "Color7" 6 "Color6" 5 "Color5" 4 "Color4" 3 "Color3" 2 "Color2" 1 "Color1" 0 "Off" ;
VAL_ 968 BlendedColorRed_Cmd 15 "NotUsed10" 14 "NotUsed9" 13 "NotUsed8" 12 "NotUsed7" 11 "NotUsed6" 10 "NotUsed5" 9 "NotUsed4" 8 "NotUsed3" 7 "NotUsed2" 6 "NotUsed1" 5 "_5" 4 "_4" 3 "_3" 2 "_2" 1 "_1" 0 "Null" ;
VAL_ 968 BlendedColorGreen_Cmd 15 "NotUsed10" 14 "NotUsed9" 13 "NotUsed8" 12 "NotUsed7" 11 "NotUsed6" 10 "NotUsed5" 9 "NotUsed4" 8 "NotUsed3" 7 "NotUsed2" 6 "NotUsed1" 5 "_5" 4 "_4" 3 "_3" 2 "_2" 1 "_1" 0 "Null" ;
VAL_ 968 BlendedColorBlue_Cmd 15 "NotUsed10" 14 "NotUsed9" 13 "NotUsed8" 12 "NotUsed7" 11 "NotUsed6" 10 "NotUsed5" 9 "NotUsed4" 8 "NotUsed3" 7 "NotUsed2" 6 "NotUsed1" 5 "_5" 4 "_4" 3 "_3" 2 "_2" 1 "_1" 0 "Null" ;
VAL_ 968 BlendedColor_Cmd 3 "NotUsed" 2 "Null" 1 "On" 0 "Off" ;
VAL_ 968 SlMde_D_Rq 3 "IsaNotConfigured" 2 "Manual_Mode" 1 "Auto_Mode" 0 "Null" ;
VAL_ 968 IsaOffst_D_Rq 15 "Faulty" 14 "Null" 13 "Thirteen" 12 "Twelve" 11 "Eleven" 10 "Ten" 9 "Nine" 8 "Eight" 7 "Seven" 6 "Six" 5 "Five" 4 "Four" 3 "Three" 2 "Two" 1 "One" 0 "Zero" ;
VAL_ 968 SuspDrvMde_D_Rq 7 "Faulty" 6 "NotUsed2" 5 "NotUsed1" 4 "Drag" 3 "Track" 2 "Snow_Wet" 1 "Sport" 0 "Normal" ;
VAL_ 1081 ChirpRq_No_ActlTrlr_UB 1 "Fresh_data" 0 "Unchanged_data" ;
VAL_ 1081 Chirp_D_RqTrlr_UB 1 "Fresh_data" 0 "Unchanged_data" ;
VAL_ 1081 Chirp_D_RqTrlr 3 "NotUsed" 2 "Chirp_2" 1 "Chirp_1" 0 "NoRequest" ;
VAL_ 1081 RearPassWindowPos_UB 1 "Fresh_data" 0 "Unchanged_data" ;
VAL_ 1081 RearPassWindowPos 7 "Unused2" 6 "Unused1" 5 "Fully_Open" 4 "Bet60Percent_FullyOpen" 3 "Bet10Percent_60Percent" 2 "BetFully_10PercentOpen" 1 "Fully_Closed" 0 "Undefined" ;
VAL_ 1081 RearDriverWindowPos_UB 1 "Fresh_data" 0 "Unchanged_data" ;
VAL_ 1081 RearDriverWindowPos 7 "Unused2" 6 "Unused1" 5 "Fully_Open" 4 "Bet60Percent_FullyOpen" 3 "Bet10Percent_60Percent" 2 "BetFully_10PercentOpen" 1 "Fully_Closed" 0 "Undefined" ;
VAL_ 1081 PassWindowPosition_UB 1 "Fresh_data" 0 "Unchanged_data" ;
VAL_ 1081 PassWindowPosition 7 "Unused2" 6 "Unused1" 5 "Fully_Open" 4 "Bet60Percent_FullyOpen" 3 "Bet10Percent_60Percent" 2 "BetFully_10PercentOpen" 1 "Fully_Closed" 0 "Undefined" ;
VAL_ 1081 DriverWindowPosition_UB 1 "Fresh_data" 0 "Unchanged_data" ;
VAL_ 1081 DriverWindowPosition 7 "Unused2" 6 "Unused1" 5 "Fully_Open" 4 "Bet60Percent_FullyOpen" 3 "Bet10Percent_60Percent" 2 "BetFully_10PercentOpen" 1 "Fully_Closed" 0 "Undefined" ;
VAL_ 1081 ChrgCrdLckEnbl_B_Stat 1 "Enable" 0 "Disable" ;
VAL_ 1081 ChrgCrdLckEnbl_B_Stat_UB 1 "Fresh_data" 0 "Unchanged_data" ;
VAL_ 1081 EcoInhbt_B_RqHvac_UB 1 "Fresh_data" 0 "Unchanged_data" ;
VAL_ 1081 EmgcyAsstActv_D_Stat_UB 1 "Fresh_data" 0 "Unchanged_data" ;
VAL_ 1081 EmgcyAsstActv_D_Stat 3 "ConfiguredOff" 2 "Active" 1 "Inactive" 0 "Null" ;
VAL_ 1081 TrlrHitchLamp_D_Rq2_UB 1 "Fresh_data" 0 "Unchanged_data" ;
VAL_ 1081 TrlrHitchLamp_D_Rq2 1 "On" 0 "Off" ;
VAL_ 1081 EcoInhbt_B_RqHvac 1 "Yes" 0 "No" ;
VAL_ 829 PwSrcULoMde2_D_Actl 3 "BuckSpecial" 2 "ReverseBoost" 1 "ForwardBuck" 0 "Standby" ;
VAL_ 829 DcdcUHi3_I_Actl 2047 "Faulty" 2046 "NoDataExists" ;
VAL_ 811 ExtLghtRight_D_RqMnu 7 "NotUsed" 6 "PressToOn3" 5 "PressToOff3" 4 "PressToOn2" 3 "PressToOff2" 2 "PressToOn1" 1 "PressToOff1" 0 "Reset" ;
VAL_ 811 ExtLghtRear_D_RqMnu 7 "NotUsed" 6 "PressToOn3" 5 "PressToOff3" 4 "PressToOn2" 3 "PressToOff2" 2 "PressToOn1" 1 "PressToOff1" 0 "Reset" ;
VAL_ 811 ExtLghtLeft_D_RqMnu 7 "NotUsed" 6 "PressToOn3" 5 "PressToOff3" 4 "PressToOn2" 3 "PressToOff2" 2 "PressToOn1" 1 "PressToOff1" 0 "Reset" ;
VAL_ 811 ExtLghtFront_D_RqMnu 7 "NotUsed" 6 "PressToOn3" 5 "PressToOff3" 4 "PressToOn2" 3 "PressToOff2" 2 "PressToOn1" 1 "PressToOff1" 0 "Reset" ;
VAL_ 811 SpeedoMajorUnit_D_Confg 3 "NotUsed" 2 "Kph" 1 "Mph" 0 "Null" ;
VAL_ 811 ScMnSoc_Pc_RqMnu 127 "Faulty" 126 "NoDataExists" ;
VAL_ 811 ScEnbl_D_RqMnu 3 "NotUsed" 2 "On" 1 "Off" 0 "Null" ;
VAL_ 811 OnePdlDrvButtn_B_Falt 1 "Faulted" 0 "NotFaulted" ;
VAL_ 811 ExtLghtDsply_D_Stat 7 "NotUsed" 6 "PressToOn3" 5 "PressToOff3" 4 "PressToOn2" 3 "PressToOff2" 2 "PressToOn1" 1 "PressToOff1" 0 "Reset" ;
VAL_ 811 OnePdlDrvButtn_B_Stat 1 "Pressed" 0 "Not_Pressed" ;
VAL_ 811 LongTermReset_B_RqMnu 1 "On" 0 "Off" ;
VAL_ 811 GoTEditMnte_T_RqMnu 15 "Faulty" 14 "NoDataExists" 13 "NotUsed_2" 12 "NotUsed_1" 11 "Minute_55" 10 "Minute_50" 9 "Minute_45" 8 "Minute_40" 7 "Minute_35" 6 "Minute_30" 5 "Minute_25" 4 "Minute_20" 3 "Minute_15" 2 "Minute_10" 1 "Minute_5" 0 "Minute_0" ;
VAL_ 811 GoTEditHr_T_RqMnu 31 "Faulty" 30 "NoDataExists" ;
VAL_ 811 DistToStopover_L_Actl 65535 "Faulty" ;
VAL_ 811 StopoverType_D_Stat 7 "Faulty" 6 "NotUsed_1" 5 "Other" 4 "Work" 3 "Home" 2 "ChargeStation" 1 "FinalDestination" 0 "Null" ;
VAL_ 811 AutoLghtOvrrd_B_RqDrv 1 "Allowed" 0 "NotAllowed" ;
VAL_ 810 VehHorn_B_RqOccAlrt 1 "On" 0 "Off" ;
VAL_ 810 DteCldAcceptData_B_Rq 1 "Yes" 0 "No" ;
VAL_ 810 RmtViewMde_B_Rq 1 "On" 0 "Off" ;
VAL_ 810 ExtLghtDsply_B_StatArb 1 "On" 0 "Off" ;
VAL_ 810 ExtLghtRight_D_RqOta 7 "NotUsed" 6 "PressToOn3" 5 "PressToOff3" 4 "PressToOn2" 3 "PressToOff2" 2 "PressToOn1" 1 "PressToOff1" 0 "Reset" ;
VAL_ 810 ExtLghtRear_D_RqOta 7 "NotUsed" 6 "PressToOn3" 5 "PressToOff3" 4 "PressToOn2" 3 "PressToOff2" 2 "PressToOn1" 1 "PressToOff1" 0 "Reset" ;
VAL_ 810 DteCldCnclRoute_B_Rq 1 "Yes" 0 "No" ;
VAL_ 810 PtRmtRprt_D_Stat 15 "NotUsed_4" 14 "NotUsed_3" 13 "NotUsed_2" 12 "PlugInToMaintain12vBattery" 11 "SettingUpdated" 10 "FastChargeComplete" 9 "ChargeNotOccurring" 8 "OneTimeSocReached" 7 "BatteryTemperatureRemind" 6 "ReducedPerformance" 5 "LimitedPerformance" 4 "ChargeFault" 3 "ChargeComplete" 2 "VehiclePreconditioned" 1 "TripDistanceAchieved" 0 "NoReportRequest" ;
VAL_ 810 ChrgrPncEnbl_D_Rq 3 "NotUsed" 2 "Enable" 1 "Disable" 0 "Null" ;
VAL_ 810 OBCCSerial_D_Rq 3 "PresentAndProvisioned" 2 "PresentAndProvAlertAck" 1 "PresentAndUnprovisioned" 0 "NotPresent" ;
VAL_ 810 ExtLghtLeft_D_RqOta 7 "NotUsed" 6 "PressToOn3" 5 "PressToOff3" 4 "PressToOn2" 3 "PressToOff2" 2 "PressToOn1" 1 "PressToOff1" 0 "Reset" ;
VAL_ 810 ExtLghtFront_D_RqOta 7 "NotUsed" 6 "PressToOn3" 5 "PressToOff3" 4 "PressToOn2" 3 "PressToOff2" 2 "PressToOn1" 1 "PressToOff1" 0 "Reset" ;
VAL_ 810 TlghtTest_D_RqArb 3 "TestEndAcknowledge" 2 "StartTest" 1 "StopTest" 0 "Null" ;
VAL_ 810 ChrgrPncSustn_B_Rq 1 "Active" 0 "Inactive" ;
VAL_ 519 RearDiffLck_Tq_Rq 16383 "Faulty" 16382 "NoDataExists" ;
VAL_ 356 AltFuelMde_B_RqDrv 1 "On" 0 "Off" ;
VAL_ 356 AltFuelFalt_D_Stat 3 "NotUsed" 2 "Fault_MIL" 1 "Fault_NoMIL" 0 "Normal" ;
VAL_ 356 AltFuelOpMde_D_Stat 7 "NotUSed" 6 "AltFuelMde_To_GasMde" 5 "GasMde_To_AltFuelMde" 4 "ForcedAltFuelMde" 3 "AltFuelMde" 2 "ForcedGasMde_AltFuelSysErr" 1 "ForcedGasMde_AltFuelLow" 0 "GasMde" ;
VAL_ 356 AltFuelLvlWarn_D_Actl 7 "DteLevel5Lowest" 6 "DteLevel4" 5 "DteLevel3" 4 "DteLevel2NonMyKey" 3 "DteLevel1MyKey" 2 "VeryLow" 1 "Low" 0 "Ok" ;
VAL_ 356 AltFuelLvl_D_Stat 1 "Fault" 0 "No_Fault" ;
VAL_ 303 DrStatHood_D2_Actl 5 "NotUsed_2" 4 "NotUsed_1" 3 "Disabled" 2 "Ajar" 1 "Closed" 0 "NotDetermined" 7 "Faulty" 6 "NotUsed_3" ;
SIG_GROUP_ 932 Profile1A_SigGroup_HS1_3A4 1 : VehOnSrc2_D_Stat VehOnCtl_D_Stat VehStrtInhbt_D_Stat CanMsg3A4_No_Cnt VehInhbtMde_D_Stat CanMsg3A4_No_Crc RmtCtlBattMntr_B_Falt;
SIG_GROUP_ 885 Profile1A_SigGroup_HS1_375 1 : BattULoChrg_D_RqOta VehStrtInhbt_T_Dsply VehStrtInhbt_D_Dsply OtaActv_D_Stat VehOn_D_RqCld VehOnRqstr_D_Stat VehStrtInhbt_D_RqCld CanMsg375_No_Cnt CanMsg375_No_Crc;
